VERSION "dbc-export 1 2025.20.8"

NS_ :

BS_:

BU_: APP APS DAS EPAS3S EPASTS ESP GTW IBST IDB PARK RADC RCM RCM3 RCU TPMS USM

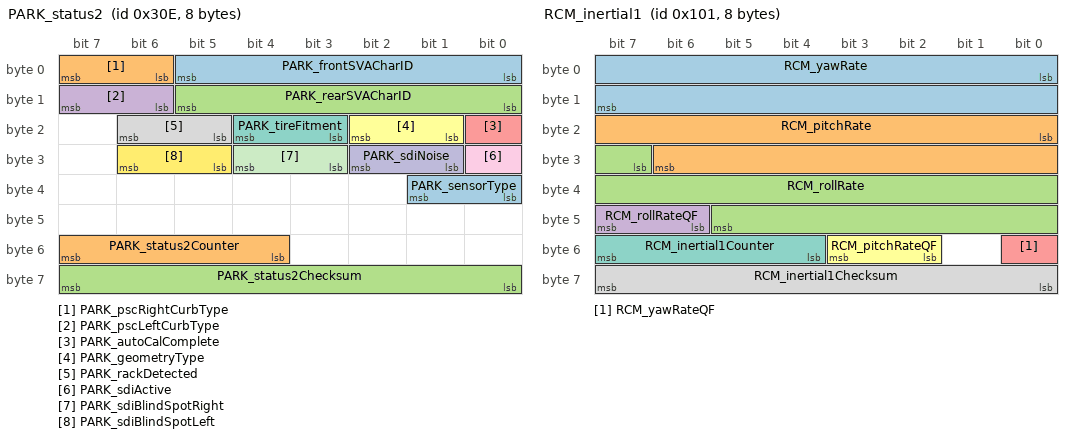
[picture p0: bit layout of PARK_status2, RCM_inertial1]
BO_ 782 PARK_status2: 8 PARK
 SG_ PARK_frontSVACharID : 0|6@1+ (1,0) [0|63] "" Vector__XXX
 SG_ PARK_pscRightCurbType : 6|2@1+ (1,0) [0|3] "" Vector__XXX
 SG_ PARK_rearSVACharID : 8|6@1+ (1,0) [0|63] "" Vector__XXX
 SG_ PARK_pscLeftCurbType : 14|2@1+ (1,0) [0|3] "" Vector__XXX
 SG_ PARK_autoCalComplete : 16|1@1+ (1,0) [0|1] "" Vector__XXX
 SG_ PARK_geometryType : 17|2@1+ (1,0) [0|3] "" Vector__XXX
 SG_ PARK_tireFitment : 19|2@1+ (1,0) [0|2] "" Vector__XXX
 SG_ PARK_rackDetected : 21|2@1+ (1,0) [0|2] "" Vector__XXX
 SG_ PARK_sdiActive : 24|1@1+ (1,0) [0|1] "" Vector__XXX
 SG_ PARK_sdiNoise : 25|2@1+ (1,0) [0|2] "" Vector__XXX
 SG_ PARK_sdiBlindSpotRight : 27|2@1+ (1,0) [0|2] "" Vector__XXX
 SG_ PARK_sdiBlindSpotLeft : 29|2@1+ (1,0) [0|2] "" Vector__XXX
 SG_ PARK_sensorType : 32|2@1+ (1,0) [0|2] "" Vector__XXX
 SG_ PARK_status2Counter : 52|4@1+ (1,0) [0|15] "" Vector__XXX
 SG_ PARK_status2Checksum : 56|8@1+ (1,0) [0|255] "" Vector__XXX

BO_ 894 PARK_warningMatrix: 8 PARK
 SG_ PARK_matrixIndex M : 0|4@1+ (1,0) [0|15] "" Vector__XXX
 SG_ PARK_a001_s1_overTemp m0 : 4|1@1+ (1,0) [0|1] "" Vector__XXX
 SG_ PARK_a002_s1_internalFail m0 : 5|1@1+ (1,0) [0|1] "" Vector__XXX
 SG_ PARK_a003_s1_linCommError m0 : 6|1@1+ (1,0) [0|1] "" Vector__XXX
 SG_ PARK_a004_s1_blocked m0 : 7|1@1+ (1,0) [0|1] "" Vector__XXX
 SG_ PARK_a005_s1_crossTalk m0 : 8|1@1+ (1,0) [0|1] "" Vector__XXX
 SG_ PARK_a006_s2_overTemp m0 : 9|1@1+ (1,0) [0|1] "" Vector__XXX
 SG_ PARK_a007_s2_internalFail m0 : 10|1@1+ (1,0) [0|1] "" Vector__XXX
 SG_ PARK_a008_s2_linCommError m0 : 11|1@1+ (1,0) [0|1] "" Vector__XXX
 SG_ PARK_a009_s2_blocked m0 : 12|1@1+ (1,0) [0|1] "" Vector__XXX
 SG_ PARK_a010_s2_crossTalk m0 : 13|1@1+ (1,0) [0|1] "" Vector__XXX
 SG_ PARK_a011_s3_overTemp m0 : 14|1@1+ (1,0) [0|1] "" Vector__XXX
 SG_ PARK_a012_s3_internalFail m0 : 15|1@1+ (1,0) [0|1] "" Vector__XXX
 SG_ PARK_a013_s3_linCommError m0 : 16|1@1+ (1,0) [0|1] "" Vector__XXX
 SG_ PARK_a014_s3_blocked m0 : 17|1@1+ (1,0) [0|1] "" Vector__XXX
 SG_ PARK_a015_s3_crossTalk m0 : 18|1@1+ (1,0) [0|1] "" Vector__XXX
 SG_ PARK_a016_s4_overTemp m0 : 19|1@1+ (1,0) [0|1] "" Vector__XXX
 SG_ PARK_a017_s4_internalFail m0 : 20|1@1+ (1,0) [0|1] "" Vector__XXX
 SG_ PARK_a018_s4_linCommError m0 : 21|1@1+ (1,0) [0|1] "" Vector__XXX
 SG_ PARK_a019_s4_blocked m0 : 22|1@1+ (1,0) [0|1] "" Vector__XXX
 SG_ PARK_a020_s4_crossTalk m0 : 23|1@1+ (1,0) [0|1] "" Vector__XXX
 SG_ PARK_a021_s5_overTemp m0 : 24|1@1+ (1,0) [0|1] "" Vector__XXX
 SG_ PARK_a022_s5_internalFail m0 : 25|1@1+ (1,0) [0|1] "" Vector__XXX
 SG_ PARK_a023_s5_linCommError m0 : 26|1@1+ (1,0) [0|1] "" Vector__XXX
 SG_ PARK_a024_s5_blocked m0 : 27|1@1+ (1,0) [0|1] "" Vector__XXX
 SG_ PARK_a025_s5_crossTalk m0 : 28|1@1+ (1,0) [0|1] "" Vector__XXX
 SG_ PARK_a026_s6_overTemp m0 : 29|1@1+ (1,0) [0|1] "" Vector__XXX
 SG_ PARK_a027_s6_internalFail m0 : 30|1@1+ (1,0) [0|1] "" Vector__XXX
 SG_ PARK_a028_s6_linCommError m0 : 31|1@1+ (1,0) [0|1] "" Vector__XXX
 SG_ PARK_a029_s6_blocked m0 : 32|1@1+ (1,0) [0|1] "" Vector__XXX
 SG_ PARK_a030_s6_crossTalk m0 : 33|1@1+ (1,0) [0|1] "" Vector__XXX
 SG_ PARK_a031_s7_overTemp m0 : 34|1@1+ (1,0) [0|1] "" Vector__XXX
 SG_ PARK_a032_s7_internalFail m0 : 35|1@1+ (1,0) [0|1] "" Vector__XXX
 SG_ PARK_a033_s7_linCommError m0 : 36|1@1+ (1,0) [0|1] "" Vector__XXX
 SG_ PARK_a034_s7_blocked m0 : 37|1@1+ (1,0) [0|1] "" Vector__XXX
 SG_ PARK_a035_s7_crossTalk m0 : 38|1@1+ (1,0) [0|1] "" Vector__XXX
 SG_ PARK_a036_s8_overTemp m0 : 39|1@1+ (1,0) [0|1] "" Vector__XXX
 SG_ PARK_a037_s8_internalFail m0 : 40|1@1+ (1,0) [0|1] "" Vector__XXX
 SG_ PARK_a038_s8_linCommError m0 : 41|1@1+ (1,0) [0|1] "" Vector__XXX
 SG_ PARK_a039_s8_blocked m0 : 42|1@1+ (1,0) [0|1] "" Vector__XXX
 SG_ PARK_a040_s8_crossTalk m0 : 43|1@1+ (1,0) [0|1] "" Vector__XXX
 SG_ PARK_a041_s9_overTemp m0 : 44|1@1+ (1,0) [0|1] "" Vector__XXX
 SG_ PARK_a042_s9_internalFail m0 : 45|1@1+ (1,0) [0|1] "" Vector__XXX
 SG_ PARK_a043_s9_linCommError m0 : 46|1@1+ (1,0) [0|1] "" Vector__XXX
 SG_ PARK_a044_s9_blocked m0 : 47|1@1+ (1,0) [0|1] "" Vector__XXX
 SG_ PARK_a045_s9_crossTalk m0 : 48|1@1+ (1,0) [0|1] "" Vector__XXX
 SG_ PARK_a046_s10_overTemp m0 : 49|1@1+ (1,0) [0|1] "" Vector__XXX
 SG_ PARK_a047_s10_internalFail m0 : 50|1@1+ (1,0) [0|1] "" Vector__XXX
 SG_ PARK_a048_s10_linCommError m0 : 51|1@1+ (1,0) [0|1] "" Vector__XXX
 SG_ PARK_a049_s10_blocked m0 : 52|1@1+ (1,0) [0|1] "" Vector__XXX
 SG_ PARK_a050_s10_crossTalk m0 : 53|1@1+ (1,0) [0|1] "" Vector__XXX
 SG_ PARK_a051_s11_overTemp m0 : 54|1@1+ (1,0) [0|1] "" Vector__XXX
 SG_ PARK_a052_s11_internalFail m0 : 55|1@1+ (1,0) [0|1] "" Vector__XXX
 SG_ PARK_a053_s11_linCommError m0 : 56|1@1+ (1,0) [0|1] "" Vector__XXX
 SG_ PARK_a054_s11_blocked m0 : 57|1@1+ (1,0) [0|1] "" Vector__XXX
 SG_ PARK_a055_s11_crossTalk m0 : 58|1@1+ (1,0) [0|1] "" Vector__XXX
 SG_ PARK_a056_s12_overTemp m0 : 59|1@1+ (1,0) [0|1] "" Vector__XXX
 SG_ PARK_a057_s12_internalFail m0 : 60|1@1+ (1,0) [0|1] "" Vector__XXX
 SG_ PARK_a058_s12_linCommError m0 : 61|1@1+ (1,0) [0|1] "" Vector__XXX
 SG_ PARK_a059_s12_blocked m0 : 62|1@1+ (1,0) [0|1] "" Vector__XXX
 SG_ PARK_a060_s12_crossTalk m0 : 63|1@1+ (1,0) [0|1] "" Vector__XXX
 SG_ PARK_a061_ecuUnderVoltage m1 : 4|1@1+ (1,0) [0|1] "" Vector__XXX
 SG_ PARK_a062_ecuOverVoltage m1 : 5|1@1+ (1,0) [0|1] "" Vector__XXX
 SG_ PARK_a063_sensorVoltage m1 : 6|1@1+ (1,0) [0|1] "" Vector__XXX
 SG_ PARK_a064_ecuFault m1 : 7|1@1+ (1,0) [0|1] "" Vector__XXX
 SG_ PARK_a065_crcFault m1 : 8|1@1+ (1,0) [0|1] "" Vector__XXX
 SG_ PARK_a066_calibrationMissing m1 : 9|1@1+ (1,0) [0|1] "" Vector__XXX
 SG_ PARK_a067_privateCANBusOff m1 : 10|1@1+ (1,0) [0|1] "" Vector__XXX
 SG_ PARK_a068_hardwareWatchDog m1 : 11|1@1+ (1,0) [0|1] "" Vector__XXX
 SG_ PARK_a069_dasMia m1 : 12|1@1+ (1,0) [0|1] "" Vector__XXX
 SG_ PARK_a070_sccmMia m1 : 13|1@1+ (1,0) [0|1] "" Vector__XXX
 SG_ PARK_a071_diMia m1 : 14|1@1+ (1,0) [0|1] "" Vector__XXX
 SG_ PARK_a072_epasMia m1 : 15|1@1+ (1,0) [0|1] "" Vector__XXX
 SG_ PARK_a073_epbMia m1 : 16|1@1+ (1,0) [0|1] "" Vector__XXX
 SG_ PARK_a074_espMia m1 : 17|1@1+ (1,0) [0|1] "" Vector__XXX
 SG_ PARK_a075_rcmMia m1 : 18|1@1+ (1,0) [0|1] "" Vector__XXX
 SG_ PARK_a076_vcFrontMia m1 : 19|1@1+ (1,0) [0|1] "" Vector__XXX
 SG_ PARK_a077_dasError m1 : 20|1@1+ (1,0) [0|1] "" Vector__XXX
 SG_ PARK_a078_diError m1 : 21|1@1+ (1,0) [0|1] "" Vector__XXX
 SG_ PARK_a079_epasError m1 : 22|1@1+ (1,0) [0|1] "" Vector__XXX
 SG_ PARK_a080_epbError m1 : 23|1@1+ (1,0) [0|1] "" Vector__XXX
 SG_ PARK_a081_espError m1 : 24|1@1+ (1,0) [0|1] "" Vector__XXX
 SG_ PARK_a082_rcmError m1 : 25|1@1+ (1,0) [0|1] "" Vector__XXX
 SG_ PARK_a083_vcFrontError m1 : 26|1@1+ (1,0) [0|1] "" Vector__XXX
 SG_ PARK_a084_sccmError m1 : 27|1@1+ (1,0) [0|1] "" Vector__XXX
 SG_ PARK_a085_watchdogReset m1 : 28|1@1+ (1,0) [0|1] "" Vector__XXX
 SG_ PARK_a086_nvmFault m1 : 29|1@1+ (1,0) [0|1] "" Vector__XXX
 SG_ PARK_a087_sensorMismatchError m1 : 30|1@1+ (1,0) [0|1] "" Vector__XXX

BO_ 1365 RADC_alertLog: 8 RADC
 SG_ RADC_alertID M : 0|6@1+ (1,0) [0|63] "" Vector__XXX
 SG_ RADC_alertState : 15|1@1+ (1,0) [0|1] "" Vector__XXX
 SG_ RADC_a002_ecuAdcErrType m2 : 16|8@1+ (1,0) [0|255] "" Vector__XXX
 SG_ RADC_a008_interLockErrType m8 : 16|8@1+ (1,0) [0|255] "" Vector__XXX
 SG_ RADC_a011_ecuMcemErrType m11 : 16|8@1+ (1,0) [0|255] "" Vector__XXX
 SG_ RADC_a013_ecuWdgErrType m13 : 16|8@1+ (1,0) [0|255] "" Vector__XXX
 SG_ RADC_a016_adcOverVoltType m16 : 16|8@1+ (1,0) [0|255] "" Vector__XXX
 SG_ RADC_a016_adcVoltage m16 : 24|6@1+ (0.1,0) [0|6.3] "v" Vector__XXX
 SG_ RADC_a017_adcUnderVoltType m17 : 16|8@1+ (1,0) [0|255] "" Vector__XXX
 SG_ RADC_a017_adcVoltage m17 : 24|6@1+ (0.1,0) [0|6.3] "v" Vector__XXX
 SG_ RADC_a019_internalSWFaultType m19 : 16|8@1+ (1,0) [0|255] "" Vector__XXX
 SG_ RADC_a019_internalSWFaultCoreID m19 : 24|4@1+ (1,0) [0|15] "" Vector__XXX
 SG_ RADC_a020_ecuTemp m20 : 16|16@1+ (0.1,-44) [-44|6509.5] "deg" Vector__XXX
 SG_ RADC_a023_ecuTemp m23 : 16|16@1+ (0.1,-44) [-44|6509.5] "deg" Vector__XXX
 SG_ RADC_a025_ecuVoltage m25 : 16|8@1+ (0.1,0) [0|25.5] "v" Vector__XXX
 SG_ RADC_a026_ecuVoltage m26 : 16|8@1+ (0.1,0) [0|25.5] "v" Vector__XXX
 SG_ RADC_a027_nvmFailureType m27 : 16|8@1+ (1,0) [0|255] "" Vector__XXX
 SG_ RADC_a028_rfComRegCheckFail m28 : 16|8@1+ (1,0) [0|255] "" Vector__XXX
 SG_ RADC_a029_rhcChirpMonErrType m29 : 16|8@1+ (1,0) [0|255] "" Vector__XXX
 SG_ RADC_a029_rhcRxLongTermErrType m29 : 24|8@1+ (1,0) [0|255] "" Vector__XXX
 SG_ RADC_a029_rhcRxErrType m29 : 32|8@1+ (1,0) [0|255] "" Vector__XXX
 SG_ RADC_a029_rhcVcoPowerErrType m29 : 40|8@1+ (1,0) [0|255] "" Vector__XXX
 SG_ RADC_a029_rhcSp1ErrType m29 : 48|8@1+ (1,0) [0|255] "" Vector__XXX
 SG_ RADC_a029_rhcFdcErrType m29 : 56|8@1+ (1,0) [0|255] "" Vector__XXX
 SG_ RADC_a030_rspErrType m30 : 16|8@1+ (1,0) [0|255] "" Vector__XXX
 SG_ RADC_a031_horizMisalignAngle m31 : 16|8@1+ (0.001953125,-0.25) [-0.25|0.248046875] "rad" Vector__XXX
 SG_ RADC_a031_vertMisalignAngle m31 : 24|12@1+ (0.0001220703125,-0.25) [-0.25|0.249877929688] "rad" Vector__XXX
 SG_ RADC_a032_blockageType m32 : 16|8@1+ (1,0) [0|255] "" Vector__XXX
 SG_ RADC_a032_block_SPMBlockageState m32 : 24|3@1+ (1,0) [0|7] "" Vector__XXX
 SG_ RADC_a032_block_dummy m32 : 27|3@1+ (1,0) [0|7] "" Vector__XXX
 SG_ RADC_a032_block_SPMSelfTestState m32 : 30|2@1+ (1,0) [0|3] "" Vector__XXX
 SG_ RADC_a032_block_ucEstiRange m32 : 32|8@1+ (1,0) [0|255] "m" Vector__XXX
 SG_ RADC_a032_block_ucEstiRangeConf m32 : 40|8@1+ (1,0) [0|255] "" Vector__XXX
 SG_ RADC_a032_block_ucEstiRangeProb m32 : 48|8@1+ (1,0) [0|255] "" Vector__XXX
 SG_ RADC_a032_block_ucTimeoutBlkConf m32 : 56|8@1+ (1,0) [0|255] "" Vector__XXX
 SG_ RADC_a035_msgId m35 : 16|12@1+ (1,0) [0|4095] "" Vector__XXX
 SG_ RADC_a036_msgId m36 : 16|12@1+ (1,0) [0|4095] "" Vector__XXX
 SG_ RADC_a037_msgId m37 : 16|12@1+ (1,0) [0|4095] "" Vector__XXX
 SG_ RADC_a038_msgId m38 : 16|12@1+ (1,0) [0|4095] "" Vector__XXX
 SG_ RADC_a039_msgId m39 : 16|12@1+ (1,0) [0|4095] "" Vector__XXX
 SG_ RADC_a040_msgId m40 : 16|12@1+ (1,0) [0|4095] "" Vector__XXX
 SG_ RADC_a041_vinErrType m41 : 16|4@1+ (1,0) [0|15] "" Vector__XXX
 SG_ RADC_a041_vinErrExp m41 : 20|16@1+ (1,0) [0|65535] "" Vector__XXX
 SG_ RADC_a041_vinErrRx m41 : 36|16@1+ (1,0) [0|65535] "" Vector__XXX
 SG_ RADC_a041_msgId m41 : 52|12@1+ (1,0) [0|4095] "" Vector__XXX
 SG_ RADC_a042_carConfigErrType m42 : 16|4@1+ (1,0) [0|15] "" Vector__XXX
 SG_ RADC_a042_carConfigErrExp m42 : 20|16@1+ (1,0) [0|65535] "" Vector__XXX
 SG_ RADC_a042_carConfigErrRx m42 : 36|16@1+ (1,0) [0|65535] "" Vector__XXX
 SG_ RADC_a042_msgId m42 : 52|12@1+ (1,0) [0|4095] "" Vector__XXX
 SG_ RADC_a043_inertialSignalsErrType m43 : 16|4@1+ (1,0) [0|15] "" Vector__XXX
 SG_ RADC_a043_inertialSignalsErrExp m43 : 20|16@1+ (1,0) [0|65535] "" Vector__XXX
 SG_ RADC_a043_inertialSignalsErrRx m43 : 36|16@1+ (1,0) [0|65535] "" Vector__XXX
 SG_ RADC_a043_msgId m43 : 52|12@1+ (1,0) [0|4095] "" Vector__XXX
 SG_ RADC_a044_stwAngleErrType m44 : 16|4@1+ (1,0) [0|15] "" Vector__XXX
 SG_ RADC_a044_stwAngleErrExp m44 : 20|16@1+ (1,0) [0|65535] "" Vector__XXX
 SG_ RADC_a044_stwAngleErrRx m44 : 36|16@1+ (1,0) [0|65535] "" Vector__XXX
 SG_ RADC_a044_msgId m44 : 52|12@1+ (1,0) [0|4095] "" Vector__XXX
 SG_ RADC_a045_vehicleStateErrType m45 : 16|4@1+ (1,0) [0|15] "" Vector__XXX
 SG_ RADC_a045_vehicleStateErrExp m45 : 20|16@1+ (1,0) [0|65535] "" Vector__XXX
 SG_ RADC_a045_vehicleStateErrRx m45 : 36|16@1+ (1,0) [0|65535] "" Vector__XXX
 SG_ RADC_a045_msgId m45 : 52|12@1+ (1,0) [0|4095] "" Vector__XXX
 SG_ RADC_a046_wheelSpeedsErrType m46 : 16|4@1+ (1,0) [0|15] "" Vector__XXX
 SG_ RADC_a046_wheelSpeedsErrExp m46 : 20|16@1+ (1,0) [0|65535] "" Vector__XXX
 SG_ RADC_a046_wheelSpeedsErrRx m46 : 36|16@1+ (1,0) [0|65535] "" Vector__XXX
 SG_ RADC_a046_msgId m46 : 52|12@1+ (1,0) [0|4095] "" Vector__XXX
 SG_ RADC_a047_chassisTypeExp m47 : 16|8@1+ (1,0) [0|255] "" Vector__XXX
 SG_ RADC_a047_chassisTypeRx m47 : 24|8@1+ (1,0) [0|255] "" Vector__XXX
 SG_ RADC_a048_airSuspensionExp m48 : 16|8@1+ (1,0) [0|255] "" Vector__XXX
 SG_ RADC_a048_airSuspensionRx m48 : 24|8@1+ (1,0) [0|255] "" Vector__XXX
 SG_ RADC_a049_fourWheelDriveExp m49 : 16|8@1+ (1,0) [0|255] "" Vector__XXX
 SG_ RADC_a049_fourWheelDriveRx m49 : 24|8@1+ (1,0) [0|255] "" Vector__XXX
 SG_ RADC_a050_countryExp m50 : 16|16@1+ (1,0) [0|65535] "" Vector__XXX
 SG_ RADC_a050_countryRx m50 : 32|16@1+ (1,0) [0|65535] "" Vector__XXX
 SG_ RADC_a051_epasTypeExp m51 : 16|8@1+ (1,0) [0|255] "" Vector__XXX
 SG_ RADC_a051_epasTypeRx m51 : 24|8@1+ (1,0) [0|255] "" Vector__XXX
 SG_ RADC_a052_radarPositionExp m52 : 16|8@1+ (1,0) [0|255] "" Vector__XXX
 SG_ RADC_a052_radarPositionRx m52 : 24|8@1+ (1,0) [0|255] "" Vector__XXX
 SG_ RADC_a054_block_ucObjLossProb m54 : 16|8@1+ (1,0) [0|255] "" Vector__XXX
 SG_ RADC_a054_block_ucObjLossConf m54 : 24|8@1+ (1,0) [0|255] "" Vector__XXX
 SG_ RADC_a054_block_ucOverallProb m54 : 32|8@1+ (1,0) [0|255] "" Vector__XXX
 SG_ RADC_a054_block_ucOverallConf m54 : 40|8@1+ (1,0) [0|255] "" Vector__XXX
 SG_ RADC_a054_block_RoadbeamTimeCnt m54 : 48|16@1+ (1,0) [0|65535] "s" Vector__XXX
 SG_ RADC_a055_block_usTimeoutWayCnt m55 : 16|16@1+ (1,0) [0|65535] "m" Vector__XXX
 SG_ RADC_a055_block_ucTimeoutTimeCnt m55 : 32|8@1+ (1,0) [0|255] "s" Vector__XXX
 SG_ RADC_a055_bblock_ucTimeoutBlkPro m55 : 40|8@1+ (1,0) [0|255] "" Vector__XXX
 SG_ RADC_a055_block_usFullBlkTimer m55 : 48|16@1+ (1,0) [0|65535] "s" Vector__XXX

BO_ 1282 RADC_alertMatrix0: 8 RADC
 SG_ RADC_a001_can1BusOff : 1|1@1+ (1,0) [0|1] "" Vector__XXX
 SG_ RADC_a002_ecuAdcError : 2|1@1+ (1,0) [0|1] "" Vector__XXX
 SG_ RADC_a003_ecuBistDisabled : 3|1@1+ (1,0) [0|1] "" Vector__XXX
 SG_ RADC_a004_ecuCrcHwError : 4|1@1+ (1,0) [0|1] "" Vector__XXX
 SG_ RADC_a005_ecuEcuMError : 5|1@1+ (1,0) [0|1] "" Vector__XXX
 SG_ RADC_a006_ecuFimError : 6|1@1+ (1,0) [0|1] "" Vector__XXX
 SG_ RADC_a007_ecuGptCheckError : 7|1@1+ (1,0) [0|1] "" Vector__XXX
 SG_ RADC_a008_ecuHwSwInterlock : 8|1@1+ (1,0) [0|1] "" Vector__XXX
 SG_ RADC_a009_plantModeActive : 9|1@1+ (1,0) [0|1] "" Vector__XXX
 SG_ RADC_a010_ecuIoHwAbError : 10|1@1+ (1,0) [0|1] "" Vector__XXX
 SG_ RADC_a011_ecuMcemError : 11|1@1+ (1,0) [0|1] "" Vector__XXX
 SG_ RADC_a012_ecuSpiError : 12|1@1+ (1,0) [0|1] "" Vector__XXX
 SG_ RADC_a013_ecuWdgError : 13|1@1+ (1,0) [0|1] "" Vector__XXX
 SG_ RADC_a014_fctSelfTestNotDone : 14|1@1+ (1,0) [0|1] "" Vector__XXX
 SG_ RADC_a015_fctSenInterference : 15|1@1+ (1,0) [0|1] "" Vector__XXX
 SG_ RADC_a016_adcOverVolt : 16|1@1+ (1,0) [0|1] "" Vector__XXX
 SG_ RADC_a017_adcUnderVolt : 17|1@1+ (1,0) [0|1] "" Vector__XXX
 SG_ RADC_a018_internalHardwareFault : 18|1@1+ (1,0) [0|1] "" Vector__XXX
 SG_ RADC_a019_internalSoftwareFault : 19|1@1+ (1,0) [0|1] "" Vector__XXX
 SG_ RADC_a020_overTemp : 20|1@1+ (1,0) [0|1] "" Vector__XXX
 SG_ RADC_a021_overTempCrit : 21|1@1+ (1,0) [0|1] "" Vector__XXX
 SG_ RADC_a022_tempImplausible : 22|1@1+ (1,0) [0|1] "" Vector__XXX
 SG_ RADC_a023_underTemp : 23|1@1+ (1,0) [0|1] "" Vector__XXX
 SG_ RADC_a024_underTempCrit : 24|1@1+ (1,0) [0|1] "" Vector__XXX
 SG_ RADC_a025_overVoltage : 25|1@1+ (1,0) [0|1] "" Vector__XXX
 SG_ RADC_a026_underVoltage : 26|1@1+ (1,0) [0|1] "" Vector__XXX
 SG_ RADC_a027_nvmFailure : 27|1@1+ (1,0) [0|1] "" Vector__XXX
 SG_ RADC_a028_rfChipError : 28|1@1+ (1,0) [0|1] "" Vector__XXX
 SG_ RADC_a029_rhcError : 29|1@1+ (1,0) [0|1] "" Vector__XXX
 SG_ RADC_a030_rspError : 30|1@1+ (1,0) [0|1] "" Vector__XXX
 SG_ RADC_a031_sensorMisaligned : 31|1@1+ (1,0) [0|1] "" Vector__XXX
 SG_ RADC_a032_sensorBlocked : 32|1@1+ (1,0) [0|1] "" Vector__XXX
 SG_ RADC_a033_sensorNeverAligned : 33|1@1+ (1,0) [0|1] "" Vector__XXX
 SG_ RADC_a034_vehDynamicsError : 34|1@1+ (1,0) [0|1] "" Vector__XXX
 SG_ RADC_a035_vinMIA : 35|1@1+ (1,0) [0|1] "" Vector__XXX
 SG_ RADC_a036_carConfigMIA : 36|1@1+ (1,0) [0|1] "" Vector__XXX
 SG_ RADC_a037_inertialSignalsMIA : 37|1@1+ (1,0) [0|1] "" Vector__XXX
 SG_ RADC_a038_steeringWheelAngleMIA : 38|1@1+ (1,0) [0|1] "" Vector__XXX
 SG_ RADC_a039_vehicleStateMIA : 39|1@1+ (1,0) [0|1] "" Vector__XXX
 SG_ RADC_a040_wheelSpeedsMIA : 40|1@1+ (1,0) [0|1] "" Vector__XXX
 SG_ RADC_a041_vinErr : 41|1@1+ (1,0) [0|1] "" Vector__XXX
 SG_ RADC_a042_carConfigErr : 42|1@1+ (1,0) [0|1] "" Vector__XXX
 SG_ RADC_a043_inertialSignalsErr : 43|1@1+ (1,0) [0|1] "" Vector__XXX
 SG_ RADC_a044_steeringWheelAngleErr : 44|1@1+ (1,0) [0|1] "" Vector__XXX
 SG_ RADC_a045_vehicleStateErr : 45|1@1+ (1,0) [0|1] "" Vector__XXX
 SG_ RADC_a046_wheelSpeedsErr : 46|1@1+ (1,0) [0|1] "" Vector__XXX
 SG_ RADC_a047_mismatchChassisType : 47|1@1+ (1,0) [0|1] "" Vector__XXX
 SG_ RADC_a048_mismatchAirSuspension : 48|1@1+ (1,0) [0|1] "" Vector__XXX
 SG_ RADC_a049_mismatchFourWheelDrive : 49|1@1+ (1,0) [0|1] "" Vector__XXX
 SG_ RADC_a050_mismatchCountry : 50|1@1+ (1,0) [0|1] "" Vector__XXX
 SG_ RADC_a051_mismatchEPASType : 51|1@1+ (1,0) [0|1] "" Vector__XXX
 SG_ RADC_a052_mismatcRadPos : 52|1@1+ (1,0) [0|1] "" Vector__XXX
 SG_ RADC_a053_emError : 53|1@1+ (1,0) [0|1] "" Vector__XXX
 SG_ RADC_a054_blockageInfo_Frame_1 : 54|1@1+ (1,0) [0|1] "" Vector__XXX
 SG_ RADC_a055_blockageInfo_Frame_2 : 55|1@1+ (1,0) [0|1] "" Vector__XXX

BO_ 1329 RADC_info: 8 RADC
 SG_ RADC_infoIndex M : 0|8@1+ (1,0) [0|255] "" Vector__XXX
 SG_ RADC_infoBuildType m10 : 8|8@1+ (1,0) [0|255] "" Vector__XXX
 SG_ RADC_infoBuildConfigID m10 : 16|16@1+ (1,0) [0|65535] "" Vector__XXX
 SG_ RADC_infoHardwareID m10 : 32|16@1+ (1,0) [0|65535] "" Vector__XXX
 SG_ RADC_infoComponentID m10 : 48|16@1+ (1,0) [0|65535] "" Vector__XXX
 SG_ RADC_infoPcbaID m11 : 16|8@1+ (1,0) [0|255] "" Vector__XXX
 SG_ RADC_infoAssemblyID m11 : 24|8@1+ (1,0) [0|255] "" Vector__XXX
 SG_ RADC_infoUsageID m11 : 32|16@1+ (1,0) [0|65535] "" Vector__XXX
 SG_ RADC_infoSubUsageID m11 : 48|16@1+ (1,0) [0|65535] "" Vector__XXX
 SG_ RADC_infoApplicationCRC m13 : 32|32@1+ (1,0) [0|4294967295] "" Vector__XXX
 SG_ RADC_infoPlatformType m19 : 8|8@1+ (1,0) [0|255] "" Vector__XXX
 SG_ RADC_infoMajorVersion m19 : 16|8@1+ (1,0) [0|255] "" Vector__XXX
 SG_ RADC_infoBranchOrigin m19 : 24|8@1+ (1,0) [0|255] "" Vector__XXX
 SG_ RADC_infoMaturity m19 : 32|8@1+ (1,0) [0|255] "" Vector__XXX
 SG_ RADC_infoHardwareRevision m19 : 40|8@1+ (1,0) [0|255] "" Vector__XXX
 SG_ RADC_infoBootUdsProtoVersion m20 : 8|8@1+ (1,0) [0|255] "" Vector__XXX
 SG_ RADC_infoBootloaderCRC m20 : 32|32@1+ (1,0) [0|4294967295] "" Vector__XXX

BO_ 1252 RCM3_alertLog: 8 RCM3
 SG_ RCM3_alertID : 0|1@1+ (1,0) [0|1] "" Vector__XXX
 SG_ RCM3_alertState : 15|1@1+ (1,0) [0|1] "" Vector__XXX

BO_ 1010 RCM3_alertMatrix: 8 RCM3
 SG_ RCM3_matrixIndex M : 0|4@1+ (1,0) [0|15] "" Vector__XXX
 SG_ RCM3_a001_LVPowerLossDetected m0 : 4|1@1+ (1,0) [0|1] "" Vector__XXX

BO_ 257 RCM_inertial1: 8 RCM
 SG_ RCM_yawRate : 0|16@1- (0.0001,0) [-3.2766|3.2766] "rad/s" Vector__XXX
 SG_ RCM_pitchRate : 16|15@1- (0.00025,0) [-4.096|4.09575] "rad/s" Vector__XXX
 SG_ RCM_rollRate : 31|15@1- (0.00025,0) [-4.096|4.09575] "rad/s" Vector__XXX
 SG_ RCM_rollRateQF : 46|2@1+ (1,0) [0|3] "" Vector__XXX
 SG_ RCM_yawRateQF : 48|1@1+ (1,0) [0|1] "" Vector__XXX
 SG_ RCM_pitchRateQF : 50|2@1+ (1,0) [0|3] "" Vector__XXX
 SG_ RCM_inertial1Counter : 52|4@1+ (1,0) [0|15] "" Vector__XXX
 SG_ RCM_inertial1Checksum : 56|8@1+ (1,0) [0|255] "" Vector__XXX

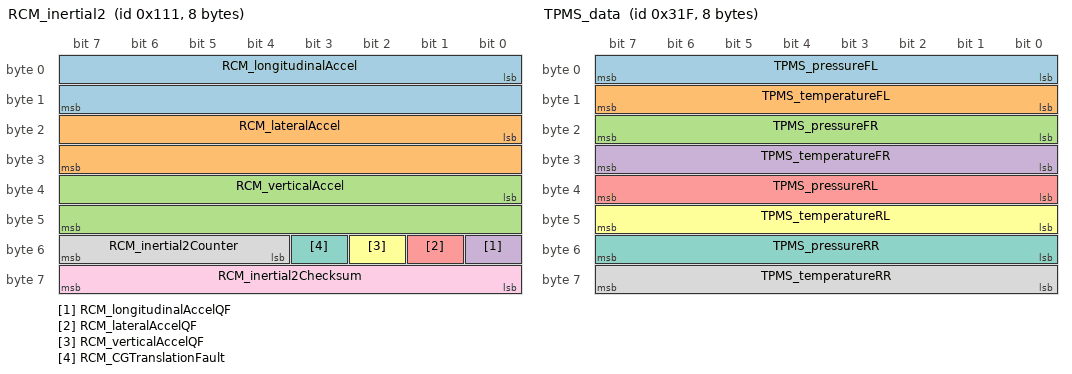
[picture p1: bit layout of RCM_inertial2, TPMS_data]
BO_ 273 RCM_inertial2: 8 RCM
 SG_ RCM_longitudinalAccel : 0|16@1- (0.00125,0) [-40.9575|40.9575] "m/s^2" Vector__XXX
 SG_ RCM_lateralAccel : 16|16@1- (0.00125,0) [-40.9575|40.9575] "m/s^2" Vector__XXX
 SG_ RCM_verticalAccel : 32|16@1- (0.00125,0) [-40.9575|39.2] "m/s^2" Vector__XXX
 SG_ RCM_longitudinalAccelQF : 48|1@1+ (1,0) [0|1] "" Vector__XXX
 SG_ RCM_lateralAccelQF : 49|1@1+ (1,0) [0|1] "" Vector__XXX
 SG_ RCM_verticalAccelQF : 50|1@1+ (1,0) [0|1] "" Vector__XXX
 SG_ RCM_CGTranslationFault : 51|1@1+ (1,0) [0|1] "" Vector__XXX
 SG_ RCM_inertial2Counter : 52|4@1+ (1,0) [0|15] "" Vector__XXX
 SG_ RCM_inertial2Checksum : 56|8@1+ (1,0) [0|255] "" Vector__XXX

BO_ 849 RCM_info: 8 RCM
 SG_ RCM_infoIndex M : 0|8@1+ (1,0) [0|255] "" Vector__XXX
 SG_ RCM_infoBuildType m10 : 8|8@1+ (1,0) [0|255] "" Vector__XXX
 SG_ RCM_infoComponentID m10 : 48|16@1+ (1,0) [0|65535] "" Vector__XXX
 SG_ RCM_infoPcbaID m11 : 16|8@1+ (1,0) [0|255] "" Vector__XXX
 SG_ RCM_infoAssemblyID m11 : 24|8@1+ (1,0) [0|255] "" Vector__XXX
 SG_ RCM_infoUsageID m11 : 32|16@1+ (1,0) [0|65535] "" Vector__XXX
 SG_ RCM_infoApplicationCRC m13 : 32|32@1+ (1,0) [0|4294967295] "" Vector__XXX
 SG_ RCM_infoBootUdsProtoVersion m20 : 8|8@1+ (1,0) [0|255] "" Vector__XXX
 SG_ RCM_infoBootloaderCRC m20 : 32|32@1+ (1,0) [0|4294967295] "" Vector__XXX
 SG_ RCM_infoAlgoCalID m22 : 8|8@1+ (1,0) [0|255] "" Vector__XXX
 SG_ RCM_infoVariantCRC m22 : 32|32@1+ (1,0) [0|4294967295] "" Vector__XXX

BO_ 529 RCM_status: 6 RCM
 SG_ RCM_statusChecksum : 0|8@1+ (1,0) [0|255] "" Vector__XXX
 SG_ RCM_statusCounter : 8|4@1+ (1,0) [0|15] "" Vector__XXX
 SG_ RCM_armStatus : 12|2@1+ (1,0) [0|2] "" Vector__XXX
 SG_ RCM_warningIndicatorState : 14|2@1+ (1,0) [0|2] "" Vector__XXX
 SG_ RCM_passAirbagIndicatorRequest : 16|2@1+ (1,0) [0|2] "" Vector__XXX
 SG_ RCM_airbagCutoffStatus : 18|2@1+ (1,0) [0|2] "" Vector__XXX
 SG_ RCM_alrSwitchStatus : 20|2@1+ (1,0) [0|2] "" Vector__XXX
 SG_ RCM_vinLearnFlag : 22|2@1+ (1,0) [0|2] "" Vector__XXX
 SG_ RCM_seatTrackPositionDrvr : 24|2@1+ (1,0) [0|2] "" Vector__XXX
 SG_ RCM_seatTrackPositionPass : 26|2@1+ (1,0) [0|2] "" Vector__XXX
 SG_ RCM_edr1State : 28|2@1+ (1,0) [0|3] "" Vector__XXX
 SG_ RCM_edr2State : 30|2@1+ (1,0) [0|3] "" Vector__XXX
 SG_ RCM_keepPowerReason : 32|4@1+ (1,0) [0|15] "" Vector__XXX
 SG_ RCM_imuOffsetLearnState : 36|2@1+ (1,0) [0|3] "" Vector__XXX
 SG_ RCM_edr3State : 38|2@1+ (1,0) [0|3] "" Vector__XXX
 SG_ RCM_driverOrientationInitStatus : 40|3@1+ (1,0) [0|6] "" Vector__XXX
 SG_ RCM_occupantClassificationSource : 43|1@1+ (1,0) [0|1] "" Vector__XXX
 SG_ RCM_pedProEDR1State : 44|2@1+ (1,0) [0|3] "" Vector__XXX
 SG_ RCM_pedProEDR2State : 46|2@1+ (1,0) [0|3] "" Vector__XXX

BO_ 831 RCU_info: 8 RCU
 SG_ RCU_infoIndex M : 0|8@1+ (1,0) [0|255] "" Vector__XXX
 SG_ RCU_infoPcbaID m11 : 16|8@1+ (1,0) [0|255] "" Vector__XXX
 SG_ RCU_infoAssemblyID m11 : 24|8@1+ (1,0) [0|255] "" Vector__XXX
 SG_ RCU_infoUsageID m11 : 32|16@1+ (1,0) [0|65535] "" Vector__XXX
 SG_ RCU_infoSubUsageID m11 : 48|16@1+ (1,0) [0|65535] "" Vector__XXX

BO_ 879 TPMS_StatusC: 8 TPMS
 SG_ TPMS_c_globalHardWarning : 0|1@1+ (1,0) [0|1] "" Vector__XXX
 SG_ TPMS_c_globalSoftWarning : 1|1@1+ (1,0) [0|1] "" Vector__XXX
 SG_ TPMS_systemMalfunction : 2|1@1+ (1,0) [0|1] "" Vector__XXX
 SG_ TPMS_WA_version : 3|1@1+ (1,0) [0|1] "" Vector__XXX
 SG_ TPMS_globalDeltaPressure : 4|1@1+ (1,0) [0|1] "" Vector__XXX
 SG_ TPMS_newSensorLearnt : 5|3@1+ (1,0) [0|7] "" Vector__XXX
 SG_ TPMS_softWarningRR : 8|1@1+ (1,0) [0|1] "" Vector__XXX
 SG_ TPMS_hardWarningRR : 9|1@1+ (1,0) [0|1] "" Vector__XXX
 SG_ TPMS_softWarningRL : 10|1@1+ (1,0) [0|1] "" Vector__XXX
 SG_ TPMS_hardWarningRL : 11|1@1+ (1,0) [0|1] "" Vector__XXX
 SG_ TPMS_softWarningFR : 12|1@1+ (1,0) [0|1] "" Vector__XXX
 SG_ TPMS_hardWarningFR : 13|1@1+ (1,0) [0|1] "" Vector__XXX
 SG_ TPMS_softWarningFL : 14|1@1+ (1,0) [0|1] "" Vector__XXX
 SG_ TPMS_hardWarningFL : 15|1@1+ (1,0) [0|1] "" Vector__XXX
 SG_ TPMS_learningStatus : 16|2@1+ (1,0) [0|3] "" Vector__XXX
 SG_ TPMS_localisationStatus : 18|2@1+ (1,0) [0|3] "" Vector__XXX
 SG_ TPMS_deltaPressWarningFL : 20|1@1+ (1,0) [0|1] "" Vector__XXX
 SG_ TPMS_deltaPressWarningFR : 21|1@1+ (1,0) [0|1] "" Vector__XXX
 SG_ TPMS_deltaPressWarningRL : 22|1@1+ (1,0) [0|1] "" Vector__XXX
 SG_ TPMS_deltaPressWarningRR : 23|1@1+ (1,0) [0|1] "" Vector__XXX
 SG_ TPMS_sensorNoResponseFL : 24|1@1+ (1,0) [0|1] "" Vector__XXX
 SG_ TPMS_sensorNoResponseFR : 25|1@1+ (1,0) [0|1] "" Vector__XXX
 SG_ TPMS_sensorNoResponseRL : 26|1@1+ (1,0) [0|1] "" Vector__XXX
 SG_ TPMS_sensorNoResponseRR : 27|1@1+ (1,0) [0|1] "" Vector__XXX
 SG_ TPMS_sensorThermShutdownFL : 28|1@1+ (1,0) [0|1] "" Vector__XXX
 SG_ TPMS_sensorThermShutdownFR : 29|1@1+ (1,0) [0|1] "" Vector__XXX
 SG_ TPMS_sensorThermShutdownRL : 30|1@1+ (1,0) [0|1] "" Vector__XXX
 SG_ TPMS_sensorThermShutdownRR : 31|1@1+ (1,0) [0|1] "" Vector__XXX
 SG_ TPMS_sensorBatteryLowFL : 32|1@1+ (1,0) [0|1] "" Vector__XXX
 SG_ TPMS_sensorBatteryLowFR : 33|1@1+ (1,0) [0|1] "" Vector__XXX
 SG_ TPMS_sensorBatteryLowRL : 34|1@1+ (1,0) [0|1] "" Vector__XXX
 SG_ TPMS_sensorBatteryLowRR : 35|1@1+ (1,0) [0|1] "" Vector__XXX
 SG_ TPMS_sensorDefectiveFL : 36|1@1+ (1,0) [0|1] "" Vector__XXX
 SG_ TPMS_sensorDefectiveFR : 37|1@1+ (1,0) [0|1] "" Vector__XXX
 SG_ TPMS_sensorDefectiveRL : 38|1@1+ (1,0) [0|1] "" Vector__XXX
 SG_ TPMS_sensorDefectiveRR : 39|1@1+ (1,0) [0|1] "" Vector__XXX
 SG_ TPMS_ecuUnderVoltage : 40|1@1+ (1,0) [0|1] "" Vector__XXX
 SG_ TPMS_ecuOverVoltage : 41|1@1+ (1,0) [0|1] "" Vector__XXX
 SG_ TPMS_ecuRamRomNvMFail : 42|1@1+ (1,0) [0|1] "" Vector__XXX
 SG_ TPMS_rfReceiverFail : 43|1@1+ (1,0) [0|1] "" Vector__XXX
 SG_ TPMS_wheelPulseMissing : 44|1@1+ (1,0) [0|1] "" Vector__XXX
 SG_ TPMS_vehicleSpeedFail : 45|1@1+ (1,0) [0|1] "" Vector__XXX
 SG_ TPMS_externalTemperatureFail : 46|1@1+ (1,0) [0|1] "" Vector__XXX
 SG_ TPMS_eolNotCompleted : 47|1@1+ (1,0) [0|1] "" Vector__XXX
 SG_ TPMS_rcpFront : 48|8@1+ (0.025,0) [0|6.375] "bar" Vector__XXX
 SG_ TPMS_rcpRear : 56|8@1+ (0.025,0) [0|6.375] "bar" Vector__XXX

BO_ 799 TPMS_data: 8 TPMS
 SG_ TPMS_pressureFL : 0|8@1+ (0.025,0) [0|6.35] "bar" Vector__XXX
 SG_ TPMS_temperatureFL : 8|8@1+ (1,-40) [-40|214] "degC" Vector__XXX
 SG_ TPMS_pressureFR : 16|8@1+ (0.025,0) [0|6.35] "bar" Vector__XXX
 SG_ TPMS_temperatureFR : 24|8@1+ (1,-40) [-40|214] "degC" Vector__XXX
 SG_ TPMS_pressureRL : 32|8@1+ (0.025,0) [0|6.35] "bar" Vector__XXX
 SG_ TPMS_temperatureRL : 40|8@1+ (1,-40) [-40|214] "degC" Vector__XXX
 SG_ TPMS_pressureRR : 48|8@1+ (0.025,0) [0|6.35] "bar" Vector__XXX
 SG_ TPMS_temperatureRR : 56|8@1+ (1,-40) [-40|214] "degC" Vector__XXX

BO_ 1519 TPMS_info: 8 TPMS
 SG_ TPMS_infoIndex M : 0|8@1+ (1,0) [0|255] "" Vector__XXX
 SG_ TPMS_infoComponentID m10 : 48|16@1+ (1,0) [0|65535] "" Vector__XXX
 SG_ TPMS_infoPcbaID m11 : 16|8@1+ (1,0) [0|255] "" Vector__XXX
 SG_ TPMS_infoAssemblyID m11 : 24|8@1+ (1,0) [0|255] "" Vector__XXX
 SG_ TPMS_infoUsageID m11 : 32|16@1+ (1,0) [0|65535] "" Vector__XXX
 SG_ TPMS_infoApplicationCRC m13 : 32|32@1+ (1,0) [0|4294967295] "" Vector__XXX
 SG_ TPMS_infoBootUdsProtoVersion m20 : 8|8@1+ (1,0) [0|255] "" Vector__XXX
 SG_ TPMS_infoBootloaderCRC m20 : 32|32@1+ (1,0) [0|4294967295] "" Vector__XXX

BO_ 659 UI_chassisControl: 8 GTW
 SG_ UI_steeringTuneRequest : 0|2@1+ (1,0) [0|3] "" Vector__XXX
 SG_ UI_tractionControlMode : 2|3@1+ (1,0) [0|7] "" Vector__XXX
 SG_ UI_parkBrakeRequest : 5|2@1+ (1,0) [0|2] "" Vector__XXX
 SG_ UI_narrowGarages : 7|1@1+ (1,0) [0|1] "" Vector__XXX
 SG_ UI_winchModeRequest : 8|2@1+ (1,0) [0|3] "" Vector__XXX
 SG_ UI_zeroSpeedConfirmed : 10|2@1+ (1,0) [0|2] "" Vector__XXX
 SG_ UI_trailerMode : 12|1@1+ (1,0) [0|1] "" Vector__XXX
 SG_ UI_distanceUnits : 13|1@1+ (1,0) [0|1] "" Vector__XXX
 SG_ UI_dasDebugEnable : 14|1@1+ (1,0) [0|1] "" Vector__XXX
 SG_ UI_accOvertakeEnable : 16|2@1+ (1,0) [0|2] "" Vector__XXX
 SG_ UI_aebEnable : 18|2@1+ (1,0) [0|2] "" Vector__XXX
 SG_ UI_aesEnable : 20|2@1+ (1,0) [0|2] "" Vector__XXX
 SG_ UI_ahlbEnable : 22|2@1+ (1,0) [0|2] "" Vector__XXX
 SG_ UI_autoLaneChangeEnable : 24|2@1+ (1,0) [0|2] "" Vector__XXX
 SG_ UI_winchProxUserOverride : 26|1@1+ (1,0) [0|1] "" Vector__XXX
 SG_ UI_rebootAutopilot : 27|1@1+ (1,0) [0|1] "" Vector__XXX
 SG_ UI_autoParkRequest : 28|4@1+ (1,0) [0|14] "" Vector__XXX
 SG_ UI_bsdEnable : 32|2@1+ (1,0) [0|2] "" Vector__XXX
 SG_ UI_fcwEnable : 34|2@1+ (1,0) [0|2] "" Vector__XXX
 SG_ UI_fcwSensitivity : 36|2@1+ (1,0) [0|2] "" Vector__XXX
 SG_ UI_latControlEnable : 38|2@1+ (1,0) [0|2] "" Vector__XXX
 SG_ UI_ldwEnable : 40|2@1+ (1,0) [0|2] "" Vector__XXX
 SG_ UI_pedalSafetyEnable : 42|2@1+ (1,0) [0|2] "" Vector__XXX
 SG_ UI_pedalMap_epas : 44|2@1+ (1,0) [0|3] "" Vector__XXX
 SG_ UI_redLightStopSignEnable : 46|2@1+ (1,0) [0|2] "" Vector__XXX
 SG_ UI_selfParkTune : 48|4@1+ (1,0) [0|14] "" Vector__XXX
 SG_ UI_chassisControlCounter : 52|4@1+ (1,0) [0|15] "" Vector__XXX
 SG_ UI_chassisControlChecksum : 56|8@1+ (1,0) [0|255] "" Vector__XXX

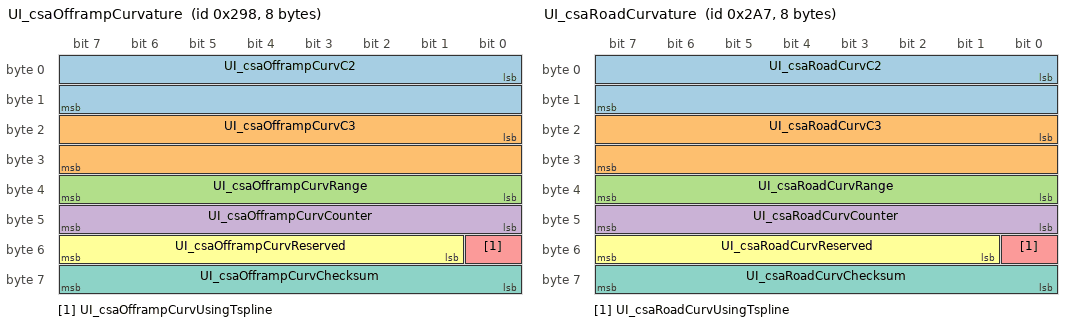
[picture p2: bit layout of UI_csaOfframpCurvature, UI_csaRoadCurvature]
BO_ 664 UI_csaOfframpCurvature: 8 GTW
 SG_ UI_csaOfframpCurvC2 : 0|16@1- (1.0e-06,0) [-0.032768|0.032767] "1/m" Vector__XXX
 SG_ UI_csaOfframpCurvC3 : 16|16@1- (4.0e-09,0) [-0.000131072|0.000131068] "1/m2" Vector__XXX
 SG_ UI_csaOfframpCurvRange : 32|8@1+ (2,0) [0|510] "m" Vector__XXX
 SG_ UI_csaOfframpCurvCounter : 40|8@1+ (1,0) [0|255] "" Vector__XXX
 SG_ UI_csaOfframpCurvUsingTspline : 48|1@1+ (1,0) [0|1] "" Vector__XXX
 SG_ UI_csaOfframpCurvReserved : 49|7@1+ (1,0) [0|127] "" Vector__XXX
 SG_ UI_csaOfframpCurvChecksum : 56|8@1+ (1,0) [0|255] "" Vector__XXX

BO_ 679 UI_csaRoadCurvature: 8 GTW
 SG_ UI_csaRoadCurvC2 : 0|16@1- (1.0e-06,0) [-0.032768|0.032767] "1/m" Vector__XXX
 SG_ UI_csaRoadCurvC3 : 16|16@1- (4.0e-09,0) [-0.000131072|0.000131068] "1/m2" Vector__XXX
 SG_ UI_csaRoadCurvRange : 32|8@1+ (2,0) [0|510] "m" Vector__XXX
 SG_ UI_csaRoadCurvCounter : 40|8@1+ (1,0) [0|255] "" Vector__XXX
 SG_ UI_csaRoadCurvUsingTspline : 48|1@1+ (1,0) [0|1] "" Vector__XXX
 SG_ UI_csaRoadCurvReserved : 49|7@1+ (1,0) [0|127] "" Vector__XXX
 SG_ UI_csaRoadCurvChecksum : 56|8@1+ (1,0) [0|255] "" Vector__XXX

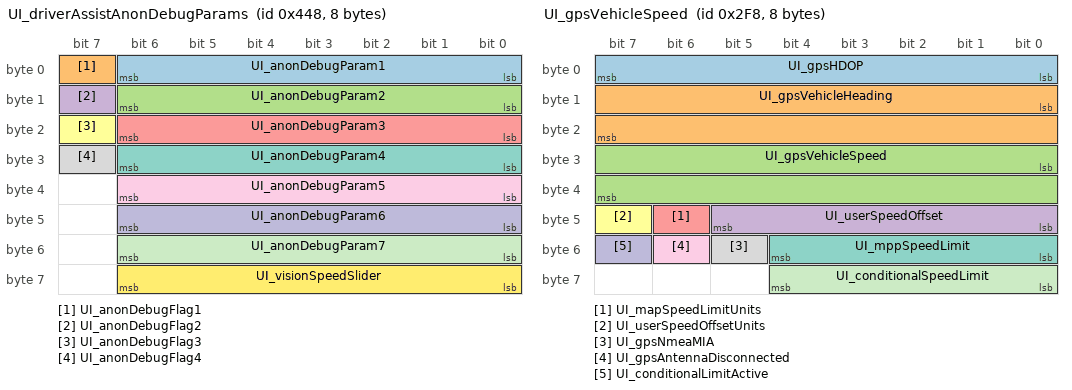
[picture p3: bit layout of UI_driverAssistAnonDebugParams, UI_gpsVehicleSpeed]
BO_ 1096 UI_driverAssistAnonDebugParams: 8 GTW
 SG_ UI_anonDebugParam1 : 0|7@1+ (1,0) [0|127] "" Vector__XXX
 SG_ UI_anonDebugFlag1 : 7|1@1+ (1,0) [0|1] "" Vector__XXX
 SG_ UI_anonDebugParam2 : 8|7@1+ (1,0) [0|127] "" Vector__XXX
 SG_ UI_anonDebugFlag2 : 15|1@1+ (1,0) [0|1] "" Vector__XXX
 SG_ UI_anonDebugParam3 : 16|7@1+ (1,0) [0|127] "" Vector__XXX
 SG_ UI_anonDebugFlag3 : 23|1@1+ (1,0) [0|1] "" Vector__XXX
 SG_ UI_anonDebugParam4 : 24|7@1+ (1,0) [0|127] "" Vector__XXX
 SG_ UI_anonDebugFlag4 : 31|1@1+ (1,0) [0|1] "" Vector__XXX
 SG_ UI_anonDebugParam5 : 32|7@1+ (1,0) [0|127] "" Vector__XXX
 SG_ UI_anonDebugParam6 : 40|7@1+ (1,0) [0|127] "" Vector__XXX
 SG_ UI_anonDebugParam7 : 48|7@1+ (1,0) [0|127] "" Vector__XXX
 SG_ UI_visionSpeedSlider : 56|7@1+ (1,0) [0|127] "" Vector__XXX

BO_ 1016 UI_driverAssistControl: 8 GTW
 SG_ UI_autopilotControlRequest : 0|1@1+ (1,0) [0|1] "" Vector__XXX
 SG_ UI_ulcStalkConfirm : 1|1@1+ (1,0) [0|1] "" Vector__XXX
 SG_ UI_summonHeartbeat : 2|2@1+ (1,0) [0|3] "" Vector__XXX
 SG_ UI_curvSpeedAdaptDisable : 4|1@1+ (1,0) [0|1] "" Vector__XXX
 SG_ UI_dasDeveloper : 5|1@1+ (1,0) [0|1] "" Vector__XXX
 SG_ UI_enableVinAssociation : 6|1@1+ (1,0) [0|1] "" Vector__XXX
 SG_ UI_lssLkaEnabled : 7|1@1+ (1,0) [0|1] "" Vector__XXX
 SG_ UI_lssLdwEnabled : 8|1@1+ (1,0) [0|1] "" Vector__XXX
 SG_ UI_coastToCoast : 9|1@1+ (1,0) [0|1] "" Vector__XXX
 SG_ UI_autoSummonEnable : 10|1@1+ (1,0) [0|1] "" Vector__XXX
 SG_ UI_exceptionListEnable : 11|1@1+ (1,0) [0|1] "" Vector__XXX
 SG_ UI_roadCheckDisable : 12|1@1+ (1,0) [0|1] "" Vector__XXX
 SG_ UI_driveOnMapsEnable : 13|1@1+ (1,0) [0|1] "" Vector__XXX
 SG_ UI_handsOnRequirementDisable : 14|1@1+ (1,0) [0|1] "" Vector__XXX
 SG_ UI_ulcOffHighway : 15|1@1+ (1,0) [0|1] "" Vector__XXX
 SG_ UI_fuseLanesDisable : 16|1@1+ (1,0) [0|1] "" Vector__XXX
 SG_ UI_fuseHPPDisable : 17|1@1+ (1,0) [0|1] "" Vector__XXX
 SG_ UI_fuseVehiclesDisable : 18|1@1+ (1,0) [0|1] "" Vector__XXX
 SG_ UI_enableClipParkedTelemetry : 19|1@1+ (1,0) [0|1] "" Vector__XXX
 SG_ UI_visionSpeedType : 20|2@1+ (1,0) [0|3] "" Vector__XXX
 SG_ UI_curvatureDatabaseOnly : 22|1@1+ (1,0) [0|1] "" Vector__XXX
 SG_ UI_lssElkEnabled : 23|1@1+ (1,0) [0|1] "" Vector__XXX
 SG_ UI_summonExitType : 24|2@1+ (1,0) [0|2] "" Vector__XXX
 SG_ UI_summonEntryType : 26|2@1+ (1,0) [0|2] "" Vector__XXX
 SG_ UI_selfParkRequest : 28|4@1+ (1,0) [0|14] "" Vector__XXX
 SG_ UI_summonReverseDist : 32|6@1+ (1,0) [0|62] "" Vector__XXX
 SG_ UI_undertakeAssistEnable : 38|1@1+ (1,0) [0|1] "" Vector__XXX
 SG_ UI_adaptiveSetSpeedEnable : 39|1@1+ (1,0) [0|1] "" Vector__XXX
 SG_ UI_drivingSide : 40|2@1+ (1,0) [0|3] "" Vector__XXX
 SG_ UI_enableClipTelemetry : 42|1@1+ (1,0) [0|1] "" Vector__XXX
 SG_ UI_enableTripTelemetry : 43|1@1+ (1,0) [0|1] "" Vector__XXX
 SG_ UI_enableRoadSegmentTelemetry : 44|1@1+ (1,0) [0|1] "" Vector__XXX
 SG_ UI_accFollowDistanceSetting : 45|3@1+ (1,0) [0|6] "" Vector__XXX
 SG_ UI_hasDriveOnNav : 48|1@1+ (1,0) [0|1] "" Vector__XXX
 SG_ UI_followNavRouteEnable : 49|1@1+ (1,0) [0|1] "" Vector__XXX
 SG_ UI_ulcSpeedConfig : 50|2@1+ (1,0) [0|3] "" Vector__XXX
 SG_ UI_ulcBlindSpotConfig : 52|2@1+ (1,0) [0|3] "" Vector__XXX
 SG_ UI_suppressExitPassingLane : 54|1@1+ (1,0) [0|1] "" Vector__XXX
 SG_ UI_enableClipStartStopTelemetry : 55|1@1+ (1,0) [0|1] "" Vector__XXX
 SG_ UI_alcOffHighwayEnable : 56|1@1+ (1,0) [0|1] "" Vector__XXX
 SG_ UI_validationLoop : 57|1@1+ (1,0) [0|1] "" Vector__XXX
 SG_ UI_smartSummonType : 58|2@1+ (1,0) [0|3] "" Vector__XXX
 SG_ UI_enableVisionOnlyStops : 60|1@1+ (1,0) [0|1] "" Vector__XXX
 SG_ UI_source3D : 61|2@1+ (1,0) [0|3] "" Vector__XXX
 SG_ UI_isaSpeedingChimeMuted : 63|1@1+ (1,0) [0|1] "" Vector__XXX

BO_ 568 UI_driverAssistMapData: 8 GTW
 SG_ UI_mapSpeedLimitDependency : 0|3@1+ (1,0) [0|6] "" Vector__XXX
 SG_ UI_roadClass : 3|3@1+ (1,0) [1|7] "" Vector__XXX
 SG_ UI_inSuperchargerGeofence : 6|1@1+ (1,0) [0|1] "" Vector__XXX
 SG_ UI_mapSpeedUnits : 7|1@1+ (1,0) [0|1] "" Vector__XXX
 SG_ UI_mapSpeedLimit : 8|5@1+ (1,0) [0|30] "" Vector__XXX
 SG_ UI_mapSpeedLimitType : 13|3@1+ (1,0) [0|6] "" Vector__XXX
 SG_ UI_countryCode : 16|10@1+ (1,0) [0|1022] "" Vector__XXX
 SG_ UI_streetCount : 26|2@1+ (1,0) [0|3] "" Vector__XXX
 SG_ UI_gpsRoadMatch : 28|1@1+ (1,0) [0|1] "" Vector__XXX
 SG_ UI_navRouteActive : 29|1@1+ (1,0) [0|1] "" Vector__XXX
 SG_ UI_parallelAutoparkEnabled : 30|1@1+ (1,0) [0|1] "" Vector__XXX
 SG_ UI_perpendicularAutoparkEnabled : 31|1@1+ (1,0) [0|1] "" Vector__XXX
 SG_ UI_nextBranchDist : 32|5@1+ (10,0) [0|300] "m" Vector__XXX
 SG_ UI_controlledAccess : 37|1@1+ (1,0) [0|1] "" Vector__XXX
 SG_ UI_nextBranchLeftOffRamp : 38|1@1+ (1,0) [0|1] "" Vector__XXX
 SG_ UI_nextBranchRightOffRamp : 39|1@1+ (1,0) [0|1] "" Vector__XXX
 SG_ UI_rejectLeftLane : 40|1@1+ (1,0) [0|1] "" Vector__XXX
 SG_ UI_rejectRightLane : 41|1@1+ (1,0) [0|1] "" Vector__XXX
 SG_ UI_rejectHPP : 42|1@1+ (1,0) [0|1] "" Vector__XXX
 SG_ UI_rejectNav : 43|1@1+ (1,0) [0|1] "" Vector__XXX
 SG_ UI_rejectLeftFreeSpace : 44|1@1+ (1,0) [0|1] "" Vector__XXX
 SG_ UI_rejectRightFreeSpace : 45|1@1+ (1,0) [0|1] "" Vector__XXX
 SG_ UI_rejectAutosteer : 46|1@1+ (1,0) [0|1] "" Vector__XXX
 SG_ UI_rejectHandsOn : 47|1@1+ (1,0) [0|1] "" Vector__XXX
 SG_ UI_acceptBottsDots : 48|1@1+ (1,0) [0|1] "" Vector__XXX
 SG_ UI_autosteerRestricted : 49|1@1+ (1,0) [0|1] "" Vector__XXX
 SG_ UI_pmmEnabled : 50|1@1+ (1,0) [0|1] "" Vector__XXX
 SG_ UI_scaEnabled : 51|1@1+ (1,0) [0|1] "" Vector__XXX
 SG_ UI_mapDataCounter : 52|4@1+ (1,0) [0|15] "" Vector__XXX
 SG_ UI_mapDataChecksum : 56|8@1+ (1,0) [0|255] "" Vector__XXX

BO_ 536 UI_driverAssistRoadSign: 8 GTW
 SG_ UI_roadSign M : 0|8@1+ (1,0) [0|254] "" Vector__XXX
 SG_ UI_splineLocConfidence : 40|7@1+ (1,0) [1|127] "1" Vector__XXX
 SG_ UI_splineID : 48|4@1+ (1,0) [0|15] "" Vector__XXX
 SG_ UI_roadSignCounter : 52|4@1+ (1,0) [0|15] "" Vector__XXX
 SG_ UI_roadSignChecksum : 56|8@1+ (1,0) [0|255] "" Vector__XXX
 SG_ UI_dummyData m0 : 8|1@1+ (1,0) [0|1] "" Vector__XXX
 SG_ UI_stopSignStopLineDist m1 : 8|10@1+ (0.25,-8) [-8|247.5] "m" Vector__XXX
 SG_ UI_stopSignStopLineConf m1 : 18|7@1+ (1,0) [1|127] "1" Vector__XXX
 SG_ UI_trafficLightStopLineDist m2 : 8|10@1+ (0.25,-8) [-8|247.5] "m" Vector__XXX
 SG_ UI_trafficLightStopLineConf m2 : 18|7@1+ (1,0) [1|127] "1" Vector__XXX
 SG_ UI_baseMapSpeedLimitMPS m3 : 8|8@1+ (0.25,0) [0|63.5] "m/s" Vector__XXX
 SG_ UI_bottomQrtlFleetSpeedMPS m3 : 16|8@1+ (0.25,0) [0|63.5] "m/s" Vector__XXX
 SG_ UI_topQrtlFleetSpeedMPS m3 : 24|8@1+ (0.25,0) [0|63.5] "m/s" Vector__XXX
 SG_ UI_meanFleetSplineSpeedMPS m4 : 8|8@1+ (0.25,0) [0|63.5] "m/s" Vector__XXX
 SG_ UI_medianFleetSpeedMPS m4 : 16|8@1+ (0.25,0) [0|63.5] "m/s" Vector__XXX
 SG_ UI_meanFleetSplineAccelMPS2 m4 : 24|8@1+ (0.05,-6.35) [-6.35|6.35] "m/s^2" Vector__XXX
 SG_ UI_rampType m4 : 32|3@1+ (1,0) [1|7] "" Vector__XXX
 SG_ UI_valhallaRamp m4 : 35|2@1+ (1,0) [1|3] "" Vector__XXX
 SG_ UI_overrideACMFleetSpeed m4 : 38|1@1+ (1,0) [0|1] "" Vector__XXX
 SG_ UI_currSplineIdFull m5 : 8|32@1+ (1,0) [1|4294967295] "1" Vector__XXX

BO_ 1971 UI_dynamicTriggersCampaignFired: 8 GTW
 SG_ UI_campaignFired : 0|64@1+ (1,0) [0|1.84467440737e+19] "" Vector__XXX

BO_ 760 UI_gpsVehicleSpeed: 8 GTW
 SG_ UI_gpsHDOP : 0|8@1+ (0.1,0) [0|25.5] "1" Vector__XXX
 SG_ UI_gpsVehicleHeading : 8|16@1+ (0.0078125,0) [0|511.9921875] "deg" Vector__XXX
 SG_ UI_gpsVehicleSpeed : 24|16@1+ (0.00390625,0) [0|255.99609375] "km/hr" Vector__XXX
 SG_ UI_userSpeedOffset : 40|6@1+ (1,-30) [-30|33] "kph/mph" Vector__XXX
 SG_ UI_mapSpeedLimitUnits : 46|1@1+ (1,0) [0|1] "" Vector__XXX
 SG_ UI_userSpeedOffsetUnits : 47|1@1+ (1,0) [0|1] "" Vector__XXX
 SG_ UI_mppSpeedLimit : 48|5@1+ (5,0) [0|155] "kph/mph" Vector__XXX
 SG_ UI_gpsNmeaMIA : 53|1@1+ (1,0) [0|1] "" Vector__XXX
 SG_ UI_gpsAntennaDisconnected : 54|1@1+ (1,0) [0|1] "" Vector__XXX
 SG_ UI_conditionalLimitActive : 55|1@1+ (1,0) [0|1] "" Vector__XXX
 SG_ UI_conditionalSpeedLimit : 56|5@1+ (5,0) [0|150] "kph/mph" Vector__XXX

BO_ 985 UI_locationOffset: 8 GTW
 SG_ UI_latitudeOffset : 0|28@1- (1.0e-06,0) [-134.217728|134.217727] "deg" Vector__XXX
 SG_ UI_longitudeOffset : 28|29@1- (1.0e-06,0) [-268.435456|268.435455] "deg" Vector__XXX

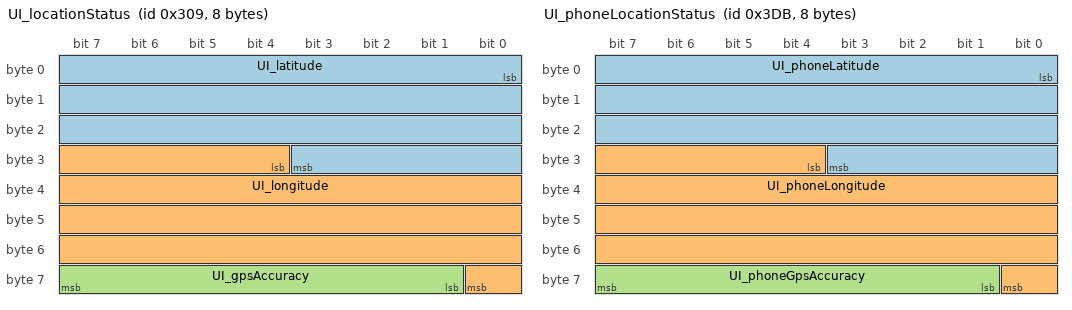
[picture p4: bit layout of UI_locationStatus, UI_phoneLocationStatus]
BO_ 777 UI_locationStatus: 8 GTW
 SG_ UI_latitude : 0|28@1- (1.0e-06,0) [-134.217728|134.217727] "deg" Vector__XXX
 SG_ UI_longitude : 28|29@1- (1.0e-06,0) [-268.435456|268.435455] "deg" Vector__XXX
 SG_ UI_gpsAccuracy : 57|7@1+ (0.2,0) [0|25.2] "m" Vector__XXX

BO_ 1011 UI_odo: 3 GTW
 SG_ UI_odometer : 0|24@1+ (0.1,0) [0|1677721.4] "km" Vector__XXX

BO_ 987 UI_phoneLocationStatus: 8 GTW
 SG_ UI_phoneLatitude : 0|28@1- (1.0e-06,0) [-134.217728|134.217727] "deg" Vector__XXX
 SG_ UI_phoneLongitude : 28|29@1- (1.0e-06,0) [-268.435456|268.435455] "deg" Vector__XXX
 SG_ UI_phoneGpsAccuracy : 57|7@1+ (0.5,0) [0|63] "m" Vector__XXX

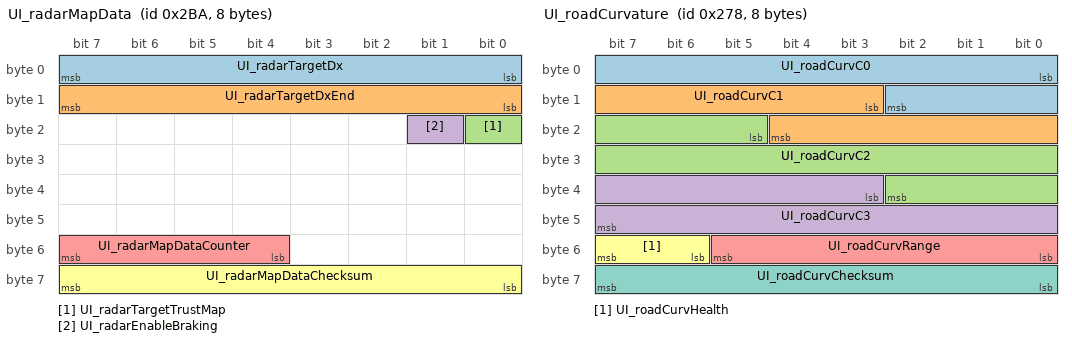
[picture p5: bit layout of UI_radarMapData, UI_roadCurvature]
BO_ 698 UI_radarMapData: 8 GTW
 SG_ UI_radarTargetDx : 0|8@1+ (1,-95) [-95|160] "m" Vector__XXX
 SG_ UI_radarTargetDxEnd : 8|8@1+ (1,0) [0|255] "m" Vector__XXX
 SG_ UI_radarTargetTrustMap : 16|1@1+ (1,0) [0|1] "" Vector__XXX
 SG_ UI_radarEnableBraking : 17|1@1+ (1,0) [0|1] "" Vector__XXX
 SG_ UI_radarMapDataCounter : 52|4@1+ (1,0) [0|15] "" Vector__XXX
 SG_ UI_radarMapDataChecksum : 56|8@1+ (1,0) [0|255] "" Vector__XXX

BO_ 632 UI_roadCurvature: 8 GTW
 SG_ UI_roadCurvC0 : 0|11@1- (0.02,0) [-20.48|20.46] "m" Vector__XXX
 SG_ UI_roadCurvC1 : 11|10@1- (0.00075,0) [-0.384|0.38325] "1" Vector__XXX
 SG_ UI_roadCurvC2 : 21|14@1- (7.5e-06,0) [-0.06144|0.0614325] "1/m" Vector__XXX
 SG_ UI_roadCurvC3 : 35|13@1- (3.0e-08,0) [-0.00012288|0.00012285] "1/m2" Vector__XXX
 SG_ UI_roadCurvRange : 48|6@1+ (4,0) [0|252] "m" Vector__XXX
 SG_ UI_roadCurvHealth : 54|2@1+ (1,0) [0|3] "" Vector__XXX
 SG_ UI_roadCurvChecksum : 56|8@1+ (1,0) [0|255] "" Vector__XXX

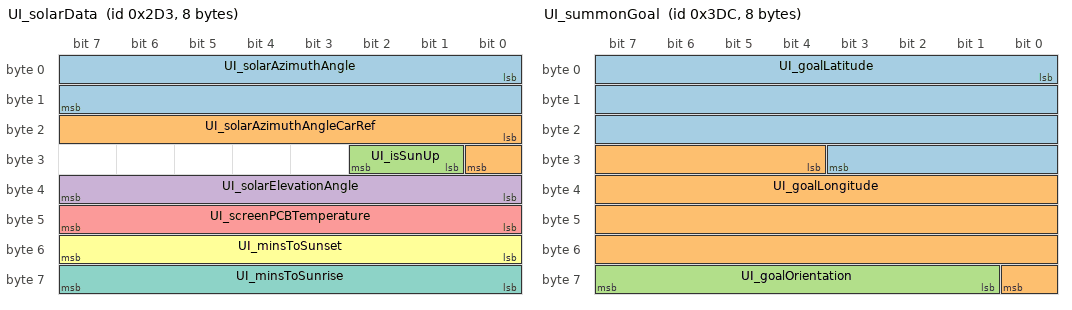
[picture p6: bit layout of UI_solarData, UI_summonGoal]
BO_ 723 UI_solarData: 8 GTW
 SG_ UI_solarAzimuthAngle : 0|16@1- (1,0) [-32768|32767] "degrees" Vector__XXX
 SG_ UI_solarAzimuthAngleCarRef : 16|9@1- (1,0) [-256|254] "degrees" Vector__XXX
 SG_ UI_isSunUp : 25|2@1+ (1,0) [0|2] "" Vector__XXX
 SG_ UI_solarElevationAngle : 32|8@1- (1,0) [-128|126] "degrees" Vector__XXX
 SG_ UI_screenPCBTemperature : 40|8@1- (0.5,40) [-20|100] "degC" Vector__XXX
 SG_ UI_minsToSunset : 48|8@1+ (10,0) [0|2550] "min" Vector__XXX
 SG_ UI_minsToSunrise : 56|8@1+ (10,0) [0|2550] "min" Vector__XXX

BO_ 851 UI_status: 8 GTW
 SG_ UI_touchActive : 0|1@1+ (1,0) [0|1] "" Vector__XXX
 SG_ UI_audioActive : 1|1@1+ (1,0) [0|1] "" Vector__XXX
 SG_ UI_bluetoothActive : 2|1@1+ (1,0) [0|1] "" Vector__XXX
 SG_ UI_cellActive : 3|1@1+ (1,0) [0|1] "" Vector__XXX
 SG_ UI_displayReady : 4|1@1+ (1,0) [0|1] "" Vector__XXX
 SG_ UI_displayOn : 5|1@1+ (1,0) [0|1] "" Vector__XXX
 SG_ UI_wifiActive : 6|1@1+ (1,0) [0|1] "" Vector__XXX
 SG_ UI_wifiConnected : 7|1@1+ (1,0) [0|1] "" Vector__XXX
 SG_ UI_systemActive : 8|1@1+ (1,0) [0|1] "" Vector__XXX
 SG_ UI_readyForDrive : 9|1@1+ (1,0) [0|1] "" Vector__XXX
 SG_ UI_cellConnected : 10|1@1+ (1,0) [0|1] "" Vector__XXX
 SG_ UI_vpnActive : 11|1@1+ (1,0) [0|1] "" Vector__XXX
 SG_ UI_autopilotTrial : 12|2@1+ (1,0) [0|3] "" Vector__XXX
 SG_ UI_factoryReset : 14|2@1+ (1,0) [1|3] "" Vector__XXX
 SG_ UI_gpsActive : 16|1@1+ (1,0) [0|1] "" Vector__XXX
 SG_ UI_screenshotActive : 17|1@1+ (1,0) [0|1] "" Vector__XXX
 SG_ UI_radioActive : 18|1@1+ (1,0) [0|1] "" Vector__XXX
 SG_ UI_cellNetworkTechnology : 19|4@1+ (1,0) [0|14] "" Vector__XXX
 SG_ UI_cellReceiverPower : 24|8@1+ (1,-128) [-128|127] "dB" Vector__XXX
 SG_ UI_falseTouchCounter : 32|8@1+ (1,0) [0|255] "1" Vector__XXX
 SG_ UI_developmentCar : 40|1@1+ (1,0) [0|1] "" Vector__XXX
 SG_ UI_cameraActive : 41|1@1+ (1,0) [0|1] "" Vector__XXX
 SG_ UI_cellSignalBars : 42|3@1+ (1,0) [0|6] "" Vector__XXX
 SG_ UI_trailerModeTelltale : 45|2@1+ (1,0) [0|3] "" Vector__XXX
 SG_ UI_pcbTemperature : 48|8@1- (1,40) [-20|100] "degC" Vector__XXX
 SG_ UI_cpuTemperature : 56|8@1- (1,40) [-20|100] "degC" Vector__XXX

BO_ 988 UI_summonGoal: 8 GTW
 SG_ UI_goalLatitude : 0|28@1- (1.0e-06,0) [-134.217728|134.217727] "deg" Vector__XXX
 SG_ UI_goalLongitude : 28|29@1- (1.0e-06,0) [-268.435456|268.435455] "deg" Vector__XXX
 SG_ UI_goalOrientation : 57|7@1+ (2.8125,0) [0|357.1875] "deg" Vector__XXX

BO_ 1064 UI_telemetryControl: 8 GTW
 SG_ UI_TCR_enable : 0|1@1+ (1,0) [0|1] "" Vector__XXX
 SG_ UI_TCR_moveStateStanding : 1|1@1+ (1,0) [0|1] "" Vector__XXX
 SG_ UI_TCR_moveStateStopped : 2|1@1+ (1,0) [0|1] "" Vector__XXX
 SG_ UI_TCR_moveStateMoving : 3|1@1+ (1,0) [0|1] "" Vector__XXX
 SG_ UI_TCR_moveStateIndeterm : 4|1@1+ (1,0) [0|1] "" Vector__XXX
 SG_ UI_TCR_classConstElem : 5|1@1+ (1,0) [0|1] "" Vector__XXX
 SG_ UI_TCR_classMovingPed : 6|1@1+ (1,0) [0|1] "" Vector__XXX
 SG_ UI_TCR_classMovingTwoWheel : 7|1@1+ (1,0) [0|1] "" Vector__XXX
 SG_ UI_TCR_classMovingFourWheel : 8|1@1+ (1,0) [0|1] "" Vector__XXX
 SG_ UI_TCR_classUnknown : 9|1@1+ (1,0) [0|1] "" Vector__XXX
 SG_ UI_TCR_downSampleFactor : 10|4@1+ (1,0) [0|15] "" Vector__XXX
 SG_ UI_TCR_wExist : 24|5@1+ (1,0) [0|31] "" Vector__XXX
 SG_ UI_TCR_vehSpeed : 32|8@1+ (1,0) [0|255] "" Vector__XXX
 SG_ UI_TCR_minRCS : 40|8@1+ (0.25,-14) [-14|49.75] "dB" Vector__XXX
 SG_ UI_TCR_maxDy : 48|5@1+ (0.5,0) [0|15.5] "m" Vector__XXX
 SG_ UI_TCR_maxObjects : 56|5@1+ (1,0) [0|31] "" Vector__XXX
 SG_ UI_TCR_maxRoadClass : 61|3@1+ (1,0) [0|7] "" Vector__XXX

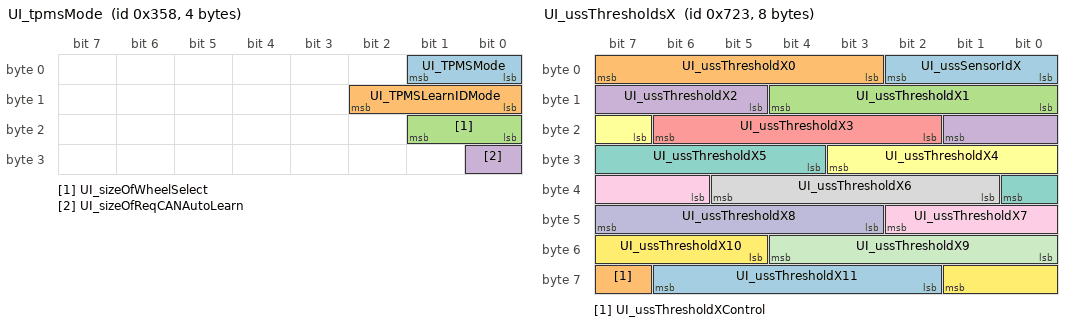
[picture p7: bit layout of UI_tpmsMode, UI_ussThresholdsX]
BO_ 856 UI_tpmsMode: 4 GTW
 SG_ UI_TPMSMode : 0|2@1+ (1,0) [0|3] "" Vector__XXX
 SG_ UI_TPMSLearnIDMode : 8|3@1+ (1,0) [0|7] "" Vector__XXX
 SG_ UI_sizeOfWheelSelect : 16|2@1+ (1,0) [0|3] "" Vector__XXX
 SG_ UI_sizeOfReqCANAutoLearn : 24|1@1+ (1,0) [0|1] "" Vector__XXX

BO_ 1827 UI_ussThresholdsX: 8 GTW
 SG_ UI_ussSensorIdX : 0|3@1+ (1,0) [0|7] "" Vector__XXX
 SG_ UI_ussThresholdX0 : 3|5@1+ (1,0) [0|31] "" Vector__XXX
 SG_ UI_ussThresholdX1 : 8|5@1+ (1,0) [0|31] "" Vector__XXX
 SG_ UI_ussThresholdX2 : 13|5@1+ (1,0) [0|31] "" Vector__XXX
 SG_ UI_ussThresholdX3 : 18|5@1+ (1,0) [0|31] "" Vector__XXX
 SG_ UI_ussThresholdX4 : 23|5@1+ (1,0) [0|31] "" Vector__XXX
 SG_ UI_ussThresholdX5 : 28|5@1+ (1,0) [0|31] "" Vector__XXX
 SG_ UI_ussThresholdX6 : 33|5@1+ (1,0) [0|31] "" Vector__XXX
 SG_ UI_ussThresholdX7 : 38|5@1+ (1,0) [0|31] "" Vector__XXX
 SG_ UI_ussThresholdX8 : 43|5@1+ (1,0) [0|31] "" Vector__XXX
 SG_ UI_ussThresholdX9 : 48|5@1+ (1,0) [0|31] "" Vector__XXX
 SG_ UI_ussThresholdX10 : 53|5@1+ (1,0) [0|31] "" Vector__XXX
 SG_ UI_ussThresholdX11 : 58|5@1+ (1,0) [0|31] "" Vector__XXX
 SG_ UI_ussThresholdXControl : 63|1@1+ (1,0) [0|1] "" Vector__XXX

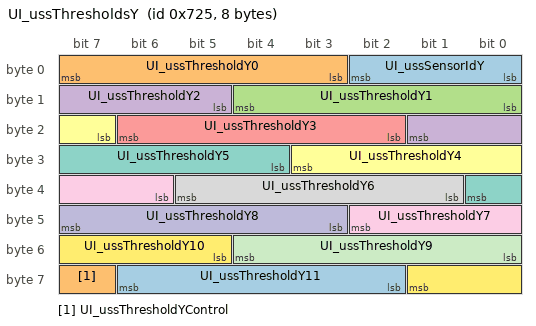
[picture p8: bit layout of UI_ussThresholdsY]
BO_ 1829 UI_ussThresholdsY: 8 GTW
 SG_ UI_ussSensorIdY : 0|3@1+ (1,0) [0|7] "" Vector__XXX
 SG_ UI_ussThresholdY0 : 3|5@1+ (1,0) [0|31] "" Vector__XXX
 SG_ UI_ussThresholdY1 : 8|5@1+ (1,0) [0|31] "" Vector__XXX
 SG_ UI_ussThresholdY2 : 13|5@1+ (1,0) [0|31] "" Vector__XXX
 SG_ UI_ussThresholdY3 : 18|5@1+ (1,0) [0|31] "" Vector__XXX
 SG_ UI_ussThresholdY4 : 23|5@1+ (1,0) [0|31] "" Vector__XXX
 SG_ UI_ussThresholdY5 : 28|5@1+ (1,0) [0|31] "" Vector__XXX
 SG_ UI_ussThresholdY6 : 33|5@1+ (1,0) [0|31] "" Vector__XXX
 SG_ UI_ussThresholdY7 : 38|5@1+ (1,0) [0|31] "" Vector__XXX
 SG_ UI_ussThresholdY8 : 43|5@1+ (1,0) [0|31] "" Vector__XXX
 SG_ UI_ussThresholdY9 : 48|5@1+ (1,0) [0|31] "" Vector__XXX
 SG_ UI_ussThresholdY10 : 53|5@1+ (1,0) [0|31] "" Vector__XXX
 SG_ UI_ussThresholdY11 : 58|5@1+ (1,0) [0|31] "" Vector__XXX
 SG_ UI_ussThresholdYControl : 63|1@1+ (1,0) [0|1] "" Vector__XXX

BO_ 954 USM_alertMatrix: 8 USM
 SG_ USM_matrixIndex M : 0|4@1+ (1,0) [0|15] "" Vector__XXX
 SG_ USM_a001_WatchdogReset m0 : 4|1@1+ (1,0) [0|1] "" Vector__XXX
 SG_ USM_a002_PowerLossReset m0 : 5|1@1+ (1,0) [0|1] "" Vector__XXX
 SG_ USM_a003_SWAssertion m0 : 6|1@1+ (1,0) [0|1] "" Vector__XXX
 SG_ USM_a005_CANTXError m0 : 8|1@1+ (1,0) [0|1] "" Vector__XXX
 SG_ USM_a006_CANTX_cyclicError m0 : 9|1@1+ (1,0) [0|1] "" Vector__XXX
 SG_ USM_a012_CPUReset m0 : 15|1@1+ (1,0) [0|1] "" Vector__XXX
 SG_ USM_a013_AlertManagerFault m0 : 16|1@1+ (1,0) [0|1] "" Vector__XXX
 SG_ USM_a015_NVMMError m0 : 18|1@1+ (1,0) [0|1] "" Vector__XXX
 SG_ USM_a016_NVMMRecordError m0 : 19|1@1+ (1,0) [0|1] "" Vector__XXX
 SG_ USM_a021_TaskSchedulerError m0 : 24|1@1+ (1,0) [0|1] "" Vector__XXX
 SG_ USM_a022_TaskInitError m0 : 25|1@1+ (1,0) [0|1] "" Vector__XXX
 SG_ USM_a029_CoreDump m0 : 32|1@1+ (1,0) [0|1] "" Vector__XXX
 SG_ USM_a030_ECULogUploadRequest m0 : 33|1@1+ (1,0) [0|1] "" Vector__XXX
 SG_ USM_a031_UDSActive m0 : 34|1@1+ (1,0) [0|1] "" Vector__XXX
 SG_ USM_a041_HighCPULoad m0 : 44|1@1+ (1,0) [0|1] "" Vector__XXX
 SG_ USM_a042_HighStackUsage m0 : 45|1@1+ (1,0) [0|1] "" Vector__XXX
 SG_ USM_a043_Task1msError m0 : 46|1@1+ (1,0) [0|1] "" Vector__XXX
 SG_ USM_a044_Task10msError m0 : 47|1@1+ (1,0) [0|1] "" Vector__XXX
 SG_ USM_a045_Task100msError m0 : 48|1@1+ (1,0) [0|1] "" Vector__XXX
 SG_ USM_a046_Task1000msError m0 : 49|1@1+ (1,0) [0|1] "" Vector__XXX
 SG_ USM_a057_HVP_MIA m0 : 60|1@1+ (1,0) [0|1] "" Vector__XXX
 SG_ USM_a058_inputRHighSyncDebug m0 : 61|1@1+ (1,0) [0|1] "" Vector__XXX
 SG_ USM_a059_inputResistanceHigh m0 : 62|1@1+ (1,0) [0|1] "" Vector__XXX
 SG_ USM_a060_engineeringBuild m0 : 63|1@1+ (1,0) [0|1] "" Vector__XXX
 SG_ USM_a061_XCPConnected m1 : 4|1@1+ (1,0) [0|1] "" Vector__XXX
 SG_ USM_a062_XCPWasConnected m1 : 5|1@1+ (1,0) [0|1] "" Vector__XXX
 SG_ USM_a063_SwitchFault m1 : 6|1@1+ (1,0) [0|1] "" Vector__XXX
 SG_ USM_a064_busSleepReqTimeout m1 : 7|1@1+ (1,0) [0|1] "" Vector__XXX
 SG_ USM_a082_VCRIGHT_IPC_MIA m1 : 25|1@1+ (1,0) [0|1] "" Vector__XXX
 SG_ USM_a083_VCLEFT_IPC_MIA m1 : 26|1@1+ (1,0) [0|1] "" Vector__XXX
 SG_ USM_a084_TPMS_MIA m1 : 27|1@1+ (1,0) [0|1] "" Vector__XXX
 SG_ USM_a085_CCCM_MIA m1 : 28|1@1+ (1,0) [0|1] "" Vector__XXX
 SG_ USM_a086_VCBATT_MIA m1 : 29|1@1+ (1,0) [0|1] "" Vector__XXX
 SG_ USM_a087_DIREL_MIA m1 : 30|1@1+ (1,0) [0|1] "" Vector__XXX
 SG_ USM_a088_DIRER_MIA m1 : 31|1@1+ (1,0) [0|1] "" Vector__XXX
 SG_ USM_a089_IBST_MIA m1 : 32|1@1+ (1,0) [0|1] "" Vector__XXX
 SG_ USM_a090_APS_MIA m1 : 33|1@1+ (1,0) [0|1] "" Vector__XXX
 SG_ USM_a091_CMPD_MIA m1 : 34|1@1+ (1,0) [0|1] "" Vector__XXX
 SG_ USM_a092_VCSEATD_MIA m1 : 35|1@1+ (1,0) [0|1] "" Vector__XXX
 SG_ USM_a093_VCSEATP_MIA m1 : 36|1@1+ (1,0) [0|1] "" Vector__XXX
 SG_ USM_a094_EPAS3P_MIA m1 : 37|1@1+ (1,0) [0|1] "" Vector__XXX
 SG_ USM_a095_CHG_MIA m1 : 38|1@1+ (1,0) [0|1] "" Vector__XXX
 SG_ USM_a096_OCS1P_MIA m1 : 39|1@1+ (1,0) [0|1] "" Vector__XXX
 SG_ USM_a097_CMP_MIA m1 : 40|1@1+ (1,0) [0|1] "" Vector__XXX
 SG_ USM_a098_DIR_MIA m1 : 41|1@1+ (1,0) [0|1] "" Vector__XXX
 SG_ USM_a099_PARK_MIA m1 : 42|1@1+ (1,0) [0|1] "" Vector__XXX
 SG_ USM_a100_CANbus_MIA m1 : 43|1@1+ (1,0) [0|1] "" Vector__XXX
 SG_ USM_a101_PM_MIA m1 : 44|1@1+ (1,0) [0|1] "" Vector__XXX
 SG_ USM_a102_PTC_MIA m1 : 45|1@1+ (1,0) [0|1] "" Vector__XXX
 SG_ USM_a103_CP_MIA m1 : 46|1@1+ (1,0) [0|1] "" Vector__XXX
 SG_ USM_a104_DAS_MIA m1 : 47|1@1+ (1,0) [0|1] "" Vector__XXX
 SG_ USM_a105_TAS_MIA m1 : 48|1@1+ (1,0) [0|1] "" Vector__XXX
 SG_ USM_a106_PCS_MIA m1 : 49|1@1+ (1,0) [0|1] "" Vector__XXX
 SG_ USM_a107_BMS_MIA m1 : 50|1@1+ (1,0) [0|1] "" Vector__XXX
 SG_ USM_a108_DIF_MIA m1 : 51|1@1+ (1,0) [0|1] "" Vector__XXX
 SG_ USM_a109_RCM_MIA m1 : 52|1@1+ (1,0) [0|1] "" Vector__XXX
 SG_ USM_a110_GTW_MIA m1 : 53|1@1+ (1,0) [0|1] "" Vector__XXX
 SG_ USM_a111_EPBR_MIA m1 : 54|1@1+ (1,0) [0|1] "" Vector__XXX
 SG_ USM_a112_EPBL_MIA m1 : 55|1@1+ (1,0) [0|1] "" Vector__XXX
 SG_ USM_a113_UI_MIA m1 : 56|1@1+ (1,0) [0|1] "" Vector__XXX
 SG_ USM_a114_ESP_MIA m1 : 57|1@1+ (1,0) [0|1] "" Vector__XXX
 SG_ USM_a115_VCSEC_MIA m1 : 58|1@1+ (1,0) [0|1] "" Vector__XXX
 SG_ USM_a116_VCRIGHT_MIA m1 : 59|1@1+ (1,0) [0|1] "" Vector__XXX
 SG_ USM_a117_VCLEFT_MIA m1 : 60|1@1+ (1,0) [0|1] "" Vector__XXX
 SG_ USM_a118_VCFRONT_MIA m1 : 61|1@1+ (1,0) [0|1] "" Vector__XXX
 SG_ USM_a119_SCCM_MIA m1 : 62|1@1+ (1,0) [0|1] "" Vector__XXX
 SG_ USM_a120_DI_DRIVE_MIA m1 : 63|1@1+ (1,0) [0|1] "" Vector__XXX
 SG_ USM_a131_s1ComError m2 : 14|1@1+ (1,0) [0|1] "" Vector__XXX
 SG_ USM_a132_s2ComError m2 : 15|1@1+ (1,0) [0|1] "" Vector__XXX
 SG_ USM_a133_s3ComError m2 : 16|1@1+ (1,0) [0|1] "" Vector__XXX
 SG_ USM_a134_s4ComError m2 : 17|1@1+ (1,0) [0|1] "" Vector__XXX
 SG_ USM_a135_s5ComError m2 : 18|1@1+ (1,0) [0|1] "" Vector__XXX
 SG_ USM_a136_s6ComError m2 : 19|1@1+ (1,0) [0|1] "" Vector__XXX
 SG_ USM_a137_s7ComError m2 : 20|1@1+ (1,0) [0|1] "" Vector__XXX
 SG_ USM_a138_s8ComError m2 : 21|1@1+ (1,0) [0|1] "" Vector__XXX
 SG_ USM_a139_s9ComError m2 : 22|1@1+ (1,0) [0|1] "" Vector__XXX
 SG_ USM_a140_s10ComError m2 : 23|1@1+ (1,0) [0|1] "" Vector__XXX
 SG_ USM_a141_s11ComError m2 : 24|1@1+ (1,0) [0|1] "" Vector__XXX
 SG_ USM_a142_s12ComError m2 : 25|1@1+ (1,0) [0|1] "" Vector__XXX
 SG_ USM_a143_s1HwError m2 : 26|1@1+ (1,0) [0|1] "" Vector__XXX
 SG_ USM_a144_s2HwError m2 : 27|1@1+ (1,0) [0|1] "" Vector__XXX
 SG_ USM_a145_s3HwError m2 : 28|1@1+ (1,0) [0|1] "" Vector__XXX
 SG_ USM_a146_s4HwError m2 : 29|1@1+ (1,0) [0|1] "" Vector__XXX
 SG_ USM_a147_s5HwError m2 : 30|1@1+ (1,0) [0|1] "" Vector__XXX
 SG_ USM_a148_s6HwError m2 : 31|1@1+ (1,0) [0|1] "" Vector__XXX
 SG_ USM_a149_s7HwError m2 : 32|1@1+ (1,0) [0|1] "" Vector__XXX
 SG_ USM_a150_s8HwError m2 : 33|1@1+ (1,0) [0|1] "" Vector__XXX
 SG_ USM_a151_s9HwError m2 : 34|1@1+ (1,0) [0|1] "" Vector__XXX
 SG_ USM_a152_s10HwError m2 : 35|1@1+ (1,0) [0|1] "" Vector__XXX
 SG_ USM_a153_s11HwError m2 : 36|1@1+ (1,0) [0|1] "" Vector__XXX
 SG_ USM_a154_s12HwError m2 : 37|1@1+ (1,0) [0|1] "" Vector__XXX
 SG_ USM_a155_s1OverTemp m2 : 38|1@1+ (1,0) [0|1] "" Vector__XXX
 SG_ USM_a156_s2OverTemp m2 : 39|1@1+ (1,0) [0|1] "" Vector__XXX
 SG_ USM_a157_s3OverTemp m2 : 40|1@1+ (1,0) [0|1] "" Vector__XXX
 SG_ USM_a158_s4OverTemp m2 : 41|1@1+ (1,0) [0|1] "" Vector__XXX
 SG_ USM_a159_s5OverTemp m2 : 42|1@1+ (1,0) [0|1] "" Vector__XXX
 SG_ USM_a160_s6OverTemp m2 : 43|1@1+ (1,0) [0|1] "" Vector__XXX
 SG_ USM_a161_s7OverTemp m2 : 44|1@1+ (1,0) [0|1] "" Vector__XXX
 SG_ USM_a162_s8OverTemp m2 : 45|1@1+ (1,0) [0|1] "" Vector__XXX
 SG_ USM_a163_s9OverTemp m2 : 46|1@1+ (1,0) [0|1] "" Vector__XXX
 SG_ USM_a164_s10OverTemp m2 : 47|1@1+ (1,0) [0|1] "" Vector__XXX
 SG_ USM_a165_s11OverTemp m2 : 48|1@1+ (1,0) [0|1] "" Vector__XXX
 SG_ USM_a166_s12OverTemp m2 : 49|1@1+ (1,0) [0|1] "" Vector__XXX
 SG_ USM_a177_s1Blocked m2 : 60|1@1+ (1,0) [0|1] "" Vector__XXX
 SG_ USM_a178_s2Blocked m2 : 61|1@1+ (1,0) [0|1] "" Vector__XXX
 SG_ USM_a179_s3Blocked m2 : 62|1@1+ (1,0) [0|1] "" Vector__XXX
 SG_ USM_a180_s4Blocked m2 : 63|1@1+ (1,0) [0|1] "" Vector__XXX
 SG_ USM_a181_s5Blocked m3 : 4|1@1+ (1,0) [0|1] "" Vector__XXX
 SG_ USM_a182_s6Blocked m3 : 5|1@1+ (1,0) [0|1] "" Vector__XXX
 SG_ USM_a183_s7Blocked m3 : 6|1@1+ (1,0) [0|1] "" Vector__XXX
 SG_ USM_a184_s8Blocked m3 : 7|1@1+ (1,0) [0|1] "" Vector__XXX
 SG_ USM_a185_s9Blocked m3 : 8|1@1+ (1,0) [0|1] "" Vector__XXX
 SG_ USM_a186_s10Blocked m3 : 9|1@1+ (1,0) [0|1] "" Vector__XXX
 SG_ USM_a187_s11Blocked m3 : 10|1@1+ (1,0) [0|1] "" Vector__XXX
 SG_ USM_a188_s12Blocked m3 : 11|1@1+ (1,0) [0|1] "" Vector__XXX
 SG_ USM_a189_s1Disconnected m3 : 12|1@1+ (1,0) [0|1] "" Vector__XXX
 SG_ USM_a190_s2Disconnected m3 : 13|1@1+ (1,0) [0|1] "" Vector__XXX
 SG_ USM_a191_s3Disconnected m3 : 14|1@1+ (1,0) [0|1] "" Vector__XXX
 SG_ USM_a192_s4Disconnected m3 : 15|1@1+ (1,0) [0|1] "" Vector__XXX
 SG_ USM_a193_s5Disconnected m3 : 16|1@1+ (1,0) [0|1] "" Vector__XXX
 SG_ USM_a194_s6Disconnected m3 : 17|1@1+ (1,0) [0|1] "" Vector__XXX
 SG_ USM_a195_s7Disconnected m3 : 18|1@1+ (1,0) [0|1] "" Vector__XXX
 SG_ USM_a196_s8Disconnected m3 : 19|1@1+ (1,0) [0|1] "" Vector__XXX
 SG_ USM_a197_s9Disconnected m3 : 20|1@1+ (1,0) [0|1] "" Vector__XXX
 SG_ USM_a198_s10Disconnected m3 : 21|1@1+ (1,0) [0|1] "" Vector__XXX
 SG_ USM_a199_s11Disconnected m3 : 22|1@1+ (1,0) [0|1] "" Vector__XXX
 SG_ USM_a200_s12Disconnected m3 : 23|1@1+ (1,0) [0|1] "" Vector__XXX
 SG_ USM_a201_e52142Fault m3 : 24|1@1+ (1,0) [0|1] "" Vector__XXX
 SG_ USM_a202_e52417Fault m3 : 25|1@1+ (1,0) [0|1] "" Vector__XXX
 SG_ USM_a203_s1NearFieldDetected m3 : 26|1@1+ (1,0) [0|1] "" Vector__XXX
 SG_ USM_a204_s2NearFieldDetected m3 : 27|1@1+ (1,0) [0|1] "" Vector__XXX
 SG_ USM_a205_s3NearFieldDetected m3 : 28|1@1+ (1,0) [0|1] "" Vector__XXX
 SG_ USM_a206_s4NearFieldDetected m3 : 29|1@1+ (1,0) [0|1] "" Vector__XXX
 SG_ USM_a207_s5NearFieldDetected m3 : 30|1@1+ (1,0) [0|1] "" Vector__XXX
 SG_ USM_a208_s6NearFieldDetected m3 : 31|1@1+ (1,0) [0|1] "" Vector__XXX
 SG_ USM_a209_s7NearFieldDetected m3 : 32|1@1+ (1,0) [0|1] "" Vector__XXX
 SG_ USM_a210_s8NearFieldDetected m3 : 33|1@1+ (1,0) [0|1] "" Vector__XXX
 SG_ USM_a211_s9NearFieldDetected m3 : 34|1@1+ (1,0) [0|1] "" Vector__XXX
 SG_ USM_a212_s10NearFieldDetected m3 : 35|1@1+ (1,0) [0|1] "" Vector__XXX
 SG_ USM_a213_s11NearFieldDetected m3 : 36|1@1+ (1,0) [0|1] "" Vector__XXX
 SG_ USM_a214_s12NearFieldDetected m3 : 37|1@1+ (1,0) [0|1] "" Vector__XXX
 SG_ USM_a215_s1DebugEepromInvalid m3 : 38|1@1+ (1,0) [0|1] "" Vector__XXX
 SG_ USM_a216_s2DebugEepromInvalid m3 : 39|1@1+ (1,0) [0|1] "" Vector__XXX
 SG_ USM_a217_s3DebugEepromInvalid m3 : 40|1@1+ (1,0) [0|1] "" Vector__XXX
 SG_ USM_a218_s4DebugEepromInvalid m3 : 41|1@1+ (1,0) [0|1] "" Vector__XXX
 SG_ USM_a219_s5DebugEepromInvalid m3 : 42|1@1+ (1,0) [0|1] "" Vector__XXX
 SG_ USM_a220_s6DebugEepromInvalid m3 : 43|1@1+ (1,0) [0|1] "" Vector__XXX
 SG_ USM_a221_s7DebugEepromInvalid m3 : 44|1@1+ (1,0) [0|1] "" Vector__XXX
 SG_ USM_a222_s8DebugEepromInvalid m3 : 45|1@1+ (1,0) [0|1] "" Vector__XXX
 SG_ USM_a223_s9DebugEepromInvalid m3 : 46|1@1+ (1,0) [0|1] "" Vector__XXX
 SG_ USM_a224_s10DebugEepromInvalid m3 : 47|1@1+ (1,0) [0|1] "" Vector__XXX
 SG_ USM_a225_s11DebugEepromInvalid m3 : 48|1@1+ (1,0) [0|1] "" Vector__XXX
 SG_ USM_a226_s12DebugEepromInvalid m3 : 49|1@1+ (1,0) [0|1] "" Vector__XXX
 SG_ USM_a227_s1InitError m3 : 50|1@1+ (1,0) [0|1] "" Vector__XXX
 SG_ USM_a228_s2InitError m3 : 51|1@1+ (1,0) [0|1] "" Vector__XXX
 SG_ USM_a229_s3InitError m3 : 52|1@1+ (1,0) [0|1] "" Vector__XXX
 SG_ USM_a230_s4InitError m3 : 53|1@1+ (1,0) [0|1] "" Vector__XXX
 SG_ USM_a231_s5InitError m3 : 54|1@1+ (1,0) [0|1] "" Vector__XXX
 SG_ USM_a232_s6InitError m3 : 55|1@1+ (1,0) [0|1] "" Vector__XXX
 SG_ USM_a233_s7InitError m3 : 56|1@1+ (1,0) [0|1] "" Vector__XXX
 SG_ USM_a234_s8InitError m3 : 57|1@1+ (1,0) [0|1] "" Vector__XXX
 SG_ USM_a235_s9InitError m3 : 58|1@1+ (1,0) [0|1] "" Vector__XXX
 SG_ USM_a236_s10InitError m3 : 59|1@1+ (1,0) [0|1] "" Vector__XXX
 SG_ USM_a237_s11InitError m3 : 60|1@1+ (1,0) [0|1] "" Vector__XXX
 SG_ USM_a238_s12InitError m3 : 61|1@1+ (1,0) [0|1] "" Vector__XXX
 SG_ USM_a240_s1HwComErrDiagnostics m3 : 63|1@1+ (1,0) [0|1] "" Vector__XXX
 SG_ USM_a241_s2HwComErrDiagnostics m4 : 4|1@1+ (1,0) [0|1] "" Vector__XXX
 SG_ USM_a242_s3HwComErrDiagnostics m4 : 5|1@1+ (1,0) [0|1] "" Vector__XXX
 SG_ USM_a243_s4HwComErrDiagnostics m4 : 6|1@1+ (1,0) [0|1] "" Vector__XXX
 SG_ USM_a244_s5HwComErrDiagnostics m4 : 7|1@1+ (1,0) [0|1] "" Vector__XXX
 SG_ USM_a245_s6HwComErrDiagnostics m4 : 8|1@1+ (1,0) [0|1] "" Vector__XXX
 SG_ USM_a246_s7HwComErrDiagnostics m4 : 9|1@1+ (1,0) [0|1] "" Vector__XXX
 SG_ USM_a247_s8HwComErrDiagnostics m4 : 10|1@1+ (1,0) [0|1] "" Vector__XXX
 SG_ USM_a248_s9HwComErrDiagnostics m4 : 11|1@1+ (1,0) [0|1] "" Vector__XXX
 SG_ USM_a249_s10HwComErrDiagnostics m4 : 12|1@1+ (1,0) [0|1] "" Vector__XXX
 SG_ USM_a250_s11HwComErrDiagnostics m4 : 13|1@1+ (1,0) [0|1] "" Vector__XXX
 SG_ USM_a251_s12HwComErrDiagnostics m4 : 14|1@1+ (1,0) [0|1] "" Vector__XXX
 SG_ USM_a252_anyComErrorSet m4 : 15|1@1+ (1,0) [0|1] "" Vector__XXX
 SG_ USM_a253_anyHwErrorSet m4 : 16|1@1+ (1,0) [0|1] "" Vector__XXX
 SG_ USM_a254_frontSensorsOvercurrent m4 : 17|1@1+ (1,0) [0|1] "" Vector__XXX
 SG_ USM_a255_rearSensorsOvercurrent m4 : 18|1@1+ (1,0) [0|1] "" Vector__XXX

BO_ 807 USM_info: 8 USM
 SG_ USM_infoIndex M : 0|8@1+ (1,0) [0|255] "" Vector__XXX
 SG_ USM_infoBuildType m10 : 8|3@1+ (1,0) [0|7] "" Vector__XXX
 SG_ USM_infoBuildConfigId m10 : 16|16@1+ (1,0) [0|65535] "" Vector__XXX
 SG_ USM_infoHardwareId m10 : 32|16@1+ (1,0) [0|65535] "" Vector__XXX
 SG_ USM_infoComponentId m10 : 48|16@1+ (1,0) [0|65535] "" Vector__XXX
 SG_ USM_infoPcbaId m11 : 8|8@1+ (1,0) [0|255] "" Vector__XXX
 SG_ USM_infoAssemblyId m11 : 16|8@1+ (1,0) [0|254] "" Vector__XXX
 SG_ USM_infoUsageId m11 : 24|16@1+ (1,0) [0|65535] "" Vector__XXX
 SG_ USM_infoSubUsageId m11 : 40|16@1+ (1,0) [0|65535] "" Vector__XXX
 SG_ USM_infoAppCrc m13 : 8|32@1+ (1,0) [0|4294967295] "" Vector__XXX

BO_TX_BU_ 782 : PARK;
BO_TX_BU_ 894 : PARK;
BO_TX_BU_ 1365 : RADC;
BO_TX_BU_ 1282 : RADC;
BO_TX_BU_ 1329 : RADC;
BO_TX_BU_ 1252 : RCM3;
BO_TX_BU_ 1010 : RCM3;
BO_TX_BU_ 257 : RCM;
BO_TX_BU_ 273 : RCM;
BO_TX_BU_ 849 : RCM;
BO_TX_BU_ 529 : RCM;
BO_TX_BU_ 831 : RCU;
BO_TX_BU_ 879 : TPMS;
BO_TX_BU_ 799 : TPMS;
BO_TX_BU_ 1519 : TPMS;
BO_TX_BU_ 659 : GTW;
BO_TX_BU_ 664 : GTW;
BO_TX_BU_ 679 : GTW;
BO_TX_BU_ 1096 : GTW;
BO_TX_BU_ 1016 : GTW;
BO_TX_BU_ 568 : GTW;
BO_TX_BU_ 536 : GTW;
BO_TX_BU_ 1971 : GTW;
BO_TX_BU_ 760 : GTW;
BO_TX_BU_ 985 : GTW;
BO_TX_BU_ 777 : GTW;
BO_TX_BU_ 1011 : GTW;
BO_TX_BU_ 987 : GTW;
BO_TX_BU_ 698 : GTW;
BO_TX_BU_ 632 : GTW;
BO_TX_BU_ 723 : GTW;
BO_TX_BU_ 851 : GTW;
BO_TX_BU_ 988 : GTW;
BO_TX_BU_ 1064 : GTW;
BO_TX_BU_ 856 : GTW;
BO_TX_BU_ 1827 : GTW;
BO_TX_BU_ 1829 : GTW;
BO_TX_BU_ 954 : USM;
BO_TX_BU_ 807 : USM;
CM_ BO_ 782 "Parking assist sensors message: status2; frame length from the layout, not yet observed on a vehicle bus";
CM_ SG_ 782 PARK_frontSVACharID "Parking assist sensors: front SVA char ID";
CM_ SG_ 782 PARK_pscRightCurbType "The type of curb for the parallel parking slot on the right side.";
CM_ SG_ 782 PARK_rearSVACharID "Parking assist sensors: rear SVA char ID";
CM_ SG_ 782 PARK_pscLeftCurbType "The type of curb identified for a parallel parking space on the left.";
CM_ SG_ 782 PARK_autoCalComplete "Parking assist sensors: auto cal complete";
CM_ SG_ 782 PARK_geometryType "Parking assist sensors: geometry type";
CM_ SG_ 782 PARK_tireFitment "Parking assist sensors: tire fitment; raw 3 = signal not available (SNA)";
CM_ SG_ 782 PARK_rackDetected "Parking assist sensors: rack detected; raw 3 = signal not available (SNA)";
CM_ SG_ 782 PARK_sdiActive "Whether or not the raw sensor measurements from the ultrasonics are present and valid";
CM_ SG_ 782 PARK_sdiNoise "The output of the noise detection algorithm for raw sensor measurements, indicates if the measurements are degraded due to ambient noise; raw 3 = signal not available (SNA)";
CM_ SG_ 782 PARK_sdiBlindSpotRight "The output of the PARK ECU blindspot algorithm on the right side of the car, indicates the presence of a vehicle; raw 3 = signal not available (SNA)";
CM_ SG_ 782 PARK_sdiBlindSpotLeft "The output of the PARK ECU blindspot algorithm on the left side of the car, indicates the presence of a vehicle; raw 3 = signal not available (SNA)";
CM_ SG_ 782 PARK_sensorType "Parking assist sensors: sensor type; raw 3 = signal not available (SNA)";
CM_ SG_ 782 PARK_status2Counter "Parking assist sensors: status2 counter";
CM_ SG_ 782 PARK_status2Checksum "Parking assist sensors: status2 checksum";
CM_ BO_ 894 "Parking assist sensors message: warning matrix; frame length from the layout, not yet observed on a vehicle bus";
CM_ SG_ 894 PARK_matrixIndex "Parking assist sensors: matrix index";
CM_ SG_ 894 PARK_a001_s1_overTemp "Parking assist sensors: a001 s1 over temp";
CM_ SG_ 894 PARK_a002_s1_internalFail "Parking assist sensors: a002 s1 internal fail";
CM_ SG_ 894 PARK_a003_s1_linCommError "Parking assist sensors: a003 s1 lin comm error";
CM_ SG_ 894 PARK_a004_s1_blocked "Parking assist sensors: a004 s1 blocked";
CM_ SG_ 894 PARK_a005_s1_crossTalk "Parking assist sensors: a005 s1 cross talk";
CM_ SG_ 894 PARK_a006_s2_overTemp "Parking assist sensors: a006 s2 over temp";
CM_ SG_ 894 PARK_a007_s2_internalFail "Parking assist sensors: a007 s2 internal fail";
CM_ SG_ 894 PARK_a008_s2_linCommError "Parking assist sensors: a008 s2 lin comm error";
CM_ SG_ 894 PARK_a009_s2_blocked "Parking assist sensors: a009 s2 blocked";
CM_ SG_ 894 PARK_a010_s2_crossTalk "Parking assist sensors: a010 s2 cross talk";
CM_ SG_ 894 PARK_a011_s3_overTemp "Parking assist sensors: a011 s3 over temp";
CM_ SG_ 894 PARK_a012_s3_internalFail "Parking assist sensors: a012 s3 internal fail";
CM_ SG_ 894 PARK_a013_s3_linCommError "Parking assist sensors: a013 s3 lin comm error";
CM_ SG_ 894 PARK_a014_s3_blocked "Parking assist sensors: a014 s3 blocked";
CM_ SG_ 894 PARK_a015_s3_crossTalk "Parking assist sensors: a015 s3 cross talk";
CM_ SG_ 894 PARK_a016_s4_overTemp "Parking assist sensors: a016 s4 over temp";
CM_ SG_ 894 PARK_a017_s4_internalFail "Parking assist sensors: a017 s4 internal fail";
CM_ SG_ 894 PARK_a018_s4_linCommError "Parking assist sensors: a018 s4 lin comm error";
CM_ SG_ 894 PARK_a019_s4_blocked "Parking assist sensors: a019 s4 blocked";
CM_ SG_ 894 PARK_a020_s4_crossTalk "Parking assist sensors: a020 s4 cross talk";
CM_ SG_ 894 PARK_a021_s5_overTemp "Parking assist sensors: a021 s5 over temp";
CM_ SG_ 894 PARK_a022_s5_internalFail "Parking assist sensors: a022 s5 internal fail";
CM_ SG_ 894 PARK_a023_s5_linCommError "Parking assist sensors: a023 s5 lin comm error";
CM_ SG_ 894 PARK_a024_s5_blocked "Parking assist sensors: a024 s5 blocked";
CM_ SG_ 894 PARK_a025_s5_crossTalk "Parking assist sensors: a025 s5 cross talk";
CM_ SG_ 894 PARK_a026_s6_overTemp "Parking assist sensors: a026 s6 over temp";
CM_ SG_ 894 PARK_a027_s6_internalFail "Parking assist sensors: a027 s6 internal fail";
CM_ SG_ 894 PARK_a028_s6_linCommError "Parking assist sensors: a028 s6 lin comm error";
CM_ SG_ 894 PARK_a029_s6_blocked "Parking assist sensors: a029 s6 blocked";
CM_ SG_ 894 PARK_a030_s6_crossTalk "Parking assist sensors: a030 s6 cross talk";
CM_ SG_ 894 PARK_a031_s7_overTemp "Parking assist sensors: a031 s7 over temp";
CM_ SG_ 894 PARK_a032_s7_internalFail "Parking assist sensors: a032 s7 internal fail";
CM_ SG_ 894 PARK_a033_s7_linCommError "Parking assist sensors: a033 s7 lin comm error";
CM_ SG_ 894 PARK_a034_s7_blocked "Parking assist sensors: a034 s7 blocked";
CM_ SG_ 894 PARK_a035_s7_crossTalk "Parking assist sensors: a035 s7 cross talk";
CM_ SG_ 894 PARK_a036_s8_overTemp "Parking assist sensors: a036 s8 over temp";
CM_ SG_ 894 PARK_a037_s8_internalFail "Parking assist sensors: a037 s8 internal fail";
CM_ SG_ 894 PARK_a038_s8_linCommError "Parking assist sensors: a038 s8 lin comm error";
CM_ SG_ 894 PARK_a039_s8_blocked "Parking assist sensors: a039 s8 blocked";
CM_ SG_ 894 PARK_a040_s8_crossTalk "Parking assist sensors: a040 s8 cross talk";
CM_ SG_ 894 PARK_a041_s9_overTemp "Parking assist sensors: a041 s9 over temp";
CM_ SG_ 894 PARK_a042_s9_internalFail "Parking assist sensors: a042 s9 internal fail";
CM_ SG_ 894 PARK_a043_s9_linCommError "Parking assist sensors: a043 s9 lin comm error";
CM_ SG_ 894 PARK_a044_s9_blocked "Parking assist sensors: a044 s9 blocked";
CM_ SG_ 894 PARK_a045_s9_crossTalk "Parking assist sensors: a045 s9 cross talk";
CM_ SG_ 894 PARK_a046_s10_overTemp "Parking assist sensors: a046 s10 over temp";
CM_ SG_ 894 PARK_a047_s10_internalFail "Parking assist sensors: a047 s10 internal fail";
CM_ SG_ 894 PARK_a048_s10_linCommError "Parking assist sensors: a048 s10 lin comm error";
CM_ SG_ 894 PARK_a049_s10_blocked "Parking assist sensors: a049 s10 blocked";
CM_ SG_ 894 PARK_a050_s10_crossTalk "Parking assist sensors: a050 s10 cross talk";
CM_ SG_ 894 PARK_a051_s11_overTemp "Parking assist sensors: a051 s11 over temp";
CM_ SG_ 894 PARK_a052_s11_internalFail "Parking assist sensors: a052 s11 internal fail";
CM_ SG_ 894 PARK_a053_s11_linCommError "Parking assist sensors: a053 s11 lin comm error";
CM_ SG_ 894 PARK_a054_s11_blocked "Parking assist sensors: a054 s11 blocked";
CM_ SG_ 894 PARK_a055_s11_crossTalk "Parking assist sensors: a055 s11 cross talk";
CM_ SG_ 894 PARK_a056_s12_overTemp "Parking assist sensors: a056 s12 over temp";
CM_ SG_ 894 PARK_a057_s12_internalFail "Parking assist sensors: a057 s12 internal fail";
CM_ SG_ 894 PARK_a058_s12_linCommError "Parking assist sensors: a058 s12 lin comm error";
CM_ SG_ 894 PARK_a059_s12_blocked "Parking assist sensors: a059 s12 blocked";
CM_ SG_ 894 PARK_a060_s12_crossTalk "Parking assist sensors: a060 s12 cross talk";
CM_ SG_ 894 PARK_a061_ecuUnderVoltage "Parking assist sensors: a061 ecu under voltage";
CM_ SG_ 894 PARK_a062_ecuOverVoltage "Parking assist sensors: a062 ecu over voltage";
CM_ SG_ 894 PARK_a063_sensorVoltage "Parking assist sensors: a063 sensor voltage";
CM_ SG_ 894 PARK_a064_ecuFault "Parking assist sensors: a064 ecu fault";
CM_ SG_ 894 PARK_a065_crcFault "Parking assist sensors: a065 crc fault";
CM_ SG_ 894 PARK_a066_calibrationMissing "Parking assist sensors: a066 calibration missing";
CM_ SG_ 894 PARK_a067_privateCANBusOff "Parking assist sensors: a067 private CAN bus off";
CM_ SG_ 894 PARK_a068_hardwareWatchDog "Parking assist sensors: a068 hardware watch dog";
CM_ SG_ 894 PARK_a069_dasMia "Parking assist sensors: a069 das mia";
CM_ SG_ 894 PARK_a070_sccmMia "Parking assist sensors: a070 sccm mia";
CM_ SG_ 894 PARK_a071_diMia "Parking assist sensors: a071 di mia";
CM_ SG_ 894 PARK_a072_epasMia "Parking assist sensors: a072 epas mia";
CM_ SG_ 894 PARK_a073_epbMia "Parking assist sensors: a073 epb mia";
CM_ SG_ 894 PARK_a074_espMia "Parking assist sensors: a074 esp mia";
CM_ SG_ 894 PARK_a075_rcmMia "Parking assist sensors: a075 rcm mia";
CM_ SG_ 894 PARK_a076_vcFrontMia "Parking assist sensors: a076 vc front mia";
CM_ SG_ 894 PARK_a077_dasError "Parking assist sensors: a077 das error";
CM_ SG_ 894 PARK_a078_diError "Parking assist sensors: a078 di error";
CM_ SG_ 894 PARK_a079_epasError "Parking assist sensors: a079 epas error";
CM_ SG_ 894 PARK_a080_epbError "Parking assist sensors: a080 epb error";
CM_ SG_ 894 PARK_a081_espError "Parking assist sensors: a081 esp error";
CM_ SG_ 894 PARK_a082_rcmError "Parking assist sensors: a082 rcm error";
CM_ SG_ 894 PARK_a083_vcFrontError "Parking assist sensors: a083 vc front error";
CM_ SG_ 894 PARK_a084_sccmError "Parking assist sensors: a084 sccm error";
CM_ SG_ 894 PARK_a085_watchdogReset "Parking assist sensors: a085 watchdog reset";
CM_ SG_ 894 PARK_a086_nvmFault "Parking assist sensors: a086 nvm fault";
CM_ SG_ 894 PARK_a087_sensorMismatchError "Parking assist sensors: a087 sensor mismatch error";
CM_ BO_ 1365 "Radar message: alert log; frame length from the layout, not yet observed on a vehicle bus";
CM_ SG_ 1365 RADC_alertID "Radar: alert ID";
CM_ SG_ 1365 RADC_alertState "Radar: alert state";
CM_ SG_ 1365 RADC_a002_ecuAdcErrType "Radar: a002 ecu adc err type";
CM_ SG_ 1365 RADC_a008_interLockErrType "Radar: a008 inter lock err type";
CM_ SG_ 1365 RADC_a011_ecuMcemErrType "Radar: a011 ecu mcem err type";
CM_ SG_ 1365 RADC_a013_ecuWdgErrType "Radar: a013 ecu wdg err type";
CM_ SG_ 1365 RADC_a016_adcOverVoltType "Radar: a016 adc over volt type";
CM_ SG_ 1365 RADC_a016_adcVoltage "Radar: a016 adc voltage";
CM_ SG_ 1365 RADC_a017_adcUnderVoltType "Radar: a017 adc under volt type";
CM_ SG_ 1365 RADC_a017_adcVoltage "Radar: a017 adc voltage";
CM_ SG_ 1365 RADC_a019_internalSWFaultType "Radar: a019 internal SW fault type";
CM_ SG_ 1365 RADC_a019_internalSWFaultCoreID "Radar: a019 internal SW fault core ID";
CM_ SG_ 1365 RADC_a020_ecuTemp "Radar: a020 ecu temp";
CM_ SG_ 1365 RADC_a023_ecuTemp "Radar: a023 ecu temp";
CM_ SG_ 1365 RADC_a025_ecuVoltage "Radar: a025 ecu voltage";
CM_ SG_ 1365 RADC_a026_ecuVoltage "Radar: a026 ecu voltage";
CM_ SG_ 1365 RADC_a027_nvmFailureType "Radar: a027 nvm failure type";
CM_ SG_ 1365 RADC_a028_rfComRegCheckFail "Radar: a028 rf com reg check fail";
CM_ SG_ 1365 RADC_a029_rhcChirpMonErrType "Radar: a029 rhc chirp mon err type";
CM_ SG_ 1365 RADC_a029_rhcRxLongTermErrType "Radar: a029 rhc rx long term err type";
CM_ SG_ 1365 RADC_a029_rhcRxErrType "Radar: a029 rhc rx err type";
CM_ SG_ 1365 RADC_a029_rhcVcoPowerErrType "Radar: a029 rhc vco power err type";
CM_ SG_ 1365 RADC_a029_rhcSp1ErrType "Radar: a029 rhc sp1 err type";
CM_ SG_ 1365 RADC_a029_rhcFdcErrType "Radar: a029 rhc fdc err type";
CM_ SG_ 1365 RADC_a030_rspErrType "Radar: a030 rsp err type";
CM_ SG_ 1365 RADC_a031_horizMisalignAngle "Radar: a031 horiz misalign angle";
CM_ SG_ 1365 RADC_a031_vertMisalignAngle "Radar: a031 vert misalign angle";
CM_ SG_ 1365 RADC_a032_blockageType "Radar: a032 blockage type";
CM_ SG_ 1365 RADC_a032_block_SPMBlockageState "Radar: a032 block SPM blockage state";
CM_ SG_ 1365 RADC_a032_block_dummy "Radar: a032 block dummy";
CM_ SG_ 1365 RADC_a032_block_SPMSelfTestState "Radar: a032 block SPM self test state";
CM_ SG_ 1365 RADC_a032_block_ucEstiRange "Radar: a032 block uc esti range";
CM_ SG_ 1365 RADC_a032_block_ucEstiRangeConf "Radar: a032 block uc esti range conf";
CM_ SG_ 1365 RADC_a032_block_ucEstiRangeProb "Radar: a032 block uc esti range prob";
CM_ SG_ 1365 RADC_a032_block_ucTimeoutBlkConf "Radar: a032 block uc timeout blk conf";
CM_ SG_ 1365 RADC_a035_msgId "Radar: a035 msg id";
CM_ SG_ 1365 RADC_a036_msgId "Radar: a036 msg id";
CM_ SG_ 1365 RADC_a037_msgId "Radar: a037 msg id";
CM_ SG_ 1365 RADC_a038_msgId "Radar: a038 msg id";
CM_ SG_ 1365 RADC_a039_msgId "Radar: a039 msg id";
CM_ SG_ 1365 RADC_a040_msgId "Radar: a040 msg id";
CM_ SG_ 1365 RADC_a041_vinErrType "Radar: a041 vin err type";
CM_ SG_ 1365 RADC_a041_vinErrExp "Radar: a041 vin err exp";
CM_ SG_ 1365 RADC_a041_vinErrRx "Radar: a041 vin err rx";
CM_ SG_ 1365 RADC_a041_msgId "Radar: a041 msg id";
CM_ SG_ 1365 RADC_a042_carConfigErrType "Radar: a042 car config err type";
CM_ SG_ 1365 RADC_a042_carConfigErrExp "Radar: a042 car config err exp";
CM_ SG_ 1365 RADC_a042_carConfigErrRx "Radar: a042 car config err rx";
CM_ SG_ 1365 RADC_a042_msgId "Radar: a042 msg id";
CM_ SG_ 1365 RADC_a043_inertialSignalsErrType "Radar: a043 inertial signals err type";
CM_ SG_ 1365 RADC_a043_inertialSignalsErrExp "Radar: a043 inertial signals err exp";
CM_ SG_ 1365 RADC_a043_inertialSignalsErrRx "Radar: a043 inertial signals err rx";
CM_ SG_ 1365 RADC_a043_msgId "Radar: a043 msg id";
CM_ SG_ 1365 RADC_a044_stwAngleErrType "Radar: a044 stw angle err type";
CM_ SG_ 1365 RADC_a044_stwAngleErrExp "Radar: a044 stw angle err exp";
CM_ SG_ 1365 RADC_a044_stwAngleErrRx "Radar: a044 stw angle err rx";
CM_ SG_ 1365 RADC_a044_msgId "Radar: a044 msg id";
CM_ SG_ 1365 RADC_a045_vehicleStateErrType "Radar: a045 vehicle state err type";
CM_ SG_ 1365 RADC_a045_vehicleStateErrExp "Radar: a045 vehicle state err exp";
CM_ SG_ 1365 RADC_a045_vehicleStateErrRx "Radar: a045 vehicle state err rx";
CM_ SG_ 1365 RADC_a045_msgId "Radar: a045 msg id";
CM_ SG_ 1365 RADC_a046_wheelSpeedsErrType "Radar: a046 wheel speeds err type";
CM_ SG_ 1365 RADC_a046_wheelSpeedsErrExp "Radar: a046 wheel speeds err exp";
CM_ SG_ 1365 RADC_a046_wheelSpeedsErrRx "Radar: a046 wheel speeds err rx";
CM_ SG_ 1365 RADC_a046_msgId "Radar: a046 msg id";
CM_ SG_ 1365 RADC_a047_chassisTypeExp "Radar: a047 chassis type exp; raw 7 = signal not available (SNA)";
CM_ SG_ 1365 RADC_a047_chassisTypeRx "Radar: a047 chassis type rx; raw 7 = signal not available (SNA)";
CM_ SG_ 1365 RADC_a048_airSuspensionExp "Radar: a048 air suspension exp; raw 7 = signal not available (SNA)";
CM_ SG_ 1365 RADC_a048_airSuspensionRx "Radar: a048 air suspension rx; raw 7 = signal not available (SNA)";
CM_ SG_ 1365 RADC_a049_fourWheelDriveExp "Radar: a049 four wheel drive exp; raw 3 = signal not available (SNA)";
CM_ SG_ 1365 RADC_a049_fourWheelDriveRx "Radar: a049 four wheel drive rx; raw 3 = signal not available (SNA)";
CM_ SG_ 1365 RADC_a050_countryExp "Radar: a050 country exp";
CM_ SG_ 1365 RADC_a050_countryRx "Radar: a050 country rx";
CM_ SG_ 1365 RADC_a051_epasTypeExp "Radar: a051 epas type exp; raw 7 = signal not available (SNA)";
CM_ SG_ 1365 RADC_a051_epasTypeRx "Radar: a051 epas type rx; raw 7 = signal not available (SNA)";
CM_ SG_ 1365 RADC_a052_radarPositionExp "Radar: a052 radar position exp; raw 7 = signal not available (SNA)";
CM_ SG_ 1365 RADC_a052_radarPositionRx "Radar: a052 radar position rx; raw 7 = signal not available (SNA)";
CM_ SG_ 1365 RADC_a054_block_ucObjLossProb "Radar: a054 block uc obj loss prob";
CM_ SG_ 1365 RADC_a054_block_ucObjLossConf "Radar: a054 block uc obj loss conf";
CM_ SG_ 1365 RADC_a054_block_ucOverallProb "Radar: a054 block uc overall prob";
CM_ SG_ 1365 RADC_a054_block_ucOverallConf "Radar: a054 block uc overall conf";
CM_ SG_ 1365 RADC_a054_block_RoadbeamTimeCnt "Radar: a054 block roadbeam time cnt";
CM_ SG_ 1365 RADC_a055_block_usTimeoutWayCnt "Radar: a055 block us timeout way cnt";
CM_ SG_ 1365 RADC_a055_block_ucTimeoutTimeCnt "Radar: a055 block uc timeout time cnt";
CM_ SG_ 1365 RADC_a055_bblock_ucTimeoutBlkPro "Radar: a055 bblock uc timeout blk prob";
CM_ SG_ 1365 RADC_a055_block_usFullBlkTimer "Radar: a055 block us full blk timer";
CM_ BO_ 1282 "Radar message: alert matrix0; frame length from the layout, not yet observed on a vehicle bus";
CM_ SG_ 1282 RADC_a001_can1BusOff "Radar: a001 can1 bus off";
CM_ SG_ 1282 RADC_a002_ecuAdcError "Radar: a002 ecu adc error";
CM_ SG_ 1282 RADC_a003_ecuBistDisabled "Radar: a003 ecu bist disabled";
CM_ SG_ 1282 RADC_a004_ecuCrcHwError "Radar: a004 ecu crc hw error";
CM_ SG_ 1282 RADC_a005_ecuEcuMError "Radar: a005 ecu ecu m error";
CM_ SG_ 1282 RADC_a006_ecuFimError "Radar: a006 ecu fim error";
CM_ SG_ 1282 RADC_a007_ecuGptCheckError "Radar: a007 ecu gpt check error";
CM_ SG_ 1282 RADC_a008_ecuHwSwInterlock "Radar: a008 ecu hw sw interlock";
CM_ SG_ 1282 RADC_a009_plantModeActive "Radar: a009 plant mode active";
CM_ SG_ 1282 RADC_a010_ecuIoHwAbError "Radar: a010 ecu io hw ab error";
CM_ SG_ 1282 RADC_a011_ecuMcemError "Radar: a011 ecu mcem error";
CM_ SG_ 1282 RADC_a012_ecuSpiError "Radar: a012 ecu spi error";
CM_ SG_ 1282 RADC_a013_ecuWdgError "Radar: a013 ecu wdg error";
CM_ SG_ 1282 RADC_a014_fctSelfTestNotDone "Radar: a014 fct self test not done";
CM_ SG_ 1282 RADC_a015_fctSenInterference "Radar: a015 fct sen interference";
CM_ SG_ 1282 RADC_a016_adcOverVolt "Radar: a016 adc over volt";
CM_ SG_ 1282 RADC_a017_adcUnderVolt "Radar: a017 adc under volt";
CM_ SG_ 1282 RADC_a018_internalHardwareFault "Radar: a018 internal hardware fault";
CM_ SG_ 1282 RADC_a019_internalSoftwareFault "Radar: a019 internal software fault";
CM_ SG_ 1282 RADC_a020_overTemp "Radar: a020 over temp";
CM_ SG_ 1282 RADC_a021_overTempCrit "Radar: a021 over temp crit";
CM_ SG_ 1282 RADC_a022_tempImplausible "Radar: a022 temp implausible";
CM_ SG_ 1282 RADC_a023_underTemp "Radar: a023 under temp";
CM_ SG_ 1282 RADC_a024_underTempCrit "Radar: a024 under temp crit";
CM_ SG_ 1282 RADC_a025_overVoltage "Radar: a025 over voltage";
CM_ SG_ 1282 RADC_a026_underVoltage "Radar: a026 under voltage";
CM_ SG_ 1282 RADC_a027_nvmFailure "Radar: a027 nvm failure";
CM_ SG_ 1282 RADC_a028_rfChipError "Radar: a028 rf chip error";
CM_ SG_ 1282 RADC_a029_rhcError "Radar: a029 rhc error";
CM_ SG_ 1282 RADC_a030_rspError "Radar: a030 rsp error";
CM_ SG_ 1282 RADC_a031_sensorMisaligned "Radar: a031 sensor misaligned";
CM_ SG_ 1282 RADC_a032_sensorBlocked "Radar: a032 sensor blocked";
CM_ SG_ 1282 RADC_a033_sensorNeverAligned "Radar: a033 sensor never aligned";
CM_ SG_ 1282 RADC_a034_vehDynamicsError "Radar: a034 veh dynamics error";
CM_ SG_ 1282 RADC_a035_vinMIA "Radar: a035 vin MIA";
CM_ SG_ 1282 RADC_a036_carConfigMIA "Radar: a036 car config MIA";
CM_ SG_ 1282 RADC_a037_inertialSignalsMIA "Radar: a037 inertial signals MIA";
CM_ SG_ 1282 RADC_a038_steeringWheelAngleMIA "Radar: a038 steering wheel angle MIA";
CM_ SG_ 1282 RADC_a039_vehicleStateMIA "Radar: a039 vehicle state MIA";
CM_ SG_ 1282 RADC_a040_wheelSpeedsMIA "Radar: a040 wheel speeds MIA";
CM_ SG_ 1282 RADC_a041_vinErr "Radar: a041 vin err";
CM_ SG_ 1282 RADC_a042_carConfigErr "Radar: a042 car config err";
CM_ SG_ 1282 RADC_a043_inertialSignalsErr "Radar: a043 inertial signals err";
CM_ SG_ 1282 RADC_a044_steeringWheelAngleErr "Radar: a044 steering wheel angle err";
CM_ SG_ 1282 RADC_a045_vehicleStateErr "Radar: a045 vehicle state err";
CM_ SG_ 1282 RADC_a046_wheelSpeedsErr "Radar: a046 wheel speeds err";
CM_ SG_ 1282 RADC_a047_mismatchChassisType "Radar: a047 mismatch chassis type";
CM_ SG_ 1282 RADC_a048_mismatchAirSuspension "Radar: a048 mismatch air suspension";
CM_ SG_ 1282 RADC_a049_mismatchFourWheelDrive "Radar: a049 mismatch four wheel drive";
CM_ SG_ 1282 RADC_a050_mismatchCountry "Radar: a050 mismatch country";
CM_ SG_ 1282 RADC_a051_mismatchEPASType "Radar: a051 mismatch EPAS type";
CM_ SG_ 1282 RADC_a052_mismatcRadPos "Radar: a052 mismatc rad pos";
CM_ SG_ 1282 RADC_a053_emError "Radar: a053 em error";
CM_ SG_ 1282 RADC_a054_blockageInfo_Frame_1 "Radar: a054 blockage info frame 1";
CM_ SG_ 1282 RADC_a055_blockageInfo_Frame_2 "Radar: a055 blockage info frame 2";
CM_ BO_ 1329 "Radar message: info; frame length from the layout, not yet observed on a vehicle bus";
CM_ SG_ 1329 RADC_infoIndex "Radar: info index";
CM_ SG_ 1329 RADC_infoBuildType "Radar: info build type";
CM_ SG_ 1329 RADC_infoBuildConfigID "Radar: info build config ID";
CM_ SG_ 1329 RADC_infoHardwareID "Radar: info hardware ID";
CM_ SG_ 1329 RADC_infoComponentID "Radar: info component ID";
CM_ SG_ 1329 RADC_infoPcbaID "Radar: info pcba ID";
CM_ SG_ 1329 RADC_infoAssemblyID "Radar: info assembly ID";
CM_ SG_ 1329 RADC_infoUsageID "Radar: info usage ID";
CM_ SG_ 1329 RADC_infoSubUsageID "Radar: info sub usage ID";
CM_ SG_ 1329 RADC_infoApplicationCRC "Radar: info application CRC";
CM_ SG_ 1329 RADC_infoPlatformType "Radar: info platform type";
CM_ SG_ 1329 RADC_infoMajorVersion "Radar: info major version";
CM_ SG_ 1329 RADC_infoBranchOrigin "Radar: info branch origin";
CM_ SG_ 1329 RADC_infoMaturity "Radar: info maturity";
CM_ SG_ 1329 RADC_infoHardwareRevision "Radar: info hardware revision";
CM_ SG_ 1329 RADC_infoBootUdsProtoVersion "Radar: info boot uds proto version";
CM_ SG_ 1329 RADC_infoBootloaderCRC "Radar: info bootloader CRC";
CM_ BO_ 1252 "RCM3 ECU message: alert log; frame length from the layout, not yet observed on a vehicle bus";
CM_ SG_ 1252 RCM3_alertID "RCM3 ECU: alert ID";
CM_ SG_ 1252 RCM3_alertState "RCM3 ECU: alert state";
CM_ BO_ 1010 "RCM3 ECU message: alert matrix; frame length from the layout, not yet observed on a vehicle bus";
CM_ SG_ 1010 RCM3_matrixIndex "RCM3 ECU: matrix index";
CM_ SG_ 1010 RCM3_a001_LVPowerLossDetected "RCM3 ECU: a001 LV power loss detected";
CM_ BO_ 257 "Restraint control module message: inertial1; frame length from the layout, not yet observed on a vehicle bus";
CM_ SG_ 257 RCM_yawRate "Offset compensated yaw rate measured by the airbag ECU. ISO axis convention (Positive during left turn); raw 32768 = signal not available (SNA)";
CM_ SG_ 257 RCM_pitchRate "Offset compensated pitch rate measured by the airbag ECU. ISO axis convention (positive when the nose pitches down); raw 16384 = signal not available (SNA)";
CM_ SG_ 257 RCM_rollRate "Offset compensated roll rate measured by the airbag ECU. ISO axis convention (positive during left turn); raw 16384 = signal not available (SNA)";
CM_ SG_ 257 RCM_rollRateQF "Restraint control module: roll rate QF";
CM_ SG_ 257 RCM_yawRateQF "Restraint control module: yaw rate QF";
CM_ SG_ 257 RCM_pitchRateQF "Restraint control module: pitch rate QF";
CM_ SG_ 257 RCM_inertial1Counter "Restraint control module: inertial1 counter";
CM_ SG_ 257 RCM_inertial1Checksum "Restraint control module: inertial1 checksum";
CM_ BO_ 273 "Restraint control module message: inertial2; frame length from the layout, not yet observed on a vehicle bus";
CM_ SG_ 273 RCM_longitudinalAccel "Offset compensated longitudinal acceleration measured by the airbag ECU. ISO axis convention (positive during forward acceleration); raw 32768 = signal not available (SNA)";
CM_ SG_ 273 RCM_lateralAccel "Reports offset compensated lateral acceleration measured by the airbag ECU. Follows ISO axis convention that measurements are positive during left turns and negative during right turns; raw 32768 = signal not available (SNA)";
CM_ SG_ 273 RCM_verticalAccel "Offset compensated vertical acceleration measured by the airbag ECU. ISO axis convention (positive up); raw 32768 = signal not available (SNA)";
CM_ SG_ 273 RCM_longitudinalAccelQF "Restraint control module: longitudinal accel QF";
CM_ SG_ 273 RCM_lateralAccelQF "Restraint control module: lateral accel QF";
CM_ SG_ 273 RCM_verticalAccelQF "Restraint control module: vertical accel QF";
CM_ SG_ 273 RCM_CGTranslationFault "Restraint control module: CG translation fault";
CM_ SG_ 273 RCM_inertial2Counter "Restraint control module: inertial2 counter";
CM_ SG_ 273 RCM_inertial2Checksum "Restraint control module: inertial2 checksum";
CM_ BO_ 849 "Restraint control module message: info; frame length from the layout, not yet observed on a vehicle bus";
CM_ SG_ 849 RCM_infoIndex "Restraint control module: info index";
CM_ SG_ 849 RCM_infoBuildType "Restraint control module: info build type";
CM_ SG_ 849 RCM_infoComponentID "Restraint control module: info component ID";
CM_ SG_ 849 RCM_infoPcbaID "Reports the Restraint Control Module (RCM) Printed Circuit Board Assembly (PCBA) identifier.";
CM_ SG_ 849 RCM_infoAssemblyID "Restraint control module: info assembly ID";
CM_ SG_ 849 RCM_infoUsageID "Reports the Restraint Control Module (RCM) usage identification.";
CM_ SG_ 849 RCM_infoApplicationCRC "Reports the Restraint Control Module (RCM) application Cyclic Redundancy Check (CRC).";
CM_ SG_ 849 RCM_infoBootUdsProtoVersion "Reports the Restraint Control Module (RCM) boot Unified Diagnostic Services (UDS) protocol version.";
CM_ SG_ 849 RCM_infoBootloaderCRC "Reports the Restraint Control Module (RCM) bootloader Cyclic Redundancy Check (CRC).";
CM_ SG_ 849 RCM_infoAlgoCalID "Reports the Restraint Control Module (RCM) algorithm calibration identification.";
CM_ SG_ 849 RCM_infoVariantCRC "Reports the Restraint Control Module (RCM) variant Cyclic Redundancy Check (CRC).";
CM_ BO_ 529 "Restraint control module message: status; frame length from the layout, not yet observed on a vehicle bus";
CM_ SG_ 529 RCM_statusChecksum "Restraint control module: status checksum";
CM_ SG_ 529 RCM_statusCounter "Restraint control module: status counter";
CM_ SG_ 529 RCM_armStatus "Reports the arm status of the Restraint Control Module (RCM); raw 3 = signal not available (SNA)";
CM_ SG_ 529 RCM_warningIndicatorState "Reports whether the Restraint Control Module (RCM) warning indicator is present on the User Interface (UI); raw 3 = signal not available (SNA)";
CM_ SG_ 529 RCM_passAirbagIndicatorRequest "Reports status of the Front Passenger Airbag Off telltale; raw 3 = signal not available (SNA)";
CM_ SG_ 529 RCM_airbagCutoffStatus "Reports the front passenger airbag enabled or disabled status; raw 3 = signal not available (SNA)";
CM_ SG_ 529 RCM_alrSwitchStatus "Reports status of the front passenger automatic locking seat belt retractor; raw 3 = signal not available (SNA)";
CM_ SG_ 529 RCM_vinLearnFlag "Reports whether the Vehicle Identification Number has been learned; raw 3 = signal not available (SNA)";
CM_ SG_ 529 RCM_seatTrackPositionDrvr "Driver seat track position status; raw 3 = signal not available (SNA)";
CM_ SG_ 529 RCM_seatTrackPositionPass "Passenger seat track position status; raw 3 = signal not available (SNA)";
CM_ SG_ 529 RCM_edr1State "Reports status of Restraint Control Module (RCM) Event Data Recorder (EDR) memory slot 1.";
CM_ SG_ 529 RCM_edr2State "Reports status of Restraint Control Module (RCM) Event Data Recorder (EDR) memory slot 2.";
CM_ SG_ 529 RCM_keepPowerReason "Restraint Control Module request to maintain power; raw 8 = signal not available (SNA)";
CM_ SG_ 529 RCM_imuOffsetLearnState "Restraint control module: imu offset learn state";
CM_ SG_ 529 RCM_edr3State "Reports status of Restraint Control Module (RCM) Event Data Recorder (EDR) memory slot 3.";
CM_ SG_ 529 RCM_driverOrientationInitStatus "Restraint control module: driver orientation init status; raw 7 = signal not available (SNA)";
CM_ SG_ 529 RCM_occupantClassificationSource "Indicates whether the occupant classification source is the Right Vehicle Controller (VCRIGHT) or the Occupancy Classification System - 1st Row Passenger (OCS1P).";
CM_ SG_ 529 RCM_pedProEDR1State "Reports status of the PedPro Event Data Recorder (EDR) memory slot 1.";
CM_ SG_ 529 RCM_pedProEDR2State "Reports status of the PedPro Event Data Recorder (EDR) memory slot 2.";
CM_ BO_ 831 "RCU ECU message: info; frame length from the layout, not yet observed on a vehicle bus";
CM_ SG_ 831 RCU_infoIndex "RCU ECU: info index";
CM_ SG_ 831 RCU_infoPcbaID "RCU ECU: info pcba ID";
CM_ SG_ 831 RCU_infoAssemblyID "RCU ECU: info assembly ID";
CM_ SG_ 831 RCU_infoUsageID "RCU ECU: info usage ID";
CM_ SG_ 831 RCU_infoSubUsageID "RCU ECU: info sub usage ID";
CM_ BO_ 879 "Tire pressure monitoring message: status c; frame length from the layout, not yet observed on a vehicle bus";
CM_ SG_ 879 TPMS_c_globalHardWarning "Tire pressure monitoring: c global hard warning";
CM_ SG_ 879 TPMS_c_globalSoftWarning "Tire pressure monitoring: c global soft warning";
CM_ SG_ 879 TPMS_systemMalfunction "Tire pressure monitoring: system malfunction";
CM_ SG_ 879 TPMS_WA_version "Tire pressure monitoring: WA version";
CM_ SG_ 879 TPMS_globalDeltaPressure "Tire pressure monitoring: global delta pressure";
CM_ SG_ 879 TPMS_newSensorLearnt "Tire pressure monitoring: new sensor learnt";
CM_ SG_ 879 TPMS_softWarningRR "Tire pressure monitoring: soft warning RR";
CM_ SG_ 879 TPMS_hardWarningRR "Tire pressure monitoring: hard warning RR";
CM_ SG_ 879 TPMS_softWarningRL "Tire pressure monitoring: soft warning RL";
CM_ SG_ 879 TPMS_hardWarningRL "Tire pressure monitoring: hard warning RL";
CM_ SG_ 879 TPMS_softWarningFR "Tire pressure monitoring: soft warning FR";
CM_ SG_ 879 TPMS_hardWarningFR "Tire pressure monitoring: hard warning FR";
CM_ SG_ 879 TPMS_softWarningFL "Tire pressure monitoring: soft warning FL";
CM_ SG_ 879 TPMS_hardWarningFL "Tire pressure monitoring: hard warning FL";
CM_ SG_ 879 TPMS_learningStatus "Monitors Tire Pressure Monitoring System (TPMS) Learn Status and evaluates issues.";
CM_ SG_ 879 TPMS_localisationStatus "Monitors Tire Pressure Monitoring System (TPMS) Localization Status and evaluates issues.";
CM_ SG_ 879 TPMS_deltaPressWarningFL "Tire pressure monitoring: delta press warning FL";
CM_ SG_ 879 TPMS_deltaPressWarningFR "Tire pressure monitoring: delta press warning FR";
CM_ SG_ 879 TPMS_deltaPressWarningRL "Tire pressure monitoring: delta press warning RL";
CM_ SG_ 879 TPMS_deltaPressWarningRR "Tire pressure monitoring: delta press warning RR";
CM_ SG_ 879 TPMS_sensorNoResponseFL "Count of times Front Left sensor did not respond to message";
CM_ SG_ 879 TPMS_sensorNoResponseFR "Count of times Front Right sensor did not respond to message";
CM_ SG_ 879 TPMS_sensorNoResponseRL "Count of times Rear Left sensor did not respond to message";
CM_ SG_ 879 TPMS_sensorNoResponseRR "Count of times Rear Right sensor did not respond to message";
CM_ SG_ 879 TPMS_sensorThermShutdownFL "Tire pressure monitoring: sensor therm shutdown FL";
CM_ SG_ 879 TPMS_sensorThermShutdownFR "Tire pressure monitoring: sensor therm shutdown FR";
CM_ SG_ 879 TPMS_sensorThermShutdownRL "Tire pressure monitoring: sensor therm shutdown RL";
CM_ SG_ 879 TPMS_sensorThermShutdownRR "Tire pressure monitoring: sensor therm shutdown RR";
CM_ SG_ 879 TPMS_sensorBatteryLowFL "Tracks near end of life sensor batteries in the fleet.";
CM_ SG_ 879 TPMS_sensorBatteryLowFR "Tracks near end of life sensor batteries in the fleet.";
CM_ SG_ 879 TPMS_sensorBatteryLowRL "Tracks near end of life sensor batteries in the fleet.";
CM_ SG_ 879 TPMS_sensorBatteryLowRR "Tracks near end of life sensor batteries in the fleet.";
CM_ SG_ 879 TPMS_sensorDefectiveFL "Tracks malfunctioning sensors in the fleet.";
CM_ SG_ 879 TPMS_sensorDefectiveFR "Tracks malfunctioning sensors in the fleet.";
CM_ SG_ 879 TPMS_sensorDefectiveRL "Tracks malfunctioning sensors in the fleet.";
CM_ SG_ 879 TPMS_sensorDefectiveRR "Tracks malfunctioning sensors in the fleet.";
CM_ SG_ 879 TPMS_ecuUnderVoltage "Tire pressure monitoring: ecu under voltage";
CM_ SG_ 879 TPMS_ecuOverVoltage "Tire pressure monitoring: ecu over voltage";
CM_ SG_ 879 TPMS_ecuRamRomNvMFail "Tire pressure monitoring: ecu ram rom nv m fail";
CM_ SG_ 879 TPMS_rfReceiverFail "Tire pressure monitoring: rf receiver fail";
CM_ SG_ 879 TPMS_wheelPulseMissing "Tire pressure monitoring: wheel pulse missing";
CM_ SG_ 879 TPMS_vehicleSpeedFail "Tire pressure monitoring: vehicle speed fail";
CM_ SG_ 879 TPMS_externalTemperatureFail "Tire pressure monitoring: external temperature fail";
CM_ SG_ 879 TPMS_eolNotCompleted "Monitors sensor completion of End of Line (EOL) routine.";
CM_ SG_ 879 TPMS_rcpFront "Front tire recommended cold pressure";
CM_ SG_ 879 TPMS_rcpRear "Rear tire recommended cold pressure";
CM_ BO_ 799 "Tire pressure monitoring message: data; frame length from the layout, not yet observed on a vehicle bus";
CM_ SG_ 799 TPMS_pressureFL "front left tire pressure; raw 255 = signal not available (SNA)";
CM_ SG_ 799 TPMS_temperatureFL "front left tire temperature; raw 255 = signal not available (SNA)";
CM_ SG_ 799 TPMS_pressureFR "front right tire pressure; raw 255 = signal not available (SNA)";
CM_ SG_ 799 TPMS_temperatureFR "front right tire temperature; raw 255 = signal not available (SNA)";
CM_ SG_ 799 TPMS_pressureRL "rear left tire pressure; raw 255 = signal not available (SNA)";
CM_ SG_ 799 TPMS_temperatureRL "rear left tire temperature; raw 255 = signal not available (SNA)";
CM_ SG_ 799 TPMS_pressureRR "rear right tire pressure; raw 255 = signal not available (SNA)";
CM_ SG_ 799 TPMS_temperatureRR "rear right tire temperature; raw 255 = signal not available (SNA)";
CM_ BO_ 1519 "Tire pressure monitoring message: info; frame length from the layout, not yet observed on a vehicle bus";
CM_ SG_ 1519 TPMS_infoIndex "Tire pressure monitoring: info index";
CM_ SG_ 1519 TPMS_infoComponentID "Tire pressure monitoring: info component ID";
CM_ SG_ 1519 TPMS_infoPcbaID "Tire pressure monitoring: info pcba ID";
CM_ SG_ 1519 TPMS_infoAssemblyID "Tire pressure monitoring: info assembly ID";
CM_ SG_ 1519 TPMS_infoUsageID "Tire pressure monitoring: info usage ID";
CM_ SG_ 1519 TPMS_infoApplicationCRC "Tire pressure monitoring: info application CRC";
CM_ SG_ 1519 TPMS_infoBootUdsProtoVersion "Tire pressure monitoring: info boot uds proto version";
CM_ SG_ 1519 TPMS_infoBootloaderCRC "Tire pressure monitoring: info bootloader CRC";
CM_ BO_ 659 "Touchscreen user interface computer message: chassis control; forwarded onto this bus by the gateway; frame length from the layout, not yet observed on a vehicle bus";
CM_ SG_ 659 UI_steeringTuneRequest "UI customer level request for steering feel. MS had comfort, normal, sport. M3 intent is Normal, sport see SW-95934";
CM_ SG_ 659 UI_tractionControlMode "Transport user selected traction control modes";
CM_ SG_ 659 UI_parkBrakeRequest "User selection for Park brake; raw 3 = signal not available (SNA)";
CM_ SG_ 659 UI_narrowGarages "Touchscreen user interface computer: narrow garages";
CM_ SG_ 659 UI_winchModeRequest "Winch mode (towing) request";
CM_ SG_ 659 UI_zeroSpeedConfirmed "Touchscreen user interface computer: zero speed confirmed; raw 3 = signal not available (SNA)";
CM_ SG_ 659 UI_trailerMode "Indicates whether trailer mode is selected. To be used when towing a trailer.";
CM_ SG_ 659 UI_distanceUnits "Touchscreen user interface computer: distance units";
CM_ SG_ 659 UI_dasDebugEnable "Touchscreen user interface computer: das debug enable";
CM_ SG_ 659 UI_accOvertakeEnable "Enable ACC Overtake assistance (reduce follow distance when the turn signal is on), UI firmware only sets datavalue to True; raw 3 = signal not available (SNA)";
CM_ SG_ 659 UI_aebEnable "Enable Autonomous Emergency Brakes; raw 3 = signal not available (SNA)";
CM_ SG_ 659 UI_aesEnable "Enable Automatic Emergency Steering (associated datavalue set to true and never changed by UI firmware); raw 3 = signal not available (SNA)";
CM_ SG_ 659 UI_ahlbEnable "Enable Automatic High/Low Beams; raw 3 = signal not available (SNA)";
CM_ SG_ 659 UI_autoLaneChangeEnable "Enable Automatic Lane Change; raw 3 = signal not available (SNA)";
CM_ SG_ 659 UI_winchProxUserOverride "User feedback from tow mode panel confirming that charge cable is disconnected when vehicle is unable to determine cable status";
CM_ SG_ 659 UI_rebootAutopilot "Touchscreen user interface computer: reboot autopilot";
CM_ SG_ 659 UI_autoParkRequest "Request Automatic Parking; raw 15 = signal not available (SNA)";
CM_ SG_ 659 UI_bsdEnable "Enable Blind Spot Detection (datavalue defaults to true and not changed by UI firmware); raw 3 = signal not available (SNA)";
CM_ SG_ 659 UI_fcwEnable "Enable Forward Collision Warning; raw 3 = signal not available (SNA)";
CM_ SG_ 659 UI_fcwSensitivity "Forward Collision Warning Level; raw 3 = signal not available (SNA)";
CM_ SG_ 659 UI_latControlEnable "Enable Lateral Control (lane centering, lane keeping, lane changing); raw 3 = signal not available (SNA)";
CM_ SG_ 659 UI_ldwEnable "Enable Lane Departure Warning; raw 3 = signal not available (SNA)";
CM_ SG_ 659 UI_pedalSafetyEnable "Touchscreen user interface computer: pedal safety enable; raw 3 = signal not available (SNA)";
CM_ SG_ 659 UI_pedalMap_epas "Touchscreen user interface computer: pedal map epas";
CM_ SG_ 659 UI_redLightStopSignEnable "Touchscreen user interface computer: red light stop sign enable; raw 3 = signal not available (SNA)";
CM_ SG_ 659 UI_selfParkTune "Touchscreen user interface computer: self park tune; raw 15 = signal not available (SNA)";
CM_ SG_ 659 UI_chassisControlCounter "Touchscreen user interface computer: chassis control counter";
CM_ SG_ 659 UI_chassisControlChecksum "Touchscreen user interface computer: chassis control checksum";
CM_ BO_ 664 "Touchscreen user interface computer message: csa offramp curvature; forwarded onto this bus by the gateway; frame length from the layout, not yet observed on a vehicle bus";
CM_ SG_ 664 UI_csaOfframpCurvC2 "Touchscreen user interface computer: csa offramp curv C2";
CM_ SG_ 664 UI_csaOfframpCurvC3 "Touchscreen user interface computer: csa offramp curv C3";
CM_ SG_ 664 UI_csaOfframpCurvRange "Touchscreen user interface computer: csa offramp curv range";
CM_ SG_ 664 UI_csaOfframpCurvCounter "Touchscreen user interface computer: csa offramp curv counter";
CM_ SG_ 664 UI_csaOfframpCurvUsingTspline "Touchscreen user interface computer: csa offramp curv using tspline";
CM_ SG_ 664 UI_csaOfframpCurvReserved "Touchscreen user interface computer: csa offramp curv reserved";
CM_ SG_ 664 UI_csaOfframpCurvChecksum "Touchscreen user interface computer: csa offramp curv checksum";
CM_ BO_ 679 "Touchscreen user interface computer message: csa road curvature; forwarded onto this bus by the gateway; frame length from the layout, not yet observed on a vehicle bus";
CM_ SG_ 679 UI_csaRoadCurvC2 "Touchscreen user interface computer: csa road curv C2";
CM_ SG_ 679 UI_csaRoadCurvC3 "Touchscreen user interface computer: csa road curv C3";
CM_ SG_ 679 UI_csaRoadCurvRange "Touchscreen user interface computer: csa road curv range";
CM_ SG_ 679 UI_csaRoadCurvCounter "Touchscreen user interface computer: csa road curv counter";
CM_ SG_ 679 UI_csaRoadCurvUsingTspline "Touchscreen user interface computer: csa road curv using tspline";
CM_ SG_ 679 UI_csaRoadCurvReserved "Touchscreen user interface computer: csa road curv reserved";
CM_ SG_ 679 UI_csaRoadCurvChecksum "Touchscreen user interface computer: csa road curv checksum";
CM_ BO_ 1096 "Touchscreen user interface computer message: driver assist anon debug params; forwarded onto this bus by the gateway; frame length from the layout, not yet observed on a vehicle bus";
CM_ SG_ 1096 UI_anonDebugParam1 "Touchscreen user interface computer: anon debug param1";
CM_ SG_ 1096 UI_anonDebugFlag1 "Touchscreen user interface computer: anon debug flag1";
CM_ SG_ 1096 UI_anonDebugParam2 "Touchscreen user interface computer: anon debug param2";
CM_ SG_ 1096 UI_anonDebugFlag2 "Touchscreen user interface computer: anon debug flag2";
CM_ SG_ 1096 UI_anonDebugParam3 "Touchscreen user interface computer: anon debug param3";
CM_ SG_ 1096 UI_anonDebugFlag3 "Touchscreen user interface computer: anon debug flag3";
CM_ SG_ 1096 UI_anonDebugParam4 "Touchscreen user interface computer: anon debug param4";
CM_ SG_ 1096 UI_anonDebugFlag4 "Touchscreen user interface computer: anon debug flag4";
CM_ SG_ 1096 UI_anonDebugParam5 "Touchscreen user interface computer: anon debug param5";
CM_ SG_ 1096 UI_anonDebugParam6 "Touchscreen user interface computer: anon debug param6";
CM_ SG_ 1096 UI_anonDebugParam7 "Touchscreen user interface computer: anon debug param7";
CM_ SG_ 1096 UI_visionSpeedSlider "Touchscreen user interface computer: vision speed slider";
CM_ BO_ 1016 "Touchscreen user interface computer message: driver assist control; forwarded onto this bus by the gateway; frame length from the layout, not yet observed on a vehicle bus";
CM_ SG_ 1016 UI_autopilotControlRequest "Touchscreen user interface computer: autopilot control request";
CM_ SG_ 1016 UI_ulcStalkConfirm "Drive on autopilot stalk confirmation mode (set by feature config).";
CM_ SG_ 1016 UI_summonHeartbeat "Touchscreen user interface computer: summon heartbeat";
CM_ SG_ 1016 UI_curvSpeedAdaptDisable "Touchscreen user interface computer: curv speed adapt disable";
CM_ SG_ 1016 UI_dasDeveloper "Touchscreen user interface computer: das developer";
CM_ SG_ 1016 UI_enableVinAssociation "Touchscreen user interface computer: enable vin association";
CM_ SG_ 1016 UI_lssLkaEnabled "User setting for lane keep assist";
CM_ SG_ 1016 UI_lssLdwEnabled "User setting for lane departure warning";
CM_ SG_ 1016 UI_coastToCoast "Touchscreen user interface computer: coast to coast";
CM_ SG_ 1016 UI_autoSummonEnable "Touchscreen user interface computer: auto summon enable";
CM_ SG_ 1016 UI_exceptionListEnable "Touchscreen user interface computer: exception list enable";
CM_ SG_ 1016 UI_roadCheckDisable "Touchscreen user interface computer: road check disable";
CM_ SG_ 1016 UI_driveOnMapsEnable "Drive on Autopilot enabled";
CM_ SG_ 1016 UI_handsOnRequirementDisable "Touchscreen user interface computer: hands on requirement disable";
CM_ SG_ 1016 UI_ulcOffHighway "Touchscreen user interface computer: ulc off highway";
CM_ SG_ 1016 UI_fuseLanesDisable "Touchscreen user interface computer: fuse lanes disable";
CM_ SG_ 1016 UI_fuseHPPDisable "Touchscreen user interface computer: fuse HPP disable";
CM_ SG_ 1016 UI_fuseVehiclesDisable "Touchscreen user interface computer: fuse vehicles disable";
CM_ SG_ 1016 UI_enableClipParkedTelemetry "Touchscreen user interface computer: enable clip parked telemetry";
CM_ SG_ 1016 UI_visionSpeedType "Touchscreen user interface computer: vision speed type";
CM_ SG_ 1016 UI_curvatureDatabaseOnly "Touchscreen user interface computer: curvature database only";
CM_ SG_ 1016 UI_lssElkEnabled "User setting for emergency lane keep";
CM_ SG_ 1016 UI_summonExitType "Touchscreen user interface computer: summon exit type; raw 3 = signal not available (SNA)";
CM_ SG_ 1016 UI_summonEntryType "Touchscreen user interface computer: summon entry type; raw 3 = signal not available (SNA)";
CM_ SG_ 1016 UI_selfParkRequest "Self park request; raw 15 = signal not available (SNA)";
CM_ SG_ 1016 UI_summonReverseDist "Touchscreen user interface computer: summon reverse dist; raw 63 = signal not available (SNA)";
CM_ SG_ 1016 UI_undertakeAssistEnable "Touchscreen user interface computer: undertake assist enable";
CM_ SG_ 1016 UI_adaptiveSetSpeedEnable "Touchscreen user interface computer: adaptive set speed enable";
CM_ SG_ 1016 UI_drivingSide "Touchscreen user interface computer: driving side";
CM_ SG_ 1016 UI_enableClipTelemetry "Touchscreen user interface computer: enable clip telemetry";
CM_ SG_ 1016 UI_enableTripTelemetry "Touchscreen user interface computer: enable trip telemetry";
CM_ SG_ 1016 UI_enableRoadSegmentTelemetry "Touchscreen user interface computer: enable road segment telemetry";
CM_ SG_ 1016 UI_accFollowDistanceSetting "Touchscreen user interface computer: acc follow distance setting; raw 7 = signal not available (SNA)";
CM_ SG_ 1016 UI_hasDriveOnNav "Touchscreen user interface computer: has drive on nav";
CM_ SG_ 1016 UI_followNavRouteEnable "Following route with Drive on Autopilot";
CM_ SG_ 1016 UI_ulcSpeedConfig "Drive on autopilot speed base lane changes mode.";
CM_ SG_ 1016 UI_ulcBlindSpotConfig "Touchscreen user interface computer: ulc blind spot config";
CM_ SG_ 1016 UI_suppressExitPassingLane "Navigate on Autopilot will not suggest lane changes out of the passing lane";
CM_ SG_ 1016 UI_enableClipStartStopTelemetry "Touchscreen user interface computer: enable clip start stop telemetry";
CM_ SG_ 1016 UI_alcOffHighwayEnable "Touchscreen user interface computer: alc off highway enable";
CM_ SG_ 1016 UI_validationLoop "Touchscreen user interface computer: validation loop";
CM_ SG_ 1016 UI_smartSummonType "Type of smart summon session (Find Me, Pin Drop, Smart Autopark)";
CM_ SG_ 1016 UI_enableVisionOnlyStops "Touchscreen user interface computer: enable vision only stops";
CM_ SG_ 1016 UI_source3D "Touchscreen user interface computer: source3 d";
CM_ SG_ 1016 UI_isaSpeedingChimeMuted "Reports the user input of Intelligent Speed Assist (ISA) speed chime alert option.";
CM_ BO_ 568 "Touchscreen user interface computer message: driver assist map data; forwarded onto this bus by the gateway; frame length from the layout, not yet observed on a vehicle bus";
CM_ SG_ 568 UI_mapSpeedLimitDependency "Touchscreen user interface computer: map speed limit dependency; raw 7 = signal not available (SNA)";
CM_ SG_ 568 UI_roadClass "Autopilot map road class; raw 0 = signal not available (SNA)";
CM_ SG_ 568 UI_inSuperchargerGeofence "Touchscreen user interface computer: in supercharger geofence";
CM_ SG_ 568 UI_mapSpeedUnits "Touchscreen user interface computer: map speed units";
CM_ SG_ 568 UI_mapSpeedLimit "Touchscreen user interface computer: map speed limit; raw 31 = signal not available (SNA)";
CM_ SG_ 568 UI_mapSpeedLimitType "Touchscreen user interface computer: map speed limit type; raw 7 = signal not available (SNA)";
CM_ SG_ 568 UI_countryCode "Touchscreen user interface computer: country code; raw 1023 = signal not available (SNA)";
CM_ SG_ 568 UI_streetCount "Touchscreen user interface computer: street count";
CM_ SG_ 568 UI_gpsRoadMatch "Touchscreen user interface computer: gps road match";
CM_ SG_ 568 UI_navRouteActive "Navigation route is active";
CM_ SG_ 568 UI_parallelAutoparkEnabled "Autopilot map parallel park enabled.";
CM_ SG_ 568 UI_perpendicularAutoparkEnabled "Autopilot map perpendicular park enabled.";
CM_ SG_ 568 UI_nextBranchDist "Touchscreen user interface computer: next branch dist; raw 31 = signal not available (SNA)";
CM_ SG_ 568 UI_controlledAccess "DAS map controlled access segment.";
CM_ SG_ 568 UI_nextBranchLeftOffRamp "Touchscreen user interface computer: next branch left off ramp";
CM_ SG_ 568 UI_nextBranchRightOffRamp "Touchscreen user interface computer: next branch right off ramp";
CM_ SG_ 568 UI_rejectLeftLane "Touchscreen user interface computer: reject left lane";
CM_ SG_ 568 UI_rejectRightLane "Touchscreen user interface computer: reject right lane";
CM_ SG_ 568 UI_rejectHPP "Touchscreen user interface computer: reject HPP";
CM_ SG_ 568 UI_rejectNav "Touchscreen user interface computer: reject nav";
CM_ SG_ 568 UI_rejectLeftFreeSpace "Touchscreen user interface computer: reject left free space";
CM_ SG_ 568 UI_rejectRightFreeSpace "Touchscreen user interface computer: reject right free space";
CM_ SG_ 568 UI_rejectAutosteer "Touchscreen user interface computer: reject autosteer";
CM_ SG_ 568 UI_rejectHandsOn "Touchscreen user interface computer: reject hands on";
CM_ SG_ 568 UI_acceptBottsDots "Touchscreen user interface computer: accept botts dots";
CM_ SG_ 568 UI_autosteerRestricted "Autopilot map is autostreer restricted.";
CM_ SG_ 568 UI_pmmEnabled "Touchscreen user interface computer: pmm enabled";
CM_ SG_ 568 UI_scaEnabled "Touchscreen user interface computer: sca enabled";
CM_ SG_ 568 UI_mapDataCounter "Touchscreen user interface computer: map data counter";
CM_ SG_ 568 UI_mapDataChecksum "Touchscreen user interface computer: map data checksum";
CM_ BO_ 536 "Touchscreen user interface computer message: driver assist road sign; forwarded onto this bus by the gateway; frame length from the layout, not yet observed on a vehicle bus";
CM_ SG_ 536 UI_roadSign "Touchscreen user interface computer: road sign; raw 255 = signal not available (SNA)";
CM_ SG_ 536 UI_splineLocConfidence "Touchscreen user interface computer: spline loc confidence; raw 0 = signal not available (SNA)";
CM_ SG_ 536 UI_splineID "Touchscreen user interface computer: spline ID";
CM_ SG_ 536 UI_roadSignCounter "Touchscreen user interface computer: road sign counter";
CM_ SG_ 536 UI_roadSignChecksum "Touchscreen user interface computer: road sign checksum";
CM_ SG_ 536 UI_dummyData "Touchscreen user interface computer: dummy data";
CM_ SG_ 536 UI_stopSignStopLineDist "Touchscreen user interface computer: stop sign stop line dist; raw 1023 = signal not available (SNA)";
CM_ SG_ 536 UI_stopSignStopLineConf "Touchscreen user interface computer: stop sign stop line conf; raw 0 = signal not available (SNA)";
CM_ SG_ 536 UI_trafficLightStopLineDist "Touchscreen user interface computer: traffic light stop line dist; raw 1023 = signal not available (SNA)";
CM_ SG_ 536 UI_trafficLightStopLineConf "Touchscreen user interface computer: traffic light stop line conf; raw 0 = signal not available (SNA)";
CM_ SG_ 536 UI_baseMapSpeedLimitMPS "Touchscreen user interface computer: base map speed limit MPS; raw 255 = signal not available (SNA)";
CM_ SG_ 536 UI_bottomQrtlFleetSpeedMPS "Touchscreen user interface computer: bottom qrtl fleet speed MPS; raw 255 = signal not available (SNA)";
CM_ SG_ 536 UI_topQrtlFleetSpeedMPS "Touchscreen user interface computer: top qrtl fleet speed MPS; raw 255 = signal not available (SNA)";
CM_ SG_ 536 UI_meanFleetSplineSpeedMPS "Touchscreen user interface computer: mean fleet spline speed MPS; raw 255 = signal not available (SNA)";
CM_ SG_ 536 UI_medianFleetSpeedMPS "Touchscreen user interface computer: median fleet speed MPS; raw 255 = signal not available (SNA)";
CM_ SG_ 536 UI_meanFleetSplineAccelMPS2 "Touchscreen user interface computer: mean fleet spline accel MPS2; raw 255 = signal not available (SNA)";
CM_ SG_ 536 UI_rampType "Touchscreen user interface computer: ramp type; raw 0 = signal not available (SNA)";
CM_ SG_ 536 UI_valhallaRamp "Touchscreen user interface computer: valhalla ramp; raw 0 = signal not available (SNA)";
CM_ SG_ 536 UI_overrideACMFleetSpeed "Touchscreen user interface computer: override ACM fleet speed";
CM_ SG_ 536 UI_currSplineIdFull "Touchscreen user interface computer: curr spline id full; raw 0 = signal not available (SNA)";
CM_ BO_ 1971 "Touchscreen user interface computer message: dynamic triggers campaign fired; forwarded onto this bus by the gateway; frame length from the layout, not yet observed on a vehicle bus";
CM_ SG_ 1971 UI_campaignFired "Touchscreen user interface computer: campaign fired";
CM_ BO_ 760 "Touchscreen user interface computer message: gps vehicle speed; forwarded onto this bus by the gateway; frame length from the layout, not yet observed on a vehicle bus";
CM_ SG_ 760 UI_gpsHDOP "Touchscreen user interface computer: gps HDOP";
CM_ SG_ 760 UI_gpsVehicleHeading "Touchscreen user interface computer: gps vehicle heading";
CM_ SG_ 760 UI_gpsVehicleSpeed "Touchscreen user interface computer: gps vehicle speed";
CM_ SG_ 760 UI_userSpeedOffset "Touchscreen user interface computer: user speed offset";
CM_ SG_ 760 UI_mapSpeedLimitUnits "Autopilot map speed limit units.";
CM_ SG_ 760 UI_userSpeedOffsetUnits "Touchscreen user interface computer: user speed offset units";
CM_ SG_ 760 UI_mppSpeedLimit "Autopilot map speed limit";
CM_ SG_ 760 UI_gpsNmeaMIA "GPS NMEA data MIA";
CM_ SG_ 760 UI_gpsAntennaDisconnected "GPS antenna state";
CM_ SG_ 760 UI_conditionalLimitActive "Conditional speed limit condition is currently active";
CM_ SG_ 760 UI_conditionalSpeedLimit "Conditional speed limit value; raw 31 = signal not available (SNA)";
CM_ BO_ 985 "Touchscreen user interface computer message: location offset; forwarded onto this bus by the gateway; frame length from the layout, not yet observed on a vehicle bus";
CM_ SG_ 985 UI_latitudeOffset "Touchscreen user interface computer: latitude offset";
CM_ SG_ 985 UI_longitudeOffset "Touchscreen user interface computer: longitude offset";
CM_ BO_ 777 "Touchscreen user interface computer message: location status; forwarded onto this bus by the gateway; frame length from the layout, not yet observed on a vehicle bus";
CM_ SG_ 777 UI_latitude "Touchscreen user interface computer: latitude";
CM_ SG_ 777 UI_longitude "Touchscreen user interface computer: longitude";
CM_ SG_ 777 UI_gpsAccuracy "Touchscreen user interface computer: gps accuracy; raw 127 = signal not available (SNA)";
CM_ BO_ 1011 "Touchscreen user interface computer message: odo; forwarded onto this bus by the gateway; frame length from the layout, not yet observed on a vehicle bus";
CM_ SG_ 1011 UI_odometer "Odometer; raw 16777215 = signal not available (SNA)";
CM_ BO_ 987 "Touchscreen user interface computer message: phone location status; forwarded onto this bus by the gateway; frame length from the layout, not yet observed on a vehicle bus";
CM_ SG_ 987 UI_phoneLatitude "Touchscreen user interface computer: phone latitude";
CM_ SG_ 987 UI_phoneLongitude "Touchscreen user interface computer: phone longitude";
CM_ SG_ 987 UI_phoneGpsAccuracy "Touchscreen user interface computer: phone gps accuracy; raw 127 = signal not available (SNA)";
CM_ BO_ 698 "Touchscreen user interface computer message: radar map data; forwarded onto this bus by the gateway; frame length from the layout, not yet observed on a vehicle bus";
CM_ SG_ 698 UI_radarTargetDx "Touchscreen user interface computer: radar target dx";
CM_ SG_ 698 UI_radarTargetDxEnd "Touchscreen user interface computer: radar target dx end";
CM_ SG_ 698 UI_radarTargetTrustMap "Touchscreen user interface computer: radar target trust map";
CM_ SG_ 698 UI_radarEnableBraking "Touchscreen user interface computer: radar enable braking";
CM_ SG_ 698 UI_radarMapDataCounter "Touchscreen user interface computer: radar map data counter";
CM_ SG_ 698 UI_radarMapDataChecksum "Touchscreen user interface computer: radar map data checksum";
CM_ BO_ 632 "Touchscreen user interface computer message: road curvature; forwarded onto this bus by the gateway; frame length from the layout, not yet observed on a vehicle bus";
CM_ SG_ 632 UI_roadCurvC0 "Touchscreen user interface computer: road curv C0";
CM_ SG_ 632 UI_roadCurvC1 "Touchscreen user interface computer: road curv C1";
CM_ SG_ 632 UI_roadCurvC2 "Touchscreen user interface computer: road curv C2";
CM_ SG_ 632 UI_roadCurvC3 "Touchscreen user interface computer: road curv C3";
CM_ SG_ 632 UI_roadCurvRange "Touchscreen user interface computer: road curv range";
CM_ SG_ 632 UI_roadCurvHealth "Touchscreen user interface computer: road curv health";
CM_ SG_ 632 UI_roadCurvChecksum "Touchscreen user interface computer: road curv checksum";
CM_ BO_ 723 "Touchscreen user interface computer message: solar data; forwarded onto this bus by the gateway; frame length from the layout, not yet observed on a vehicle bus";
CM_ SG_ 723 UI_solarAzimuthAngle "Touchscreen user interface computer: solar azimuth angle; raw 32768 = signal not available (SNA)";
CM_ SG_ 723 UI_solarAzimuthAngleCarRef "Touchscreen user interface computer: solar azimuth angle car ref; raw 255 = signal not available (SNA)";
CM_ SG_ 723 UI_isSunUp "is sun up; raw 3 = signal not available (SNA)";
CM_ SG_ 723 UI_solarElevationAngle "Solar Elevation Angle; raw 127 = signal not available (SNA)";
CM_ SG_ 723 UI_screenPCBTemperature "Temperature of display PCB";
CM_ SG_ 723 UI_minsToSunset "time until to sunset";
CM_ SG_ 723 UI_minsToSunrise "time until to sunrise";
CM_ BO_ 851 "Touchscreen user interface computer message: status; forwarded onto this bus by the gateway; frame length from the layout, not yet observed on a vehicle bus";
CM_ SG_ 851 UI_touchActive "No touchscreen errors";
CM_ SG_ 851 UI_audioActive "Audio system is ready.";
CM_ SG_ 851 UI_bluetoothActive "Touchscreen user interface computer: bluetooth active";
CM_ SG_ 851 UI_cellActive "Cell is powered";
CM_ SG_ 851 UI_displayReady "UI is ready (GUI_allReady) and display is ok (GUI_displayHardwareOK)";
CM_ SG_ 851 UI_displayOn "UI display on/off status";
CM_ SG_ 851 UI_wifiActive "WiFi active.";
CM_ SG_ 851 UI_wifiConnected "WiFi Connected.";
CM_ SG_ 851 UI_systemActive "Touchscreen user interface computer: system active";
CM_ SG_ 851 UI_readyForDrive "Ready for drive (UI ready or self park request)";
CM_ SG_ 851 UI_cellConnected "Detects if the cell is connected to a network.";
CM_ SG_ 851 UI_vpnActive "VPN connected.";
CM_ SG_ 851 UI_autopilotTrial "Touchscreen user interface computer: autopilot trial";
CM_ SG_ 851 UI_factoryReset "UI request for factory reset; raw 0 = signal not available (SNA)";
CM_ SG_ 851 UI_gpsActive "GPS has valid fix";
CM_ SG_ 851 UI_screenshotActive "Touchscreen user interface computer: screenshot active";
CM_ SG_ 851 UI_radioActive "Touchscreen user interface computer: radio active";
CM_ SG_ 851 UI_cellNetworkTechnology "Describes the type of cellular network to which the car computer is connected: GPRS_2G(114Kbps) < EGDE_2G(368Kbps) < 3G(3Mbps) < HSDPA_3G(14Mbps) < HSPAplus_4Gg(168Mbps) < 4G_LTE(299Mbps); raw 15 = signal not available (SNA)";
CM_ SG_ 851 UI_cellReceiverPower "Touchscreen user interface computer: cell receiver power";
CM_ SG_ 851 UI_falseTouchCounter "Count false touches after display is off.";
CM_ SG_ 851 UI_developmentCar "Touchscreen user interface computer: development car";
CM_ SG_ 851 UI_cameraActive "Touchscreen user interface computer: camera active";
CM_ SG_ 851 UI_cellSignalBars "Number of cellular signal bars displayed on the UI, derived from cellSignalStrength; raw 7 = signal not available (SNA)";
CM_ SG_ 851 UI_trailerModeTelltale "Color of the trailer mode telltale";
CM_ SG_ 851 UI_pcbTemperature "PCB digital temp sensor reading in DegC";
CM_ SG_ 851 UI_cpuTemperature "Apollo Lake SOC temperature in DegC";
CM_ BO_ 988 "Touchscreen user interface computer message: summon goal; forwarded onto this bus by the gateway; frame length from the layout, not yet observed on a vehicle bus";
CM_ SG_ 988 UI_goalLatitude "Touchscreen user interface computer: goal latitude";
CM_ SG_ 988 UI_goalLongitude "Touchscreen user interface computer: goal longitude";
CM_ SG_ 988 UI_goalOrientation "Touchscreen user interface computer: goal orientation";
CM_ BO_ 1064 "Touchscreen user interface computer message: telemetry control; forwarded onto this bus by the gateway; frame length from the layout, not yet observed on a vehicle bus";
CM_ SG_ 1064 UI_TCR_enable "Touchscreen user interface computer: TCR enable";
CM_ SG_ 1064 UI_TCR_moveStateStanding "Touchscreen user interface computer: TCR move state standing";
CM_ SG_ 1064 UI_TCR_moveStateStopped "Touchscreen user interface computer: TCR move state stopped";
CM_ SG_ 1064 UI_TCR_moveStateMoving "Touchscreen user interface computer: TCR move state moving";
CM_ SG_ 1064 UI_TCR_moveStateIndeterm "Touchscreen user interface computer: TCR move state indeterm";
CM_ SG_ 1064 UI_TCR_classConstElem "Touchscreen user interface computer: TCR class const elem";
CM_ SG_ 1064 UI_TCR_classMovingPed "Touchscreen user interface computer: TCR class moving ped";
CM_ SG_ 1064 UI_TCR_classMovingTwoWheel "Touchscreen user interface computer: TCR class moving two wheel";
CM_ SG_ 1064 UI_TCR_classMovingFourWheel "Touchscreen user interface computer: TCR class moving four wheel";
CM_ SG_ 1064 UI_TCR_classUnknown "Touchscreen user interface computer: TCR class unknown";
CM_ SG_ 1064 UI_TCR_downSampleFactor "Touchscreen user interface computer: TCR down sample factor";
CM_ SG_ 1064 UI_TCR_wExist "Touchscreen user interface computer: TCR w exist";
CM_ SG_ 1064 UI_TCR_vehSpeed "Touchscreen user interface computer: TCR veh speed";
CM_ SG_ 1064 UI_TCR_minRCS "Touchscreen user interface computer: TCR min RCS";
CM_ SG_ 1064 UI_TCR_maxDy "Touchscreen user interface computer: TCR max dy";
CM_ SG_ 1064 UI_TCR_maxObjects "Touchscreen user interface computer: TCR max objects";
CM_ SG_ 1064 UI_TCR_maxRoadClass "Touchscreen user interface computer: TCR max road class";
CM_ BO_ 856 "Touchscreen user interface computer message: tpms mode; forwarded onto this bus by the gateway; frame length from the layout, not yet observed on a vehicle bus";
CM_ SG_ 856 UI_TPMSMode "Touchscreen user interface computer: TPMS mode";
CM_ SG_ 856 UI_TPMSLearnIDMode "Touchscreen user interface computer: TPMS learn ID mode";
CM_ SG_ 856 UI_sizeOfWheelSelect "Touchscreen user interface computer: size of wheel select";
CM_ SG_ 856 UI_sizeOfReqCANAutoLearn "Touchscreen user interface computer: size of req CAN auto learn";
CM_ BO_ 1827 "Touchscreen user interface computer message: uss thresholds x; forwarded onto this bus by the gateway; frame length from the layout, not yet observed on a vehicle bus";
CM_ SG_ 1827 UI_ussSensorIdX "Touchscreen user interface computer: uss sensor id x";
CM_ SG_ 1827 UI_ussThresholdX0 "Touchscreen user interface computer: uss threshold X0";
CM_ SG_ 1827 UI_ussThresholdX1 "Touchscreen user interface computer: uss threshold X1";
CM_ SG_ 1827 UI_ussThresholdX2 "Touchscreen user interface computer: uss threshold X2";
CM_ SG_ 1827 UI_ussThresholdX3 "Touchscreen user interface computer: uss threshold X3";
CM_ SG_ 1827 UI_ussThresholdX4 "Touchscreen user interface computer: uss threshold X4";
CM_ SG_ 1827 UI_ussThresholdX5 "Touchscreen user interface computer: uss threshold X5";
CM_ SG_ 1827 UI_ussThresholdX6 "Touchscreen user interface computer: uss threshold X6";
CM_ SG_ 1827 UI_ussThresholdX7 "Touchscreen user interface computer: uss threshold X7";
CM_ SG_ 1827 UI_ussThresholdX8 "Touchscreen user interface computer: uss threshold X8";
CM_ SG_ 1827 UI_ussThresholdX9 "Touchscreen user interface computer: uss threshold X9";
CM_ SG_ 1827 UI_ussThresholdX10 "Touchscreen user interface computer: uss threshold X10";
CM_ SG_ 1827 UI_ussThresholdX11 "Touchscreen user interface computer: uss threshold X11";
CM_ SG_ 1827 UI_ussThresholdXControl "Touchscreen user interface computer: uss threshold x control";
CM_ BO_ 1829 "Touchscreen user interface computer message: uss thresholds y; forwarded onto this bus by the gateway; frame length from the layout, not yet observed on a vehicle bus";
CM_ SG_ 1829 UI_ussSensorIdY "Touchscreen user interface computer: uss sensor id y";
CM_ SG_ 1829 UI_ussThresholdY0 "Touchscreen user interface computer: uss threshold Y0";
CM_ SG_ 1829 UI_ussThresholdY1 "Touchscreen user interface computer: uss threshold Y1";
CM_ SG_ 1829 UI_ussThresholdY2 "Touchscreen user interface computer: uss threshold Y2";
CM_ SG_ 1829 UI_ussThresholdY3 "Touchscreen user interface computer: uss threshold Y3";
CM_ SG_ 1829 UI_ussThresholdY4 "Touchscreen user interface computer: uss threshold Y4";
CM_ SG_ 1829 UI_ussThresholdY5 "Touchscreen user interface computer: uss threshold Y5";
CM_ SG_ 1829 UI_ussThresholdY6 "Touchscreen user interface computer: uss threshold Y6";
CM_ SG_ 1829 UI_ussThresholdY7 "Touchscreen user interface computer: uss threshold Y7";
CM_ SG_ 1829 UI_ussThresholdY8 "Touchscreen user interface computer: uss threshold Y8";
CM_ SG_ 1829 UI_ussThresholdY9 "Touchscreen user interface computer: uss threshold Y9";
CM_ SG_ 1829 UI_ussThresholdY10 "Touchscreen user interface computer: uss threshold Y10";
CM_ SG_ 1829 UI_ussThresholdY11 "Touchscreen user interface computer: uss threshold Y11";
CM_ SG_ 1829 UI_ussThresholdYControl "Touchscreen user interface computer: uss threshold y control";
CM_ BO_ 954 "USM ECU message: alert matrix; frame length from the layout, not yet observed on a vehicle bus";
CM_ SG_ 954 USM_matrixIndex "USM ECU: matrix index";
CM_ SG_ 954 USM_a001_WatchdogReset "USM ECU: a001 watchdog reset";
CM_ SG_ 954 USM_a002_PowerLossReset "USM ECU: a002 power loss reset";
CM_ SG_ 954 USM_a003_SWAssertion "USM ECU: a003 SW assertion";
CM_ SG_ 954 USM_a005_CANTXError "USM ECU: a005 CANTX error";
CM_ SG_ 954 USM_a006_CANTX_cyclicError "USM ECU: a006 CANTX cyclic error";
CM_ SG_ 954 USM_a012_CPUReset "USM ECU: a012 CPU reset";
CM_ SG_ 954 USM_a013_AlertManagerFault "USM ECU: a013 alert manager fault";
CM_ SG_ 954 USM_a015_NVMMError "USM ECU: a015 NVMM error";
CM_ SG_ 954 USM_a016_NVMMRecordError "USM ECU: a016 NVMM record error";
CM_ SG_ 954 USM_a021_TaskSchedulerError "USM ECU: a021 task scheduler error";
CM_ SG_ 954 USM_a022_TaskInitError "USM ECU: a022 task init error";
CM_ SG_ 954 USM_a029_CoreDump "USM ECU: a029 core dump";
CM_ SG_ 954 USM_a030_ECULogUploadRequest "USM ECU: a030 ECU log upload request";
CM_ SG_ 954 USM_a031_UDSActive "USM ECU: a031 UDS active";
CM_ SG_ 954 USM_a041_HighCPULoad "USM ECU: a041 high CPU load";
CM_ SG_ 954 USM_a042_HighStackUsage "USM ECU: a042 high stack usage";
CM_ SG_ 954 USM_a043_Task1msError "USM ECU: a043 task1ms error";
CM_ SG_ 954 USM_a044_Task10msError "USM ECU: a044 task10ms error";
CM_ SG_ 954 USM_a045_Task100msError "USM ECU: a045 task100ms error";
CM_ SG_ 954 USM_a046_Task1000msError "USM ECU: a046 task1000ms error";
CM_ SG_ 954 USM_a057_HVP_MIA "USM ECU: a057 HVP MIA";
CM_ SG_ 954 USM_a058_inputRHighSyncDebug "USM ECU: a058 input r high sync debug";
CM_ SG_ 954 USM_a059_inputResistanceHigh "USM ECU: a059 input resistance high";
CM_ SG_ 954 USM_a060_engineeringBuild "USM ECU: a060 engineering build";
CM_ SG_ 954 USM_a061_XCPConnected "USM ECU: a061 XCP connected";
CM_ SG_ 954 USM_a062_XCPWasConnected "USM ECU: a062 XCP was connected";
CM_ SG_ 954 USM_a063_SwitchFault "USM ECU: a063 switch fault";
CM_ SG_ 954 USM_a064_busSleepReqTimeout "USM ECU: a064 bus sleep req timeout";
CM_ SG_ 954 USM_a082_VCRIGHT_IPC_MIA "USM ECU: a082 VCRIGHT IPC MIA";
CM_ SG_ 954 USM_a083_VCLEFT_IPC_MIA "USM ECU: a083 VCLEFT IPC MIA";
CM_ SG_ 954 USM_a084_TPMS_MIA "USM ECU: a084 TPMS MIA";
CM_ SG_ 954 USM_a085_CCCM_MIA "USM ECU: a085 CCCM MIA";
CM_ SG_ 954 USM_a086_VCBATT_MIA "USM ECU: a086 VCBATT MIA";
CM_ SG_ 954 USM_a087_DIREL_MIA "USM ECU: a087 DIREL MIA";
CM_ SG_ 954 USM_a088_DIRER_MIA "USM ECU: a088 DIRER MIA";
CM_ SG_ 954 USM_a089_IBST_MIA "USM ECU: a089 IBST MIA";
CM_ SG_ 954 USM_a090_APS_MIA "USM ECU: a090 APS MIA";
CM_ SG_ 954 USM_a091_CMPD_MIA "USM ECU: a091 CMPD MIA";
CM_ SG_ 954 USM_a092_VCSEATD_MIA "USM ECU: a092 VCSEATD MIA";
CM_ SG_ 954 USM_a093_VCSEATP_MIA "USM ECU: a093 VCSEATP MIA";
CM_ SG_ 954 USM_a094_EPAS3P_MIA "USM ECU: a094 EPAS3 p MIA";
CM_ SG_ 954 USM_a095_CHG_MIA "USM ECU: a095 CHG MIA";
CM_ SG_ 954 USM_a096_OCS1P_MIA "USM ECU: a096 OCS1 p MIA";
CM_ SG_ 954 USM_a097_CMP_MIA "USM ECU: a097 CMP MIA";
CM_ SG_ 954 USM_a098_DIR_MIA "USM ECU: a098 DIR MIA";
CM_ SG_ 954 USM_a099_PARK_MIA "USM ECU: a099 PARK MIA";
CM_ SG_ 954 USM_a100_CANbus_MIA "USM ECU: a100 CA nbus MIA";
CM_ SG_ 954 USM_a101_PM_MIA "USM ECU: a101 PM MIA";
CM_ SG_ 954 USM_a102_PTC_MIA "USM ECU: a102 PTC MIA";
CM_ SG_ 954 USM_a103_CP_MIA "USM ECU: a103 CP MIA";
CM_ SG_ 954 USM_a104_DAS_MIA "USM ECU: a104 DAS MIA";
CM_ SG_ 954 USM_a105_TAS_MIA "USM ECU: a105 TAS MIA";
CM_ SG_ 954 USM_a106_PCS_MIA "USM ECU: a106 PCS MIA";
CM_ SG_ 954 USM_a107_BMS_MIA "USM ECU: a107 BMS MIA";
CM_ SG_ 954 USM_a108_DIF_MIA "USM ECU: a108 DIF MIA";
CM_ SG_ 954 USM_a109_RCM_MIA "USM ECU: a109 RCM MIA";
CM_ SG_ 954 USM_a110_GTW_MIA "USM ECU: a110 GTW MIA";
CM_ SG_ 954 USM_a111_EPBR_MIA "USM ECU: a111 EPBR MIA";
CM_ SG_ 954 USM_a112_EPBL_MIA "USM ECU: a112 EPBL MIA";
CM_ SG_ 954 USM_a113_UI_MIA "USM ECU: a113 UI MIA";
CM_ SG_ 954 USM_a114_ESP_MIA "USM ECU: a114 ESP MIA";
CM_ SG_ 954 USM_a115_VCSEC_MIA "USM ECU: a115 VCSEC MIA";
CM_ SG_ 954 USM_a116_VCRIGHT_MIA "USM ECU: a116 VCRIGHT MIA";
CM_ SG_ 954 USM_a117_VCLEFT_MIA "USM ECU: a117 VCLEFT MIA";
CM_ SG_ 954 USM_a118_VCFRONT_MIA "USM ECU: a118 VCFRONT MIA";
CM_ SG_ 954 USM_a119_SCCM_MIA "USM ECU: a119 SCCM MIA";
CM_ SG_ 954 USM_a120_DI_DRIVE_MIA "USM ECU: a120 DI DRIVE MIA";
CM_ SG_ 954 USM_a131_s1ComError "USM ECU: a131 s1 com error";
CM_ SG_ 954 USM_a132_s2ComError "USM ECU: a132 s2 com error";
CM_ SG_ 954 USM_a133_s3ComError "USM ECU: a133 s3 com error";
CM_ SG_ 954 USM_a134_s4ComError "USM ECU: a134 s4 com error";
CM_ SG_ 954 USM_a135_s5ComError "USM ECU: a135 s5 com error";
CM_ SG_ 954 USM_a136_s6ComError "USM ECU: a136 s6 com error";
CM_ SG_ 954 USM_a137_s7ComError "USM ECU: a137 s7 com error";
CM_ SG_ 954 USM_a138_s8ComError "USM ECU: a138 s8 com error";
CM_ SG_ 954 USM_a139_s9ComError "USM ECU: a139 s9 com error";
CM_ SG_ 954 USM_a140_s10ComError "USM ECU: a140 s10 com error";
CM_ SG_ 954 USM_a141_s11ComError "USM ECU: a141 s11 com error";
CM_ SG_ 954 USM_a142_s12ComError "USM ECU: a142 s12 com error";
CM_ SG_ 954 USM_a143_s1HwError "USM ECU: a143 s1 hw error";
CM_ SG_ 954 USM_a144_s2HwError "USM ECU: a144 s2 hw error";
CM_ SG_ 954 USM_a145_s3HwError "USM ECU: a145 s3 hw error";
CM_ SG_ 954 USM_a146_s4HwError "USM ECU: a146 s4 hw error";
CM_ SG_ 954 USM_a147_s5HwError "USM ECU: a147 s5 hw error";
CM_ SG_ 954 USM_a148_s6HwError "USM ECU: a148 s6 hw error";
CM_ SG_ 954 USM_a149_s7HwError "USM ECU: a149 s7 hw error";
CM_ SG_ 954 USM_a150_s8HwError "USM ECU: a150 s8 hw error";
CM_ SG_ 954 USM_a151_s9HwError "USM ECU: a151 s9 hw error";
CM_ SG_ 954 USM_a152_s10HwError "USM ECU: a152 s10 hw error";
CM_ SG_ 954 USM_a153_s11HwError "USM ECU: a153 s11 hw error";
CM_ SG_ 954 USM_a154_s12HwError "USM ECU: a154 s12 hw error";
CM_ SG_ 954 USM_a155_s1OverTemp "USM ECU: a155 s1 over temp";
CM_ SG_ 954 USM_a156_s2OverTemp "USM ECU: a156 s2 over temp";
CM_ SG_ 954 USM_a157_s3OverTemp "USM ECU: a157 s3 over temp";
CM_ SG_ 954 USM_a158_s4OverTemp "USM ECU: a158 s4 over temp";
CM_ SG_ 954 USM_a159_s5OverTemp "USM ECU: a159 s5 over temp";
CM_ SG_ 954 USM_a160_s6OverTemp "USM ECU: a160 s6 over temp";
CM_ SG_ 954 USM_a161_s7OverTemp "USM ECU: a161 s7 over temp";
CM_ SG_ 954 USM_a162_s8OverTemp "USM ECU: a162 s8 over temp";
CM_ SG_ 954 USM_a163_s9OverTemp "USM ECU: a163 s9 over temp";
CM_ SG_ 954 USM_a164_s10OverTemp "USM ECU: a164 s10 over temp";
CM_ SG_ 954 USM_a165_s11OverTemp "USM ECU: a165 s11 over temp";
CM_ SG_ 954 USM_a166_s12OverTemp "USM ECU: a166 s12 over temp";
CM_ SG_ 954 USM_a177_s1Blocked "USM ECU: a177 s1 blocked";
CM_ SG_ 954 USM_a178_s2Blocked "USM ECU: a178 s2 blocked";
CM_ SG_ 954 USM_a179_s3Blocked "USM ECU: a179 s3 blocked";
CM_ SG_ 954 USM_a180_s4Blocked "USM ECU: a180 s4 blocked";
CM_ SG_ 954 USM_a181_s5Blocked "USM ECU: a181 s5 blocked";
CM_ SG_ 954 USM_a182_s6Blocked "USM ECU: a182 s6 blocked";
CM_ SG_ 954 USM_a183_s7Blocked "USM ECU: a183 s7 blocked";
CM_ SG_ 954 USM_a184_s8Blocked "USM ECU: a184 s8 blocked";
CM_ SG_ 954 USM_a185_s9Blocked "USM ECU: a185 s9 blocked";
CM_ SG_ 954 USM_a186_s10Blocked "USM ECU: a186 s10 blocked";
CM_ SG_ 954 USM_a187_s11Blocked "USM ECU: a187 s11 blocked";
CM_ SG_ 954 USM_a188_s12Blocked "USM ECU: a188 s12 blocked";
CM_ SG_ 954 USM_a189_s1Disconnected "USM ECU: a189 s1 disconnected";
CM_ SG_ 954 USM_a190_s2Disconnected "USM ECU: a190 s2 disconnected";
CM_ SG_ 954 USM_a191_s3Disconnected "USM ECU: a191 s3 disconnected";
CM_ SG_ 954 USM_a192_s4Disconnected "USM ECU: a192 s4 disconnected";
CM_ SG_ 954 USM_a193_s5Disconnected "USM ECU: a193 s5 disconnected";
CM_ SG_ 954 USM_a194_s6Disconnected "USM ECU: a194 s6 disconnected";
CM_ SG_ 954 USM_a195_s7Disconnected "USM ECU: a195 s7 disconnected";
CM_ SG_ 954 USM_a196_s8Disconnected "USM ECU: a196 s8 disconnected";
CM_ SG_ 954 USM_a197_s9Disconnected "USM ECU: a197 s9 disconnected";
CM_ SG_ 954 USM_a198_s10Disconnected "USM ECU: a198 s10 disconnected";
CM_ SG_ 954 USM_a199_s11Disconnected "USM ECU: a199 s11 disconnected";
CM_ SG_ 954 USM_a200_s12Disconnected "USM ECU: a200 s12 disconnected";
CM_ SG_ 954 USM_a201_e52142Fault "USM ECU: a201 e52142 fault";
CM_ SG_ 954 USM_a202_e52417Fault "USM ECU: a202 e52417 fault";
CM_ SG_ 954 USM_a203_s1NearFieldDetected "USM ECU: a203 s1 near field detected";
CM_ SG_ 954 USM_a204_s2NearFieldDetected "USM ECU: a204 s2 near field detected";
CM_ SG_ 954 USM_a205_s3NearFieldDetected "USM ECU: a205 s3 near field detected";
CM_ SG_ 954 USM_a206_s4NearFieldDetected "USM ECU: a206 s4 near field detected";
CM_ SG_ 954 USM_a207_s5NearFieldDetected "USM ECU: a207 s5 near field detected";
CM_ SG_ 954 USM_a208_s6NearFieldDetected "USM ECU: a208 s6 near field detected";
CM_ SG_ 954 USM_a209_s7NearFieldDetected "USM ECU: a209 s7 near field detected";
CM_ SG_ 954 USM_a210_s8NearFieldDetected "USM ECU: a210 s8 near field detected";
CM_ SG_ 954 USM_a211_s9NearFieldDetected "USM ECU: a211 s9 near field detected";
CM_ SG_ 954 USM_a212_s10NearFieldDetected "USM ECU: a212 s10 near field detected";
CM_ SG_ 954 USM_a213_s11NearFieldDetected "USM ECU: a213 s11 near field detected";
CM_ SG_ 954 USM_a214_s12NearFieldDetected "USM ECU: a214 s12 near field detected";
CM_ SG_ 954 USM_a215_s1DebugEepromInvalid "USM ECU: a215 s1 debug eeprom invalid";
CM_ SG_ 954 USM_a216_s2DebugEepromInvalid "USM ECU: a216 s2 debug eeprom invalid";
CM_ SG_ 954 USM_a217_s3DebugEepromInvalid "USM ECU: a217 s3 debug eeprom invalid";
CM_ SG_ 954 USM_a218_s4DebugEepromInvalid "USM ECU: a218 s4 debug eeprom invalid";
CM_ SG_ 954 USM_a219_s5DebugEepromInvalid "USM ECU: a219 s5 debug eeprom invalid";
CM_ SG_ 954 USM_a220_s6DebugEepromInvalid "USM ECU: a220 s6 debug eeprom invalid";
CM_ SG_ 954 USM_a221_s7DebugEepromInvalid "USM ECU: a221 s7 debug eeprom invalid";
CM_ SG_ 954 USM_a222_s8DebugEepromInvalid "USM ECU: a222 s8 debug eeprom invalid";
CM_ SG_ 954 USM_a223_s9DebugEepromInvalid "USM ECU: a223 s9 debug eeprom invalid";
CM_ SG_ 954 USM_a224_s10DebugEepromInvalid "USM ECU: a224 s10 debug eeprom invalid";
CM_ SG_ 954 USM_a225_s11DebugEepromInvalid "USM ECU: a225 s11 debug eeprom invalid";
CM_ SG_ 954 USM_a226_s12DebugEepromInvalid "USM ECU: a226 s12 debug eeprom invalid";
CM_ SG_ 954 USM_a227_s1InitError "USM ECU: a227 s1 init error";
CM_ SG_ 954 USM_a228_s2InitError "USM ECU: a228 s2 init error";
CM_ SG_ 954 USM_a229_s3InitError "USM ECU: a229 s3 init error";
CM_ SG_ 954 USM_a230_s4InitError "USM ECU: a230 s4 init error";
CM_ SG_ 954 USM_a231_s5InitError "USM ECU: a231 s5 init error";
CM_ SG_ 954 USM_a232_s6InitError "USM ECU: a232 s6 init error";
CM_ SG_ 954 USM_a233_s7InitError "USM ECU: a233 s7 init error";
CM_ SG_ 954 USM_a234_s8InitError "USM ECU: a234 s8 init error";
CM_ SG_ 954 USM_a235_s9InitError "USM ECU: a235 s9 init error";
CM_ SG_ 954 USM_a236_s10InitError "USM ECU: a236 s10 init error";
CM_ SG_ 954 USM_a237_s11InitError "USM ECU: a237 s11 init error";
CM_ SG_ 954 USM_a238_s12InitError "USM ECU: a238 s12 init error";
CM_ SG_ 954 USM_a240_s1HwComErrDiagnostics "USM ECU: a240 s1 hw com err diagnostics";
CM_ SG_ 954 USM_a241_s2HwComErrDiagnostics "USM ECU: a241 s2 hw com err diagnostics";
CM_ SG_ 954 USM_a242_s3HwComErrDiagnostics "USM ECU: a242 s3 hw com err diagnostics";
CM_ SG_ 954 USM_a243_s4HwComErrDiagnostics "USM ECU: a243 s4 hw com err diagnostics";
CM_ SG_ 954 USM_a244_s5HwComErrDiagnostics "USM ECU: a244 s5 hw com err diagnostics";
CM_ SG_ 954 USM_a245_s6HwComErrDiagnostics "USM ECU: a245 s6 hw com err diagnostics";
CM_ SG_ 954 USM_a246_s7HwComErrDiagnostics "USM ECU: a246 s7 hw com err diagnostics";
CM_ SG_ 954 USM_a247_s8HwComErrDiagnostics "USM ECU: a247 s8 hw com err diagnostics";
CM_ SG_ 954 USM_a248_s9HwComErrDiagnostics "USM ECU: a248 s9 hw com err diagnostics";
CM_ SG_ 954 USM_a249_s10HwComErrDiagnostics "USM ECU: a249 s10 hw com err diagnostics";
CM_ SG_ 954 USM_a250_s11HwComErrDiagnostics "USM ECU: a250 s11 hw com err diagnostics";
CM_ SG_ 954 USM_a251_s12HwComErrDiagnostics "USM ECU: a251 s12 hw com err diagnostics";
CM_ SG_ 954 USM_a252_anyComErrorSet "USM ECU: a252 any com error set";
CM_ SG_ 954 USM_a253_anyHwErrorSet "USM ECU: a253 any hw error set";
CM_ SG_ 954 USM_a254_frontSensorsOvercurrent "USM ECU: a254 front sensors overcurrent";
CM_ SG_ 954 USM_a255_rearSensorsOvercurrent "USM ECU: a255 rear sensors overcurrent";
CM_ BO_ 807 "USM ECU message: info; frame length from the layout, not yet observed on a vehicle bus";
CM_ SG_ 807 USM_infoIndex "USM ECU: info index";
CM_ SG_ 807 USM_infoBuildType "USM ECU: info build type";
CM_ SG_ 807 USM_infoBuildConfigId "USM ECU: info build config id";
CM_ SG_ 807 USM_infoHardwareId "USM ECU: info hardware id";
CM_ SG_ 807 USM_infoComponentId "USM ECU: info component id";
CM_ SG_ 807 USM_infoPcbaId "USM ECU: info pcba id";
CM_ SG_ 807 USM_infoAssemblyId "USM ECU: info assembly id; raw 255 = signal not available (SNA)";
CM_ SG_ 807 USM_infoUsageId "USM ECU: info usage id";
CM_ SG_ 807 USM_infoSubUsageId "USM ECU: info sub usage id";
CM_ SG_ 807 USM_infoAppCrc "USM ECU: info app crc";
BA_DEF_ BO_ "GenMsgCycleTime" INT 0 3600000;
BA_DEF_ BO_ "GenMsgSendType" ENUM "Cyclic","NotUsed","NotUsed","NotUsed","NotUsed","NotUsed","NotUsed","IfActive","NoMsgSendType","NotUsed";
BA_DEF_ BO_ "VFrameFormat" ENUM "StandardCAN","ExtendedCAN","reserved","J1939PG","reserved","reserved","reserved","reserved","reserved","reserved","reserved","reserved","reserved","reserved","StandardCAN_FD","ExtendedCAN_FD";
BA_DEF_ BO_ "CANFD_BRS" ENUM "0","1";
BA_DEF_ SG_ "GenSigSNA" STRING;
BA_DEF_ SG_ "SystemSignalLongSymbol" STRING;
BA_DEF_ SG_ "Confidence" ENUM "validated","plausible","layout-only","contradicted";
BA_DEF_DEF_ "GenMsgCycleTime" 0;
BA_DEF_DEF_ "GenMsgSendType" "NoMsgSendType";
BA_DEF_DEF_ "VFrameFormat" "StandardCAN";
BA_DEF_DEF_ "CANFD_BRS" "1";
BA_DEF_DEF_ "GenSigSNA" "";
BA_DEF_DEF_ "SystemSignalLongSymbol" "";
BA_DEF_DEF_ "Confidence" "layout-only";
BA_ "GenMsgCycleTime" BO_ 782 250;
BA_ "GenMsgSendType" BO_ 782 0;
BA_ "GenMsgCycleTime" BO_ 894 1000;
BA_ "GenMsgSendType" BO_ 894 0;
BA_ "GenMsgCycleTime" BO_ 1282 1000;
BA_ "GenMsgSendType" BO_ 1282 0;
BA_ "GenMsgCycleTime" BO_ 1329 1000;
BA_ "GenMsgSendType" BO_ 1329 0;
BA_ "GenMsgCycleTime" BO_ 1010 1000;
BA_ "GenMsgSendType" BO_ 1010 0;
BA_ "GenMsgCycleTime" BO_ 257 20;
BA_ "GenMsgSendType" BO_ 257 0;
BA_ "GenMsgCycleTime" BO_ 273 20;
BA_ "GenMsgSendType" BO_ 273 0;
BA_ "GenMsgCycleTime" BO_ 849 2000;
BA_ "GenMsgSendType" BO_ 849 0;
BA_ "GenMsgCycleTime" BO_ 529 100;
BA_ "GenMsgSendType" BO_ 529 0;
BA_ "GenMsgCycleTime" BO_ 831 10000;
BA_ "GenMsgSendType" BO_ 831 0;
BA_ "GenMsgCycleTime" BO_ 879 1000;
BA_ "GenMsgSendType" BO_ 879 0;
BA_ "GenMsgCycleTime" BO_ 799 1000;
BA_ "GenMsgSendType" BO_ 799 0;
BA_ "GenMsgCycleTime" BO_ 1519 1000;
BA_ "GenMsgSendType" BO_ 1519 0;
BA_ "GenMsgCycleTime" BO_ 659 500;
BA_ "GenMsgSendType" BO_ 659 0;
BA_ "GenMsgCycleTime" BO_ 664 500;
BA_ "GenMsgSendType" BO_ 664 0;
BA_ "GenMsgCycleTime" BO_ 679 500;
BA_ "GenMsgSendType" BO_ 679 0;
BA_ "GenMsgCycleTime" BO_ 1096 1000;
BA_ "GenMsgSendType" BO_ 1096 0;
BA_ "GenMsgCycleTime" BO_ 1016 1000;
BA_ "GenMsgSendType" BO_ 1016 0;
BA_ "GenMsgCycleTime" BO_ 568 500;
BA_ "GenMsgSendType" BO_ 568 0;
BA_ "GenMsgCycleTime" BO_ 536 500;
BA_ "GenMsgSendType" BO_ 536 0;
BA_ "GenMsgCycleTime" BO_ 1971 500;
BA_ "GenMsgSendType" BO_ 1971 0;
BA_ "GenMsgCycleTime" BO_ 760 1000;
BA_ "GenMsgSendType" BO_ 760 0;
BA_ "GenMsgCycleTime" BO_ 985 1000;
BA_ "GenMsgSendType" BO_ 985 0;
BA_ "GenMsgCycleTime" BO_ 777 1000;
BA_ "GenMsgSendType" BO_ 777 0;
BA_ "GenMsgCycleTime" BO_ 1011 1000;
BA_ "GenMsgSendType" BO_ 1011 0;
BA_ "GenMsgCycleTime" BO_ 987 1000;
BA_ "GenMsgSendType" BO_ 987 0;
BA_ "GenMsgCycleTime" BO_ 698 500;
BA_ "GenMsgSendType" BO_ 698 0;
BA_ "GenMsgCycleTime" BO_ 632 500;
BA_ "GenMsgSendType" BO_ 632 0;
BA_ "GenMsgCycleTime" BO_ 723 1000;
BA_ "GenMsgSendType" BO_ 723 0;
BA_ "GenMsgCycleTime" BO_ 851 1000;
BA_ "GenMsgSendType" BO_ 851 0;
BA_ "GenMsgCycleTime" BO_ 988 1000;
BA_ "GenMsgSendType" BO_ 988 0;
BA_ "GenMsgCycleTime" BO_ 1064 1000;
BA_ "GenMsgSendType" BO_ 1064 0;
BA_ "GenMsgCycleTime" BO_ 954 100;
BA_ "GenMsgSendType" BO_ 954 0;
BA_ "GenMsgCycleTime" BO_ 807 1000;
BA_ "GenMsgSendType" BO_ 807 0;
BA_ "Confidence" SG_ 782 PARK_frontSVACharID 0;
BA_ "Confidence" SG_ 782 PARK_pscRightCurbType 0;
BA_ "Confidence" SG_ 782 PARK_rearSVACharID 0;
BA_ "Confidence" SG_ 782 PARK_pscLeftCurbType 0;
BA_ "Confidence" SG_ 782 PARK_autoCalComplete 0;
BA_ "Confidence" SG_ 782 PARK_geometryType 0;
BA_ "Confidence" SG_ 782 PARK_tireFitment 0;
BA_ "GenSigSNA" SG_ 782 PARK_tireFitment "3";
BA_ "Confidence" SG_ 782 PARK_rackDetected 0;
BA_ "GenSigSNA" SG_ 782 PARK_rackDetected "3";
BA_ "Confidence" SG_ 782 PARK_sdiActive 0;
BA_ "Confidence" SG_ 782 PARK_sdiNoise 0;
BA_ "GenSigSNA" SG_ 782 PARK_sdiNoise "3";
BA_ "Confidence" SG_ 782 PARK_sdiBlindSpotRight 0;
BA_ "GenSigSNA" SG_ 782 PARK_sdiBlindSpotRight "3";
BA_ "Confidence" SG_ 782 PARK_sdiBlindSpotLeft 0;
BA_ "GenSigSNA" SG_ 782 PARK_sdiBlindSpotLeft "3";
BA_ "Confidence" SG_ 782 PARK_sensorType 0;
BA_ "GenSigSNA" SG_ 782 PARK_sensorType "3";
BA_ "Confidence" SG_ 782 PARK_status2Counter 0;
BA_ "Confidence" SG_ 782 PARK_status2Checksum 0;
BA_ "Confidence" SG_ 894 PARK_matrixIndex 1;
BA_ "Confidence" SG_ 1365 RADC_alertID 1;
BA_ "Confidence" SG_ 1365 RADC_alertState 1;
BA_ "Confidence" SG_ 1365 RADC_a002_ecuAdcErrType 1;
BA_ "Confidence" SG_ 1365 RADC_a008_interLockErrType 1;
BA_ "Confidence" SG_ 1365 RADC_a011_ecuMcemErrType 1;
BA_ "Confidence" SG_ 1365 RADC_a013_ecuWdgErrType 1;
BA_ "Confidence" SG_ 1365 RADC_a016_adcOverVoltType 1;
BA_ "Confidence" SG_ 1365 RADC_a016_adcVoltage 1;
BA_ "Confidence" SG_ 1365 RADC_a017_adcUnderVoltType 1;
BA_ "Confidence" SG_ 1365 RADC_a017_adcVoltage 1;
BA_ "Confidence" SG_ 1365 RADC_a019_internalSWFaultType 1;
BA_ "Confidence" SG_ 1365 RADC_a019_internalSWFaultCoreID 1;
BA_ "Confidence" SG_ 1365 RADC_a020_ecuTemp 1;
BA_ "Confidence" SG_ 1365 RADC_a023_ecuTemp 1;
BA_ "Confidence" SG_ 1365 RADC_a025_ecuVoltage 1;
BA_ "Confidence" SG_ 1365 RADC_a026_ecuVoltage 1;
BA_ "Confidence" SG_ 1365 RADC_a027_nvmFailureType 1;
BA_ "Confidence" SG_ 1365 RADC_a028_rfComRegCheckFail 1;
BA_ "Confidence" SG_ 1365 RADC_a029_rhcChirpMonErrType 1;
BA_ "Confidence" SG_ 1365 RADC_a029_rhcRxLongTermErrType 1;
BA_ "Confidence" SG_ 1365 RADC_a029_rhcRxErrType 1;
BA_ "Confidence" SG_ 1365 RADC_a029_rhcVcoPowerErrType 1;
BA_ "Confidence" SG_ 1365 RADC_a029_rhcSp1ErrType 1;
BA_ "Confidence" SG_ 1365 RADC_a029_rhcFdcErrType 1;
BA_ "Confidence" SG_ 1365 RADC_a030_rspErrType 1;
BA_ "Confidence" SG_ 1365 RADC_a031_horizMisalignAngle 1;
BA_ "Confidence" SG_ 1365 RADC_a031_vertMisalignAngle 1;
BA_ "Confidence" SG_ 1365 RADC_a032_blockageType 1;
BA_ "Confidence" SG_ 1365 RADC_a032_block_SPMBlockageState 1;
BA_ "Confidence" SG_ 1365 RADC_a032_block_SPMSelfTestState 1;
BA_ "Confidence" SG_ 1365 RADC_a032_block_ucEstiRange 1;
BA_ "Confidence" SG_ 1365 RADC_a041_vinErrType 1;
BA_ "Confidence" SG_ 1365 RADC_a042_carConfigErrType 1;
BA_ "Confidence" SG_ 1365 RADC_a043_inertialSignalsErrType 1;
BA_ "Confidence" SG_ 1365 RADC_a044_stwAngleErrType 1;
BA_ "Confidence" SG_ 1365 RADC_a045_vehicleStateErrType 1;
BA_ "Confidence" SG_ 1365 RADC_a046_wheelSpeedsErrType 1;
BA_ "Confidence" SG_ 1365 RADC_a047_chassisTypeExp 1;
BA_ "GenSigSNA" SG_ 1365 RADC_a047_chassisTypeExp "7";
BA_ "Confidence" SG_ 1365 RADC_a047_chassisTypeRx 1;
BA_ "GenSigSNA" SG_ 1365 RADC_a047_chassisTypeRx "7";
BA_ "Confidence" SG_ 1365 RADC_a048_airSuspensionExp 1;
BA_ "GenSigSNA" SG_ 1365 RADC_a048_airSuspensionExp "7";
BA_ "Confidence" SG_ 1365 RADC_a048_airSuspensionRx 1;
BA_ "GenSigSNA" SG_ 1365 RADC_a048_airSuspensionRx "7";
BA_ "Confidence" SG_ 1365 RADC_a049_fourWheelDriveExp 1;
BA_ "GenSigSNA" SG_ 1365 RADC_a049_fourWheelDriveExp "3";
BA_ "Confidence" SG_ 1365 RADC_a049_fourWheelDriveRx 1;
BA_ "GenSigSNA" SG_ 1365 RADC_a049_fourWheelDriveRx "3";
BA_ "Confidence" SG_ 1365 RADC_a051_epasTypeExp 1;
BA_ "GenSigSNA" SG_ 1365 RADC_a051_epasTypeExp "7";
BA_ "Confidence" SG_ 1365 RADC_a051_epasTypeRx 1;
BA_ "GenSigSNA" SG_ 1365 RADC_a051_epasTypeRx "7";
BA_ "Confidence" SG_ 1365 RADC_a052_radarPositionExp 1;
BA_ "GenSigSNA" SG_ 1365 RADC_a052_radarPositionExp "7";
BA_ "Confidence" SG_ 1365 RADC_a052_radarPositionRx 1;
BA_ "GenSigSNA" SG_ 1365 RADC_a052_radarPositionRx "7";
BA_ "Confidence" SG_ 1365 RADC_a054_block_RoadbeamTimeCnt 1;
BA_ "Confidence" SG_ 1365 RADC_a055_block_usTimeoutWayCnt 1;
BA_ "Confidence" SG_ 1365 RADC_a055_block_ucTimeoutTimeCnt 1;
BA_ "SystemSignalLongSymbol" SG_ 1365 RADC_a055_bblock_ucTimeoutBlkPro "RADC_a055_bblock_ucTimeoutBlkProb";
BA_ "Confidence" SG_ 1365 RADC_a055_block_usFullBlkTimer 1;
BA_ "Confidence" SG_ 1329 RADC_infoIndex 1;
BA_ "Confidence" SG_ 1329 RADC_infoBuildType 0;
BA_ "Confidence" SG_ 1329 RADC_infoBuildConfigID 0;
BA_ "Confidence" SG_ 1329 RADC_infoHardwareID 0;
BA_ "Confidence" SG_ 1329 RADC_infoComponentID 0;
BA_ "Confidence" SG_ 1329 RADC_infoPcbaID 0;
BA_ "Confidence" SG_ 1329 RADC_infoAssemblyID 0;
BA_ "Confidence" SG_ 1329 RADC_infoUsageID 0;
BA_ "Confidence" SG_ 1329 RADC_infoSubUsageID 0;
BA_ "Confidence" SG_ 1329 RADC_infoApplicationCRC 0;
BA_ "Confidence" SG_ 1329 RADC_infoPlatformType 0;
BA_ "Confidence" SG_ 1329 RADC_infoMajorVersion 0;
BA_ "Confidence" SG_ 1329 RADC_infoBranchOrigin 0;
BA_ "Confidence" SG_ 1329 RADC_infoMaturity 0;
BA_ "Confidence" SG_ 1329 RADC_infoHardwareRevision 0;
BA_ "Confidence" SG_ 1329 RADC_infoBootUdsProtoVersion 0;
BA_ "Confidence" SG_ 1329 RADC_infoBootloaderCRC 0;
BA_ "Confidence" SG_ 1252 RCM3_alertID 1;
BA_ "Confidence" SG_ 1252 RCM3_alertState 1;
BA_ "Confidence" SG_ 1010 RCM3_matrixIndex 1;
BA_ "Confidence" SG_ 257 RCM_yawRate 0;
BA_ "GenSigSNA" SG_ 257 RCM_yawRate "32768";
BA_ "Confidence" SG_ 257 RCM_pitchRate 0;
BA_ "GenSigSNA" SG_ 257 RCM_pitchRate "16384";
BA_ "Confidence" SG_ 257 RCM_rollRate 0;
BA_ "GenSigSNA" SG_ 257 RCM_rollRate "16384";
BA_ "Confidence" SG_ 257 RCM_rollRateQF 0;
BA_ "Confidence" SG_ 257 RCM_yawRateQF 0;
BA_ "Confidence" SG_ 257 RCM_pitchRateQF 0;
BA_ "Confidence" SG_ 257 RCM_inertial1Counter 0;
BA_ "Confidence" SG_ 257 RCM_inertial1Checksum 0;
BA_ "Confidence" SG_ 273 RCM_longitudinalAccel 0;
BA_ "GenSigSNA" SG_ 273 RCM_longitudinalAccel "32768";
BA_ "Confidence" SG_ 273 RCM_lateralAccel 0;
BA_ "GenSigSNA" SG_ 273 RCM_lateralAccel "32768";
BA_ "Confidence" SG_ 273 RCM_verticalAccel 0;
BA_ "GenSigSNA" SG_ 273 RCM_verticalAccel "32768";
BA_ "Confidence" SG_ 273 RCM_longitudinalAccelQF 0;
BA_ "Confidence" SG_ 273 RCM_lateralAccelQF 0;
BA_ "Confidence" SG_ 273 RCM_verticalAccelQF 0;
BA_ "Confidence" SG_ 273 RCM_CGTranslationFault 0;
BA_ "Confidence" SG_ 273 RCM_inertial2Counter 0;
BA_ "Confidence" SG_ 273 RCM_inertial2Checksum 0;
BA_ "Confidence" SG_ 849 RCM_infoIndex 1;
BA_ "Confidence" SG_ 849 RCM_infoBuildType 0;
BA_ "Confidence" SG_ 849 RCM_infoComponentID 0;
BA_ "Confidence" SG_ 849 RCM_infoPcbaID 0;
BA_ "Confidence" SG_ 849 RCM_infoAssemblyID 0;
BA_ "Confidence" SG_ 849 RCM_infoUsageID 0;
BA_ "Confidence" SG_ 849 RCM_infoApplicationCRC 0;
BA_ "Confidence" SG_ 849 RCM_infoBootUdsProtoVersion 0;
BA_ "Confidence" SG_ 849 RCM_infoBootloaderCRC 0;
BA_ "Confidence" SG_ 849 RCM_infoAlgoCalID 0;
BA_ "Confidence" SG_ 849 RCM_infoVariantCRC 0;
BA_ "Confidence" SG_ 529 RCM_statusChecksum 0;
BA_ "Confidence" SG_ 529 RCM_statusCounter 0;
BA_ "Confidence" SG_ 529 RCM_armStatus 0;
BA_ "GenSigSNA" SG_ 529 RCM_armStatus "3";
BA_ "Confidence" SG_ 529 RCM_warningIndicatorState 0;
BA_ "GenSigSNA" SG_ 529 RCM_warningIndicatorState "3";
BA_ "Confidence" SG_ 529 RCM_passAirbagIndicatorRequest 0;
BA_ "GenSigSNA" SG_ 529 RCM_passAirbagIndicatorRequest "3";
BA_ "Confidence" SG_ 529 RCM_airbagCutoffStatus 0;
BA_ "GenSigSNA" SG_ 529 RCM_airbagCutoffStatus "3";
BA_ "Confidence" SG_ 529 RCM_alrSwitchStatus 0;
BA_ "GenSigSNA" SG_ 529 RCM_alrSwitchStatus "3";
BA_ "Confidence" SG_ 529 RCM_vinLearnFlag 0;
BA_ "GenSigSNA" SG_ 529 RCM_vinLearnFlag "3";
BA_ "Confidence" SG_ 529 RCM_seatTrackPositionDrvr 0;
BA_ "GenSigSNA" SG_ 529 RCM_seatTrackPositionDrvr "3";
BA_ "Confidence" SG_ 529 RCM_seatTrackPositionPass 0;
BA_ "GenSigSNA" SG_ 529 RCM_seatTrackPositionPass "3";
BA_ "Confidence" SG_ 529 RCM_edr1State 0;
BA_ "Confidence" SG_ 529 RCM_edr2State 0;
BA_ "Confidence" SG_ 529 RCM_keepPowerReason 0;
BA_ "GenSigSNA" SG_ 529 RCM_keepPowerReason "8";
BA_ "Confidence" SG_ 529 RCM_imuOffsetLearnState 0;
BA_ "Confidence" SG_ 529 RCM_edr3State 0;
BA_ "Confidence" SG_ 529 RCM_driverOrientationInitStatus 0;
BA_ "GenSigSNA" SG_ 529 RCM_driverOrientationInitStatus "7";
BA_ "Confidence" SG_ 529 RCM_occupantClassificationSource 0;
BA_ "Confidence" SG_ 529 RCM_pedProEDR1State 0;
BA_ "Confidence" SG_ 529 RCM_pedProEDR2State 0;
BA_ "Confidence" SG_ 831 RCU_infoIndex 1;
BA_ "Confidence" SG_ 831 RCU_infoPcbaID 0;
BA_ "Confidence" SG_ 831 RCU_infoAssemblyID 0;
BA_ "Confidence" SG_ 831 RCU_infoUsageID 0;
BA_ "Confidence" SG_ 831 RCU_infoSubUsageID 0;
BA_ "Confidence" SG_ 879 TPMS_c_globalHardWarning 0;
BA_ "Confidence" SG_ 879 TPMS_c_globalSoftWarning 0;
BA_ "Confidence" SG_ 879 TPMS_systemMalfunction 0;
BA_ "Confidence" SG_ 879 TPMS_WA_version 0;
BA_ "Confidence" SG_ 879 TPMS_globalDeltaPressure 0;
BA_ "Confidence" SG_ 879 TPMS_newSensorLearnt 0;
BA_ "Confidence" SG_ 879 TPMS_softWarningRR 0;
BA_ "Confidence" SG_ 879 TPMS_hardWarningRR 0;
BA_ "Confidence" SG_ 879 TPMS_softWarningRL 0;
BA_ "Confidence" SG_ 879 TPMS_hardWarningRL 0;
BA_ "Confidence" SG_ 879 TPMS_softWarningFR 0;
BA_ "Confidence" SG_ 879 TPMS_hardWarningFR 0;
BA_ "Confidence" SG_ 879 TPMS_softWarningFL 0;
BA_ "Confidence" SG_ 879 TPMS_hardWarningFL 0;
BA_ "Confidence" SG_ 879 TPMS_learningStatus 0;
BA_ "Confidence" SG_ 879 TPMS_localisationStatus 0;
BA_ "Confidence" SG_ 879 TPMS_deltaPressWarningFL 0;
BA_ "Confidence" SG_ 879 TPMS_deltaPressWarningFR 0;
BA_ "Confidence" SG_ 879 TPMS_deltaPressWarningRL 0;
BA_ "Confidence" SG_ 879 TPMS_deltaPressWarningRR 0;
BA_ "Confidence" SG_ 879 TPMS_sensorNoResponseFL 0;
BA_ "Confidence" SG_ 879 TPMS_sensorNoResponseFR 0;
BA_ "Confidence" SG_ 879 TPMS_sensorNoResponseRL 0;
BA_ "Confidence" SG_ 879 TPMS_sensorNoResponseRR 0;
BA_ "Confidence" SG_ 879 TPMS_sensorThermShutdownFL 0;
BA_ "Confidence" SG_ 879 TPMS_sensorThermShutdownFR 0;
BA_ "Confidence" SG_ 879 TPMS_sensorThermShutdownRL 0;
BA_ "Confidence" SG_ 879 TPMS_sensorThermShutdownRR 0;
BA_ "Confidence" SG_ 879 TPMS_sensorBatteryLowFL 0;
BA_ "Confidence" SG_ 879 TPMS_sensorBatteryLowFR 0;
BA_ "Confidence" SG_ 879 TPMS_sensorBatteryLowRL 0;
BA_ "Confidence" SG_ 879 TPMS_sensorBatteryLowRR 0;
BA_ "Confidence" SG_ 879 TPMS_sensorDefectiveFL 0;
BA_ "Confidence" SG_ 879 TPMS_sensorDefectiveFR 0;
BA_ "Confidence" SG_ 879 TPMS_sensorDefectiveRL 0;
BA_ "Confidence" SG_ 879 TPMS_sensorDefectiveRR 0;
BA_ "Confidence" SG_ 879 TPMS_ecuUnderVoltage 0;
BA_ "Confidence" SG_ 879 TPMS_ecuOverVoltage 0;
BA_ "Confidence" SG_ 879 TPMS_ecuRamRomNvMFail 0;
BA_ "Confidence" SG_ 879 TPMS_rfReceiverFail 0;
BA_ "Confidence" SG_ 879 TPMS_wheelPulseMissing 0;
BA_ "Confidence" SG_ 879 TPMS_vehicleSpeedFail 0;
BA_ "Confidence" SG_ 879 TPMS_externalTemperatureFail 0;
BA_ "Confidence" SG_ 879 TPMS_eolNotCompleted 0;
BA_ "Confidence" SG_ 879 TPMS_rcpFront 0;
BA_ "Confidence" SG_ 879 TPMS_rcpRear 0;
BA_ "Confidence" SG_ 799 TPMS_pressureFL 0;
BA_ "GenSigSNA" SG_ 799 TPMS_pressureFL "255";
BA_ "Confidence" SG_ 799 TPMS_temperatureFL 0;
BA_ "GenSigSNA" SG_ 799 TPMS_temperatureFL "255";
BA_ "Confidence" SG_ 799 TPMS_pressureFR 0;
BA_ "GenSigSNA" SG_ 799 TPMS_pressureFR "255";
BA_ "Confidence" SG_ 799 TPMS_temperatureFR 0;
BA_ "GenSigSNA" SG_ 799 TPMS_temperatureFR "255";
BA_ "Confidence" SG_ 799 TPMS_pressureRL 0;
BA_ "GenSigSNA" SG_ 799 TPMS_pressureRL "255";
BA_ "Confidence" SG_ 799 TPMS_temperatureRL 0;
BA_ "GenSigSNA" SG_ 799 TPMS_temperatureRL "255";
BA_ "Confidence" SG_ 799 TPMS_pressureRR 0;
BA_ "GenSigSNA" SG_ 799 TPMS_pressureRR "255";
BA_ "Confidence" SG_ 799 TPMS_temperatureRR 0;
BA_ "GenSigSNA" SG_ 799 TPMS_temperatureRR "255";
BA_ "Confidence" SG_ 1519 TPMS_infoIndex 1;
BA_ "Confidence" SG_ 1519 TPMS_infoComponentID 0;
BA_ "Confidence" SG_ 1519 TPMS_infoPcbaID 0;
BA_ "Confidence" SG_ 1519 TPMS_infoAssemblyID 0;
BA_ "Confidence" SG_ 1519 TPMS_infoUsageID 0;
BA_ "Confidence" SG_ 1519 TPMS_infoApplicationCRC 0;
BA_ "Confidence" SG_ 1519 TPMS_infoBootUdsProtoVersion 0;
BA_ "Confidence" SG_ 1519 TPMS_infoBootloaderCRC 0;
BA_ "Confidence" SG_ 659 UI_steeringTuneRequest 0;
BA_ "Confidence" SG_ 659 UI_tractionControlMode 0;
BA_ "Confidence" SG_ 659 UI_parkBrakeRequest 0;
BA_ "GenSigSNA" SG_ 659 UI_parkBrakeRequest "3";
BA_ "Confidence" SG_ 659 UI_narrowGarages 1;
BA_ "Confidence" SG_ 659 UI_winchModeRequest 0;
BA_ "Confidence" SG_ 659 UI_zeroSpeedConfirmed 1;
BA_ "GenSigSNA" SG_ 659 UI_zeroSpeedConfirmed "3";
BA_ "Confidence" SG_ 659 UI_trailerMode 0;
BA_ "Confidence" SG_ 659 UI_distanceUnits 1;
BA_ "Confidence" SG_ 659 UI_dasDebugEnable 1;
BA_ "Confidence" SG_ 659 UI_accOvertakeEnable 0;
BA_ "GenSigSNA" SG_ 659 UI_accOvertakeEnable "3";
BA_ "Confidence" SG_ 659 UI_aebEnable 0;
BA_ "GenSigSNA" SG_ 659 UI_aebEnable "3";
BA_ "Confidence" SG_ 659 UI_aesEnable 0;
BA_ "GenSigSNA" SG_ 659 UI_aesEnable "3";
BA_ "Confidence" SG_ 659 UI_ahlbEnable 0;
BA_ "GenSigSNA" SG_ 659 UI_ahlbEnable "3";
BA_ "Confidence" SG_ 659 UI_autoLaneChangeEnable 0;
BA_ "GenSigSNA" SG_ 659 UI_autoLaneChangeEnable "3";
BA_ "Confidence" SG_ 659 UI_winchProxUserOverride 0;
BA_ "Confidence" SG_ 659 UI_rebootAutopilot 1;
BA_ "Confidence" SG_ 659 UI_autoParkRequest 0;
BA_ "GenSigSNA" SG_ 659 UI_autoParkRequest "15";
BA_ "Confidence" SG_ 659 UI_bsdEnable 0;
BA_ "GenSigSNA" SG_ 659 UI_bsdEnable "3";
BA_ "Confidence" SG_ 659 UI_fcwEnable 0;
BA_ "GenSigSNA" SG_ 659 UI_fcwEnable "3";
BA_ "Confidence" SG_ 659 UI_fcwSensitivity 0;
BA_ "GenSigSNA" SG_ 659 UI_fcwSensitivity "3";
BA_ "Confidence" SG_ 659 UI_latControlEnable 0;
BA_ "GenSigSNA" SG_ 659 UI_latControlEnable "3";
BA_ "Confidence" SG_ 659 UI_ldwEnable 0;
BA_ "GenSigSNA" SG_ 659 UI_ldwEnable "3";
BA_ "Confidence" SG_ 659 UI_pedalSafetyEnable 1;
BA_ "GenSigSNA" SG_ 659 UI_pedalSafetyEnable "3";
BA_ "Confidence" SG_ 659 UI_pedalMap_epas 1;
BA_ "Confidence" SG_ 659 UI_redLightStopSignEnable 1;
BA_ "GenSigSNA" SG_ 659 UI_redLightStopSignEnable "3";
BA_ "Confidence" SG_ 659 UI_selfParkTune 1;
BA_ "GenSigSNA" SG_ 659 UI_selfParkTune "15";
BA_ "Confidence" SG_ 659 UI_chassisControlCounter 1;
BA_ "Confidence" SG_ 659 UI_chassisControlChecksum 0;
BA_ "Confidence" SG_ 664 UI_csaOfframpCurvC2 1;
BA_ "Confidence" SG_ 664 UI_csaOfframpCurvC3 1;
BA_ "Confidence" SG_ 664 UI_csaOfframpCurvRange 1;
BA_ "Confidence" SG_ 679 UI_csaRoadCurvC2 1;
BA_ "Confidence" SG_ 679 UI_csaRoadCurvC3 1;
BA_ "Confidence" SG_ 679 UI_csaRoadCurvRange 1;
BA_ "Confidence" SG_ 1096 UI_anonDebugFlag1 1;
BA_ "Confidence" SG_ 1096 UI_anonDebugFlag2 1;
BA_ "Confidence" SG_ 1096 UI_anonDebugFlag3 1;
BA_ "Confidence" SG_ 1096 UI_anonDebugFlag4 1;
BA_ "Confidence" SG_ 1016 UI_autopilotControlRequest 1;
BA_ "Confidence" SG_ 1016 UI_ulcStalkConfirm 0;
BA_ "Confidence" SG_ 1016 UI_curvSpeedAdaptDisable 1;
BA_ "Confidence" SG_ 1016 UI_lssLkaEnabled 0;
BA_ "Confidence" SG_ 1016 UI_lssLdwEnabled 0;
BA_ "Confidence" SG_ 1016 UI_exceptionListEnable 1;
BA_ "Confidence" SG_ 1016 UI_roadCheckDisable 1;
BA_ "Confidence" SG_ 1016 UI_driveOnMapsEnable 0;
BA_ "Confidence" SG_ 1016 UI_handsOnRequirementDisable 1;
BA_ "Confidence" SG_ 1016 UI_fuseLanesDisable 1;
BA_ "Confidence" SG_ 1016 UI_fuseHPPDisable 1;
BA_ "Confidence" SG_ 1016 UI_fuseVehiclesDisable 1;
BA_ "Confidence" SG_ 1016 UI_visionSpeedType 1;
BA_ "Confidence" SG_ 1016 UI_curvatureDatabaseOnly 1;
BA_ "Confidence" SG_ 1016 UI_lssElkEnabled 0;
BA_ "Confidence" SG_ 1016 UI_summonExitType 1;
BA_ "GenSigSNA" SG_ 1016 UI_summonExitType "3";
BA_ "Confidence" SG_ 1016 UI_summonEntryType 1;
BA_ "GenSigSNA" SG_ 1016 UI_summonEntryType "3";
BA_ "Confidence" SG_ 1016 UI_selfParkRequest 0;
BA_ "GenSigSNA" SG_ 1016 UI_selfParkRequest "15";
BA_ "Confidence" SG_ 1016 UI_summonReverseDist 1;
BA_ "GenSigSNA" SG_ 1016 UI_summonReverseDist "63";
BA_ "Confidence" SG_ 1016 UI_drivingSide 1;
BA_ "Confidence" SG_ 1016 UI_accFollowDistanceSetting 1;
BA_ "GenSigSNA" SG_ 1016 UI_accFollowDistanceSetting "7";
BA_ "Confidence" SG_ 1016 UI_followNavRouteEnable 0;
BA_ "Confidence" SG_ 1016 UI_ulcSpeedConfig 0;
BA_ "Confidence" SG_ 1016 UI_ulcBlindSpotConfig 1;
BA_ "Confidence" SG_ 1016 UI_suppressExitPassingLane 0;
BA_ "Confidence" SG_ 1016 UI_smartSummonType 0;
BA_ "Confidence" SG_ 1016 UI_source3D 1;
BA_ "Confidence" SG_ 1016 UI_isaSpeedingChimeMuted 0;
BA_ "Confidence" SG_ 568 UI_mapSpeedLimitDependency 1;
BA_ "GenSigSNA" SG_ 568 UI_mapSpeedLimitDependency "7";
BA_ "Confidence" SG_ 568 UI_roadClass 0;
BA_ "GenSigSNA" SG_ 568 UI_roadClass "0";
BA_ "Confidence" SG_ 568 UI_inSuperchargerGeofence 1;
BA_ "Confidence" SG_ 568 UI_mapSpeedUnits 1;
BA_ "Confidence" SG_ 568 UI_mapSpeedLimit 1;
BA_ "GenSigSNA" SG_ 568 UI_mapSpeedLimit "31";
BA_ "Confidence" SG_ 568 UI_mapSpeedLimitType 1;
BA_ "GenSigSNA" SG_ 568 UI_mapSpeedLimitType "7";
BA_ "Confidence" SG_ 568 UI_countryCode 1;
BA_ "GenSigSNA" SG_ 568 UI_countryCode "1023";
BA_ "Confidence" SG_ 568 UI_streetCount 1;
BA_ "Confidence" SG_ 568 UI_gpsRoadMatch 1;
BA_ "Confidence" SG_ 568 UI_navRouteActive 0;
BA_ "Confidence" SG_ 568 UI_parallelAutoparkEnabled 0;
BA_ "Confidence" SG_ 568 UI_perpendicularAutoparkEnabled 0;
BA_ "Confidence" SG_ 568 UI_nextBranchDist 1;
BA_ "GenSigSNA" SG_ 568 UI_nextBranchDist "31";
BA_ "Confidence" SG_ 568 UI_controlledAccess 0;
BA_ "Confidence" SG_ 568 UI_nextBranchLeftOffRamp 1;
BA_ "Confidence" SG_ 568 UI_nextBranchRightOffRamp 1;
BA_ "Confidence" SG_ 568 UI_rejectLeftLane 1;
BA_ "Confidence" SG_ 568 UI_rejectRightLane 1;
BA_ "Confidence" SG_ 568 UI_rejectHPP 1;
BA_ "Confidence" SG_ 568 UI_rejectNav 1;
BA_ "Confidence" SG_ 568 UI_rejectLeftFreeSpace 1;
BA_ "Confidence" SG_ 568 UI_rejectRightFreeSpace 1;
BA_ "Confidence" SG_ 568 UI_rejectAutosteer 1;
BA_ "Confidence" SG_ 568 UI_rejectHandsOn 1;
BA_ "Confidence" SG_ 568 UI_acceptBottsDots 1;
BA_ "Confidence" SG_ 568 UI_autosteerRestricted 0;
BA_ "Confidence" SG_ 568 UI_pmmEnabled 1;
BA_ "Confidence" SG_ 568 UI_scaEnabled 1;
BA_ "Confidence" SG_ 568 UI_mapDataCounter 1;
BA_ "Confidence" SG_ 568 UI_mapDataChecksum 0;
BA_ "Confidence" SG_ 536 UI_roadSign 1;
BA_ "GenSigSNA" SG_ 536 UI_roadSign "255";
BA_ "Confidence" SG_ 536 UI_splineLocConfidence 1;
BA_ "GenSigSNA" SG_ 536 UI_splineLocConfidence "0";
BA_ "Confidence" SG_ 536 UI_stopSignStopLineDist 1;
BA_ "GenSigSNA" SG_ 536 UI_stopSignStopLineDist "1023";
BA_ "Confidence" SG_ 536 UI_stopSignStopLineConf 1;
BA_ "GenSigSNA" SG_ 536 UI_stopSignStopLineConf "0";
BA_ "Confidence" SG_ 536 UI_trafficLightStopLineDist 1;
BA_ "GenSigSNA" SG_ 536 UI_trafficLightStopLineDist "1023";
BA_ "Confidence" SG_ 536 UI_trafficLightStopLineConf 1;
BA_ "GenSigSNA" SG_ 536 UI_trafficLightStopLineConf "0";
BA_ "Confidence" SG_ 536 UI_baseMapSpeedLimitMPS 1;
BA_ "GenSigSNA" SG_ 536 UI_baseMapSpeedLimitMPS "255";
BA_ "Confidence" SG_ 536 UI_bottomQrtlFleetSpeedMPS 1;
BA_ "GenSigSNA" SG_ 536 UI_bottomQrtlFleetSpeedMPS "255";
BA_ "Confidence" SG_ 536 UI_topQrtlFleetSpeedMPS 1;
BA_ "GenSigSNA" SG_ 536 UI_topQrtlFleetSpeedMPS "255";
BA_ "Confidence" SG_ 536 UI_meanFleetSplineSpeedMPS 1;
BA_ "GenSigSNA" SG_ 536 UI_meanFleetSplineSpeedMPS "255";
BA_ "Confidence" SG_ 536 UI_medianFleetSpeedMPS 1;
BA_ "GenSigSNA" SG_ 536 UI_medianFleetSpeedMPS "255";
BA_ "Confidence" SG_ 536 UI_meanFleetSplineAccelMPS2 1;
BA_ "GenSigSNA" SG_ 536 UI_meanFleetSplineAccelMPS2 "255";
BA_ "Confidence" SG_ 536 UI_rampType 1;
BA_ "GenSigSNA" SG_ 536 UI_rampType "0";
BA_ "Confidence" SG_ 536 UI_valhallaRamp 1;
BA_ "GenSigSNA" SG_ 536 UI_valhallaRamp "0";
BA_ "Confidence" SG_ 536 UI_currSplineIdFull 1;
BA_ "GenSigSNA" SG_ 536 UI_currSplineIdFull "0";
BA_ "Confidence" SG_ 760 UI_gpsHDOP 1;
BA_ "Confidence" SG_ 760 UI_gpsVehicleHeading 1;
BA_ "Confidence" SG_ 760 UI_gpsVehicleSpeed 1;
BA_ "Confidence" SG_ 760 UI_userSpeedOffset 1;
BA_ "Confidence" SG_ 760 UI_mapSpeedLimitUnits 0;
BA_ "Confidence" SG_ 760 UI_userSpeedOffsetUnits 1;
BA_ "Confidence" SG_ 760 UI_mppSpeedLimit 0;
BA_ "Confidence" SG_ 760 UI_gpsNmeaMIA 0;
BA_ "Confidence" SG_ 760 UI_gpsAntennaDisconnected 0;
BA_ "Confidence" SG_ 760 UI_conditionalLimitActive 0;
BA_ "Confidence" SG_ 760 UI_conditionalSpeedLimit 0;
BA_ "GenSigSNA" SG_ 760 UI_conditionalSpeedLimit "31";
BA_ "Confidence" SG_ 985 UI_latitudeOffset 1;
BA_ "Confidence" SG_ 985 UI_longitudeOffset 1;
BA_ "Confidence" SG_ 777 UI_latitude 1;
BA_ "Confidence" SG_ 777 UI_longitude 1;
BA_ "Confidence" SG_ 777 UI_gpsAccuracy 1;
BA_ "GenSigSNA" SG_ 777 UI_gpsAccuracy "127";
BA_ "Confidence" SG_ 1011 UI_odometer 0;
BA_ "GenSigSNA" SG_ 1011 UI_odometer "16777215";
BA_ "Confidence" SG_ 987 UI_phoneLatitude 1;
BA_ "Confidence" SG_ 987 UI_phoneLongitude 1;
BA_ "Confidence" SG_ 987 UI_phoneGpsAccuracy 1;
BA_ "GenSigSNA" SG_ 987 UI_phoneGpsAccuracy "127";
BA_ "Confidence" SG_ 698 UI_radarTargetDx 1;
BA_ "Confidence" SG_ 698 UI_radarTargetDxEnd 1;
BA_ "Confidence" SG_ 632 UI_roadCurvC0 1;
BA_ "Confidence" SG_ 632 UI_roadCurvC1 1;
BA_ "Confidence" SG_ 632 UI_roadCurvC2 1;
BA_ "Confidence" SG_ 632 UI_roadCurvC3 1;
BA_ "Confidence" SG_ 632 UI_roadCurvRange 1;
BA_ "Confidence" SG_ 632 UI_roadCurvHealth 1;
BA_ "Confidence" SG_ 723 UI_solarAzimuthAngle 1;
BA_ "GenSigSNA" SG_ 723 UI_solarAzimuthAngle "32768";
BA_ "Confidence" SG_ 723 UI_solarAzimuthAngleCarRef 1;
BA_ "GenSigSNA" SG_ 723 UI_solarAzimuthAngleCarRef "255";
BA_ "Confidence" SG_ 723 UI_isSunUp 0;
BA_ "GenSigSNA" SG_ 723 UI_isSunUp "3";
BA_ "Confidence" SG_ 723 UI_solarElevationAngle 0;
BA_ "GenSigSNA" SG_ 723 UI_solarElevationAngle "127";
BA_ "Confidence" SG_ 723 UI_screenPCBTemperature 0;
BA_ "Confidence" SG_ 723 UI_minsToSunset 0;
BA_ "Confidence" SG_ 723 UI_minsToSunrise 0;
BA_ "Confidence" SG_ 851 UI_touchActive 0;
BA_ "Confidence" SG_ 851 UI_audioActive 0;
BA_ "Confidence" SG_ 851 UI_bluetoothActive 1;
BA_ "Confidence" SG_ 851 UI_cellActive 0;
BA_ "Confidence" SG_ 851 UI_displayReady 0;
BA_ "Confidence" SG_ 851 UI_displayOn 0;
BA_ "Confidence" SG_ 851 UI_wifiActive 0;
BA_ "Confidence" SG_ 851 UI_wifiConnected 0;
BA_ "Confidence" SG_ 851 UI_systemActive 1;
BA_ "Confidence" SG_ 851 UI_readyForDrive 0;
BA_ "Confidence" SG_ 851 UI_cellConnected 0;
BA_ "Confidence" SG_ 851 UI_vpnActive 0;
BA_ "Confidence" SG_ 851 UI_autopilotTrial 1;
BA_ "Confidence" SG_ 851 UI_factoryReset 0;
BA_ "GenSigSNA" SG_ 851 UI_factoryReset "0";
BA_ "Confidence" SG_ 851 UI_gpsActive 0;
BA_ "Confidence" SG_ 851 UI_screenshotActive 1;
BA_ "Confidence" SG_ 851 UI_radioActive 1;
BA_ "Confidence" SG_ 851 UI_cellNetworkTechnology 0;
BA_ "GenSigSNA" SG_ 851 UI_cellNetworkTechnology "15";
BA_ "Confidence" SG_ 851 UI_cellReceiverPower 1;
BA_ "Confidence" SG_ 851 UI_falseTouchCounter 0;
BA_ "Confidence" SG_ 851 UI_developmentCar 1;
BA_ "Confidence" SG_ 851 UI_cameraActive 1;
BA_ "Confidence" SG_ 851 UI_cellSignalBars 0;
BA_ "GenSigSNA" SG_ 851 UI_cellSignalBars "7";
BA_ "Confidence" SG_ 851 UI_trailerModeTelltale 0;
BA_ "Confidence" SG_ 851 UI_pcbTemperature 0;
BA_ "Confidence" SG_ 851 UI_cpuTemperature 0;
BA_ "Confidence" SG_ 988 UI_goalLatitude 1;
BA_ "Confidence" SG_ 988 UI_goalLongitude 1;
BA_ "Confidence" SG_ 988 UI_goalOrientation 1;
BA_ "Confidence" SG_ 1064 UI_TCR_minRCS 1;
BA_ "Confidence" SG_ 1064 UI_TCR_maxDy 1;
BA_ "Confidence" SG_ 856 UI_TPMSMode 1;
BA_ "Confidence" SG_ 856 UI_TPMSLearnIDMode 1;
BA_ "Confidence" SG_ 856 UI_sizeOfWheelSelect 1;
BA_ "Confidence" SG_ 1827 UI_ussSensorIdX 1;
BA_ "Confidence" SG_ 1829 UI_ussSensorIdY 1;
BA_ "Confidence" SG_ 954 USM_matrixIndex 1;
BA_ "Confidence" SG_ 807 USM_infoIndex 1;
BA_ "Confidence" SG_ 807 USM_infoBuildType 0;
BA_ "Confidence" SG_ 807 USM_infoBuildConfigId 0;
BA_ "Confidence" SG_ 807 USM_infoHardwareId 0;
BA_ "Confidence" SG_ 807 USM_infoComponentId 0;
BA_ "Confidence" SG_ 807 USM_infoPcbaId 0;
BA_ "Confidence" SG_ 807 USM_infoAssemblyId 0;
BA_ "GenSigSNA" SG_ 807 USM_infoAssemblyId "255";
BA_ "Confidence" SG_ 807 USM_infoUsageId 0;
BA_ "Confidence" SG_ 807 USM_infoSubUsageId 0;
BA_ "Confidence" SG_ 807 USM_infoAppCrc 0;
VAL_ 782 PARK_pscRightCurbType 2 "HIGH_CURB" 1 "LOW_CURB" 0 "VIRTUAL_CURB" ;
VAL_ 782 PARK_pscLeftCurbType 2 "HIGH_CURB" 1 "LOW_CURB" 0 "VIRTUAL_CURB" ;
VAL_ 782 PARK_autoCalComplete 1 "COMPLETE" 0 "INCOMPLETE" ;
VAL_ 782 PARK_geometryType 3 "MODELY" 2 "MODEL3" 1 "MODELX" 0 "MODELS" ;
VAL_ 782 PARK_tireFitment 3 "SNA" 2 "NOT_USED" 1 "STAGGERED" 0 "SQUARE" ;
VAL_ 782 PARK_rackDetected 3 "SNA" 2 "RACK_DETECTED" 1 "NO_RACK" 0 "UNKNOWN" ;
VAL_ 782 PARK_sdiActive 1 "SDI_ENABLED" 0 "SDI_DISABLED" ;
VAL_ 782 PARK_sdiNoise 3 "SDI_NOISE_SNA" 2 "SDI_NOISE_RAIN" 1 "SDI_NOISE_HIGH" 0 "SDI_NOISE_NOMINAL" ;
VAL_ 782 PARK_sdiBlindSpotRight 3 "SNA" 2 "UNUSED" 1 "WARNING" 0 "NO_WARNING" ;
VAL_ 782 PARK_sdiBlindSpotLeft 3 "SNA" 2 "UNUSED" 1 "WARNING" 0 "NO_WARNING" ;
VAL_ 782 PARK_sensorType 3 "SNA" 2 "VALEO_HP" 1 "VALEO_HPFL" 0 "NONE" ;
VAL_ 894 PARK_matrixIndex 1 "AlertMatrix1" 0 "AlertMatrix0" ;
VAL_ 1365 RADC_alertID 55 "a055_blockageInfo_Frame_2" 54 "a054_blockageInfo_Frame_1" 53 "a053_emError" 52 "a052_mismatcRadPos" 51 "a051_mismatchEPASType" 50 "a050_mismatchCountry" 49 "a049_mismatchFourWheelDrive" 48 "a048_mismatchAirSuspension" 47 "a047_mismatchChassisType" 46 "a046_wheelSpeedsErr" 45 "a045_vehicleStateErr" 44 "a044_steeringWheelAngleErr" 43 "a043_inertialSignalsErr" 42 "a042_carConfigErr" 41 "a041_vinErr" 40 "a040_wheelSpeedsMIA" 39 "a039_vehicleStateMIA" 38 "a038_steeringWheelAngleMIA" 37 "a037_inertialSignalsMIA" 36 "a036_carConfigMIA" 35 "a035_vinMIA" 34 "a034_vehDynamicsError" 33 "a033_sensorNeverAligned" 32 "a032_sensorBlocked" 31 "a031_sensorMisaligned" 30 "a030_rspError" 29 "a029_rhcError" 28 "a028_rfChipError" 27 "a027_nvmFailure" 26 "a026_underVoltage" 25 "a025_overVoltage" 24 "a024_underTempCrit" 23 "a023_underTemp" 22 "a022_tempImplausible" 21 "a021_overTempCrit" 20 "a020_overTemp" 19 "a019_internalSoftwareFault" 18 "a018_internalHardwareFault" 17 "a017_adcUnderVolt" 16 "a016_adcOverVolt" 15 "a015_fctSenInterference" 14 "a014_fctSelfTestNotDone" 13 "a013_ecuWdgError" 12 "a012_ecuSpiError" 11 "a011_ecuMcemError" 10 "a010_ecuIoHwAbError" 9 "a009_plantModeActive" 8 "a008_ecuHwSwInterlock" 7 "a007_ecuGptCheckError" 6 "a006_ecuFimError" 5 "a005_ecuEcuMError" 4 "a004_ecuCrcHwError" 3 "a003_ecuBistDisabled" 2 "a002_ecuAdcError" 1 "a001_can1BusOff" 0 "ALERT_DO_NOT_USE_ZERO" ;
VAL_ 1365 RADC_alertState 1 "SET" 0 "CLEARED" ;
VAL_ 1365 RADC_a002_ecuAdcErrType 1 "INVALID_CONV_MODE" 0 "LIMIT_RANGE" ;
VAL_ 1365 RADC_a008_interLockErrType 1 "SW_VERSION_MISMATCH" 0 "HW_SW_PROJECT_ID_INCOMPATIBLE" ;
VAL_ 1365 RADC_a011_ecuMcemErrType 10 "MCEM__ALARM_ISR" 9 "MCEM_E_CORRUPTED_HW_CONFIG" 8 "MCEM_E_FAULT" 7 "MCEM_E_FORBIDDEN_INVOCATION" 6 "MCEM_E_INIT_FAILED" 5 "MCEM_E_OPERATION_FAILED" 4 "MCU_E_CLOCK_FAILURE" 3 "MCU_E_MCME_PERIODIC_CHECK" 2 "MCU_E_MCPCU_PERIODIC_CHECK" 1 "MCU_E_MCRGM_PERIODIC_CHECK" 0 "MCU_E_QUARTZ_FAILURE" ;
VAL_ 1365 RADC_a013_ecuWdgErrType 3 "CORRUPT_CONFIG" 2 "DISABLE_REJECTED" 1 "INVALID_CALL" 0 "UNLOCKED" ;
VAL_ 1365 RADC_a016_adcOverVoltType 7 "5V_SMPS_OVER_VOLTAGE" 6 "4V5_LIN_VOLTAGECO_OVER_VOLTAGE" 5 "3V8_SMPS_OVER_VOLTAGE" 4 "3V3_LIN_ANALOG_OVER_VOLTAGE" 3 "3V3_LIN_DIGITAL_OVER_VOLTAGE" 2 "3V3_LIN_PA_OVER_VOLTAGE" 1 "3V3_LIN_VOLTAGECO_OVER_VOLTAGE" 0 "1V25_SMPS_OVER_VOLTAGE" ;
VAL_ 1365 RADC_a017_adcUnderVoltType 7 "5V_SMPS_UNDER_VOLTAGE" 6 "4V5_LIN_VOLTAGECO_UNDER_VOLTAGE" 5 "3V8_SMPS_UNDER_VOLTAGE" 4 "3V3_LIN_ANALOG_UNDER_VOLTAGE" 3 "3V3_LIN_DIGITAL_UNDER_VOLTAGE" 2 "3V3_LIN_PA_UNDER_VOLTAGE" 1 "3V3_LIN_VOLTAGECO_UNDER_VOLTAGE" 0 "1V25_SMPS_UNDER_VOLTAGE" ;
VAL_ 1365 RADC_a019_internalSWFaultType 110 "ADC_CALIBRATION" 109 "PROCESSOR_VERSION" 108 "FLASH_CYCLIC_CHECK" 107 "INTERNAL_VOLTAGE_FAILED" 106 "ATIC_RESET" 105 "LBIST_FAILED" 104 "MBIST_FAILED" 103 "STARTUP_ERROR" 102 "TEMP_CROSS_CHECK" 101 "ECC_INIT_FAILED" 100 "RADAR_CYCLE_VIOLATION" 99 "FLSP_INIT_FAILED" 98 "POWERUP_SEQ_TIMEOUT" 97 "IOHWAB_TIMEOUT" 96 "UBATT_OUT_OF_RANGE" 95 "EXCEPT_RESERVED_15" 94 "EXCEPT_RESERVED_14" 93 "EXCEPT_RESERVED_13" 92 "EXCEPT_TRAP" 91 "EXCEPT_CENTRAL" 90 "FCCU_HEALED_FAULT" 89 "FCCU_CHECKER_MISMATCH" 88 "PLL_STUCK" 87 "ECUM_REQUEST" 86 "SPI_ATIC_FAULT" 85 "SPI_MMIC_MISMATCH" 84 "SPI_MMIC_FAULT" 83 "ECC_OTHER_2BIT" 82 "ECC_CORE_ICACHE_2BIT" 81 "ECC_CORE_DCACHE_2BIT" 80 "ECC_CORE_IMEM_2BIT" 79 "ECC_CORE_DMEM_2BIT" 78 "ECC_EEPROM_2BIT" 77 "ECC_FLASH_2BIT" 76 "ECC_SRAM_2BIT" 75 "SMPU" 74 "IOHWAB" 73 "ECC_PATTERN_MISSING" 72 "WATCHDOG" 71 "WATCHDOG_INITIALIZATION" 70 "CLKMON_CALIBRATION" 69 "CLKMON_CONFIG_CHECK" 68 "CLKMON_INITIALIZATION" 67 "FCCU_FAULT_SIGNALED" 66 "FCCU_CORRUPTED_CONFIG" 65 "HW_SW_INCOMPATIBLE" 64 "SPE_CHECK" 63 "FPU_CHECK" 62 "ECC_SPT_2BIT" 61 "ECC_DMA_2BIT" 60 "ECC_HARDWARE_FAILURE" 59 "DRIVERINIT_FAILED" 58 "CORE2_STACK_OVERFLOW" 57 "CORE1_STACK_OVERFLOW" 56 "NVM_TIMEOUT" 55 "EXCEPT_ECC2BITERROR" 54 "EXCEPT_ECC1BITERROR" 53 "EXCEPT_DECREMENTER" 52 "EXCEPT_AP_UNAVAILABLE" 51 "EXCEPT_SYSTEM_CALL" 50 "E_FLOATINGPOINT_UNAVAIL" 49 "FCCU" 48 "INTENTIONAL_RESET" 47 "CYCLE_MON" 46 "TESTCASE_CONFIG" 45 "TESTCASE_ABORT" 44 "EXCEPT_CORE_FREEZE" 43 "INVALID_SAFESECTION" 42 "BUS_TEST" 41 "UNEXPECTED_RESET" 40 "ALU_CHECK" 39 "MISC_CHECK" 38 "APPL_CRC_CHECK" 37 "CONFIG_REGISTER_CHECK" 36 "CPU_REGISTER_CHECK" 35 "TPU_RAM_ADDRESS_BUS1" 34 "TPU_RAM_ADDRESS_BUS0" 33 "SRAM_ADDRESS_BUS1" 32 "SRAM_ADDRESS_BUS0" 31 "ECC_TIMEOUT" 30 "DCACHE_MARCHC" 29 "AD_CONVERTER" 28 "TASK_STACK" 27 "TASK_MON_LOGIC" 26 "SYSTEM_CYCLE_MON" 25 "EXCEPT_UNDEFINED" 24 "EXCEPT_ERROR_TPU_RAM" 23 "EXCEPT_ERROR_SRAM" 22 "EXCEPT_SHUTDOWN_OS" 21 "EXCEPT_EFP_ROUND" 20 "EXCEPT_EFP_DATA" 19 "EXCEPT_SPE_UNAVAIL" 18 "EXCEPT_INSTR_TLB_ERROR" 17 "EXCEPT_DATA_TLB_ERROR" 16 "EXCEPT_WATCHDOG_TIMER" 15 "EXCEPT_FIXED_INTER" 14 "EXCEPT_DEBUG" 13 "EXCEPT_PERFORMANCEMON" 12 "EXCEPT_PROGRAM" 11 "EXCEPT_ALIGN" 10 "EXCEPT_INSTRUCT_STORE" 9 "EXCEPT_DATA_STORE" 8 "EXCEPT_MACH_CHECK" 7 "EXCEPT_CRIT_INPUT" 6 "ROM_ECC_2BIT" 5 "RAM_ECC_2BIT" 4 "ROM_ECC_1BIT" 3 "RAM_ECC_1BIT" 2 "MCU_SUPPLY" 1 "TEMP_MON" 0 "NONE" ;
VAL_ 1365 RADC_a019_internalSWFaultCoreID 2 "2" 1 "1" 0 "0" ;
VAL_ 1365 RADC_a027_nvmFailureType 2 "INTEGRITY_FAILED" 1 "REQ_FAILED" 0 "RECORD_SIZE_MISSMATCH" ;
VAL_ 1365 RADC_a028_rfComRegCheckFail 4 "MON_RF_OVERTEMP" 3 "MON_RF_CHIP_TEMP_IMPLAUSIBLE" 2 "REG_CHECK_FAILED_LT" 1 "REG_CHECK_FAILED" 0 "REG_CHECK_CYCLE_FAILED" ;
VAL_ 1365 RADC_a029_rhcChirpMonErrType 2 "RG_LENGTH_ERROR_NS" 1 "RMSE_TOO_LARGE_NS" 0 "FREQ_ERROR_SPEC_TOO_LARGE_NS" ;
VAL_ 1365 RADC_a029_rhcRxLongTermErrType 6 "NOISE_POWER_TOO_HIGH_LT" 5 "SPURIOUS_PEAKS_TOO_HIGH_LT" 4 "SIGNAL_POWER_TOO_LOW_LT" 3 "TRANSFER_FUNCTION_ERR_LT" 2 "CHANNEL_VARIATION_ERR_LT" 1 "STC_FILTER_ERR_LT" 0 "NONLINEAR_ERR_LT" ;
VAL_ 1365 RADC_a029_rhcRxErrType 7 "RX_SPURIOUS_PEAKS_TOO_HIGH" 6 "LOAD_PULLING_TOO_HIGH_NS" 5 "RX_NOISE_POWER_TOO_HIGH" 4 "RX_SIGNAL_POWER_TOO_LOW" 3 "RX_TRANSFER_FUNCTION_ERR" 2 "RX_CHANNEL_VARIATION_ERR" 1 "RX_STC_FILTER_ERR" 0 "RX_NONLINEAR_ERR" ;
VAL_ 1365 RADC_a029_rhcVcoPowerErrType 1 "LOW" 0 "HIGH" ;
VAL_ 1365 RADC_a029_rhcSp1ErrType 0 "RHC_CTE_LUT_DUR_STUCK_ERR" ;
VAL_ 1365 RADC_a029_rhcFdcErrType 2 "LONG_TERM_ERROR_NS" 1 "RMSE_TOO_LARGE_NS" 0 "DRIFT_FREQ_TOO_LARGE_NS" ;
VAL_ 1365 RADC_a030_rspErrType 1 "LONG_TERM_ERROR" 0 "SHORT_TERM_ERROR" ;
VAL_ 1365 RADC_a032_blockageType 4 "FCTSEN_OBJ_NOT_MEASURED" 3 "FCTSEN_BLOCKAGE" 2 "FCTSEN_DEC_BLOCKAGE" 1 "FCTSEN_INC_BLOCKAGE" 0 "ALN_PATH_COMP_HIGH_NEAR" ;
VAL_ 1365 RADC_a032_block_SPMBlockageState 4 "GDB_UNKNOWN_DAMP" 3 "GDB_RDC_DAMP" 2 "GDB_FULL_DAMP" 1 "GDB_INC_DAMP" 0 "DB_NO_DAMP" ;
VAL_ 1365 RADC_a032_block_SPMSelfTestState 3 "ROADBEAM_TEST" 2 "STARTUP" 1 "ON" 0 "OFF" ;
VAL_ 1365 RADC_a041_vinErrType 5 "OVERRUN" 4 "INVALID_DATA" 3 "SEQUENCE" 2 "CHECKSUM" 1 "LENGTH" 0 "NONE" ;
VAL_ 1365 RADC_a042_carConfigErrType 5 "OVERRUN" 4 "INVALID_DATA" 3 "SEQUENCE" 2 "CHECKSUM" 1 "LENGTH" 0 "NONE" ;
VAL_ 1365 RADC_a043_inertialSignalsErrType 5 "OVERRUN" 4 "INVALID_DATA" 3 "SEQUENCE" 2 "CHECKSUM" 1 "LENGTH" 0 "NONE" ;
VAL_ 1365 RADC_a044_stwAngleErrType 5 "OVERRUN" 4 "INVALID_DATA" 3 "SEQUENCE" 2 "CHECKSUM" 1 "LENGTH" 0 "NONE" ;
VAL_ 1365 RADC_a045_vehicleStateErrType 5 "OVERRUN" 4 "INVALID_DATA" 3 "SEQUENCE" 2 "CHECKSUM" 1 "LENGTH" 0 "NONE" ;
VAL_ 1365 RADC_a046_wheelSpeedsErrType 5 "OVERRUN" 4 "INVALID_DATA" 3 "SEQUENCE" 2 "CHECKSUM" 1 "LENGTH" 0 "NONE" ;
VAL_ 1365 RADC_a047_chassisTypeExp 7 "SNA" 2 "MODEL_3_CHASSIS" 1 "MODEL_X_CHASSIS" 0 "MODEL_S_CHASSIS" ;
VAL_ 1365 RADC_a047_chassisTypeRx 7 "SNA" 2 "MODEL_3_CHASSIS" 1 "MODEL_X_CHASSIS" 0 "MODEL_S_CHASSIS" ;
VAL_ 1365 RADC_a048_airSuspensionExp 7 "SNA" 5 "TESLA_ADAPTIVE" 4 "TESLA_PLUS" 3 "TESLA_STANDARD" 2 "PLUS" 1 "STANDARD" 0 "NONE" ;
VAL_ 1365 RADC_a048_airSuspensionRx 7 "SNA" 5 "TESLA_ADAPTIVE" 4 "TESLA_PLUS" 3 "TESLA_STANDARD" 2 "PLUS" 1 "STANDARD" 0 "NONE" ;
VAL_ 1365 RADC_a049_fourWheelDriveExp 3 "SNA" 2 "UNUSED" 1 "4WD" 0 "2WD" ;
VAL_ 1365 RADC_a049_fourWheelDriveRx 3 "SNA" 2 "UNUSED" 1 "4WD" 0 "2WD" ;
VAL_ 1365 RADC_a051_epasTypeExp 7 "SNA" 4 "MANDO_VGR63_GEN3" 3 "MANDO_VGR66" 2 "MANDO_FGR64" 1 "BOSCH_L405" 0 "BOSCH_L538" ;
VAL_ 1365 RADC_a051_epasTypeRx 7 "SNA" 4 "MANDO_VGR63_GEN3" 3 "MANDO_VGR66" 2 "MANDO_FGR64" 1 "BOSCH_L405" 0 "BOSCH_L538" ;
VAL_ 1365 RADC_a052_radarPositionExp 7 "SNA" 3 "MODEL_3" 2 "MODELX" 1 "MODELS_2" 0 "MODELS" ;
VAL_ 1365 RADC_a052_radarPositionRx 7 "SNA" 3 "MODEL_3" 2 "MODELX" 1 "MODELS_2" 0 "MODELS" ;
VAL_ 1329 RADC_infoIndex 20 "Mux20" 19 "Mux19" 13 "Mux13" 11 "Mux11" 10 "Mux10" ;
VAL_ 1329 RADC_infoBuildType 4 "INFO_MFG_BUILD" 3 "INFO_TRACEABLE_CI_BUILD" 2 "INFO_LOCAL_BUILD" 1 "INFO_PLATFORM_BUILD" 0 "INFO_UNKNOWN_BUILD" ;
VAL_ 1252 RCM3_alertID 1 "RCM3_a001_LVPowerLossDetected" ;
VAL_ 1252 RCM3_alertState 1 "SET" 0 "CLEARED" ;
VAL_ 1010 RCM3_matrixIndex 0 "RCM3_AlertMatrix0" ;
VAL_ 257 RCM_yawRate -32768 "SNA" ;
VAL_ 257 RCM_pitchRate -16384 "SNA" ;
VAL_ 257 RCM_rollRate -16384 "SNA" ;
VAL_ 257 RCM_rollRateQF 3 "FAULTED" 2 "TEMP_INVALID" 1 "VALID" 0 "INIT" ;
VAL_ 257 RCM_yawRateQF 1 "NOT_FAULTED" 0 "FAULTED" ;
VAL_ 257 RCM_pitchRateQF 3 "FAULTED" 2 "TEMP_INVALID" 1 "VALID" 0 "INIT" ;
VAL_ 273 RCM_longitudinalAccel -32768 "SNA" ;
VAL_ 273 RCM_lateralAccel -32768 "SNA" ;
VAL_ 273 RCM_verticalAccel -32768 "SNA" ;
VAL_ 273 RCM_longitudinalAccelQF 1 "NOT_FAULTED" 0 "FAULTED" ;
VAL_ 273 RCM_lateralAccelQF 1 "NOT_FAULTED" 0 "FAULTED" ;
VAL_ 273 RCM_verticalAccelQF 1 "NOT_FAULTED" 0 "FAULTED" ;
VAL_ 273 RCM_CGTranslationFault 1 "RCM_COG_TRANSLATION_FAULTED" 0 "RCM_COG_TRANSLATION_NOT_FAULTED" ;
VAL_ 849 RCM_infoIndex 255 "END" 31 "SUBCOMPONENT_GITHASH" 30 "PACKAGE_SN_8_14" 29 "PACKAGE_SN_1_7" 27 "PACKAGE_PN_15_20" 26 "PACKAGE_PN_8_14" 25 "PACKAGE_PN_1_7" 23 "SUBCOMPONENT2" 22 "VARIANTCRC" 20 "UDS_PROTOCOL_BOOTCRC" 19 "VERSION_DEPRECATED" 18 "BOOTLOADER_GITHASH" 17 "APP_GITHASH" 16 "SUBCOMPONENT" 15 "BOOTLOADER_CRC" 14 "BOOTLOADER_SVN" 13 "APP_CRC" 11 "PCBAID_ASSYID_USAGEID" 10 "BUILD_HWID_COMPONENTID" 9 "DEPRECATED_9" 8 "DEPRECATED_8" 7 "DEPRECATED_7" 6 "DEPRECATED_6" 5 "DEPRECATED_5" 4 "DEPRECATED_4" 3 "DEPRECATED_3" 2 "DEPRECATED_2" 1 "DEPRECATED_1" 0 "DEPRECATED_0" ;
VAL_ 849 RCM_infoBuildType 4 "INFO_MFG_BUILD" 3 "INFO_TRACEABLE_CI_BUILD" 2 "INFO_LOCAL_BUILD" 1 "INFO_PLATFORM_BUILD" 0 "INFO_UNKNOWN_BUILD" ;
VAL_ 529 RCM_armStatus 3 "SNA" 2 "ARMED_WITH_NOFIRE_CAL" 1 "RCM_ARMED" 0 "RCM_UNARMED" ;
VAL_ 529 RCM_warningIndicatorState 3 "SNA" 1 "RCM_WARNING_INDICATOR_ON" 0 "RCM_WARNING_INDICATOR_OFF" ;
VAL_ 529 RCM_passAirbagIndicatorRequest 3 "SNA" 1 "RCM_PASSENGER_AIRBAG_INDICATOR_OFF" 0 "RCM_PASSENGER_AIRBAG_INDICATOR_ON" ;
VAL_ 529 RCM_airbagCutoffStatus 3 "SNA" 1 "RCM_PASSENGER_AIRBAG_DISABLED" 0 "RCM_PASSENGER_AIRBAG_ENABLED" ;
VAL_ 529 RCM_alrSwitchStatus 3 "SNA" 2 "RCM_ALR_FAULTED" 1 "RCM_ALR_ENGAGED" 0 "RCM_ALR_NOT_ENGAGED" ;
VAL_ 529 RCM_vinLearnFlag 3 "SNA" 2 "RCM_VIN_STORED_MISMATCH" 1 "RCM_VIN_STORED" 0 "RCM_VIN_NOT_STORED" ;
VAL_ 529 RCM_seatTrackPositionDrvr 3 "SNA" 2 "RCM_SEAT_POSITION_FAULTED" 1 "RCM_SEAT_POSITION_FAR" 0 "RCM_SEAT_POSITION_NEAR" ;
VAL_ 529 RCM_seatTrackPositionPass 3 "SNA" 2 "RCM_SEAT_POSITION_FAULTED" 1 "RCM_SEAT_POSITION_FAR" 0 "RCM_SEAT_POSITION_NEAR" ;
VAL_ 529 RCM_edr1State 3 "RCM_EDR_UNAVAILABLE" 2 "RCM_EDR_LOCKED" 1 "RCM_EDR_STORED" 0 "RCM_EDR_EMPTY" ;
VAL_ 529 RCM_edr2State 3 "RCM_EDR_UNAVAILABLE" 2 "RCM_EDR_LOCKED" 1 "RCM_EDR_STORED" 0 "RCM_EDR_EMPTY" ;
VAL_ 529 RCM_keepPowerReason 8 "RCM_KEEP_POWER_REASON_SNA" 7 "RCM_INVALID_POWER_OFF_REQUEST" 6 "RCM_INITIALIZATION_PHASE" 5 "RCM_CANNOT_POWER_DOWN" 4 "RCM_EDR_UPLOADING" 3 "RCM_EDR_STORING_TO_EEPROM" 2 "RCM_CRASH_ALGO_ACTIVE" 1 "RCM_IN_IDLE_MODE" 0 "RCM_NO_KEEP_POWER_REQUEST" ;
VAL_ 529 RCM_imuOffsetLearnState 3 "IMU_OFFSETS_UNABLE_TO_LEARN" 2 "IMU_FAST_LEARNING_TIME" 1 "IMU_SLOW_LEARNING_DISTANCE" 0 "IMU_OFFSET_LEARNING_OFF" ;
VAL_ 529 RCM_edr3State 3 "RCM_EDR_UNAVAILABLE" 2 "RCM_EDR_LOCKED" 1 "RCM_EDR_STORED" 0 "RCM_EDR_EMPTY" ;
VAL_ 529 RCM_driverOrientationInitStatus 7 "SNA" 4 "RCM_DRIVER_ORIENTATION_MISMATCH_DEFAULT_RHD" 3 "RCM_DRIVER_ORIENTATION_MISMATCH_DEFAULT_LHD" 2 "RCM_DRIVER_ORIENTATION_MATCHED_RHD" 1 "RCM_DRIVER_ORIENTATION_MATCHED_LHD" 0 "RCM_DRIVER_ORIENTATION_INIT_NOT_COMPLETE" ;
VAL_ 529 RCM_occupantClassificationSource 1 "VCRIGHT_CLASSIFICATION_SOURCE" 0 "OCS1P_CLASSIFICATION_SOURCE" ;
VAL_ 529 RCM_pedProEDR1State 3 "RCM_EDR_UNAVAILABLE" 2 "RCM_EDR_LOCKED" 1 "RCM_EDR_STORED" 0 "RCM_EDR_EMPTY" ;
VAL_ 529 RCM_pedProEDR2State 3 "RCM_EDR_UNAVAILABLE" 2 "RCM_EDR_LOCKED" 1 "RCM_EDR_STORED" 0 "RCM_EDR_EMPTY" ;
VAL_ 831 RCU_infoIndex 255 "END" 31 "SUBCOMPONENT_GITHASH" 30 "PACKAGE_SN_8_14" 29 "PACKAGE_SN_1_7" 27 "PACKAGE_PN_15_20" 26 "PACKAGE_PN_8_14" 25 "PACKAGE_PN_1_7" 23 "SUBCOMPONENT2" 22 "VARIANTCRC" 20 "UDS_PROTOCOL_BOOTCRC" 19 "VERSION_DEPRECATED" 18 "BOOTLOADER_GITHASH" 17 "APP_GITHASH" 16 "SUBCOMPONENT" 15 "BOOTLOADER_CRC" 14 "BOOTLOADER_SVN" 13 "APP_CRC" 11 "PCBAID_ASSYID_USAGEID" 10 "BUILD_HWID_COMPONENTID" 9 "DEPRECATED_9" 8 "DEPRECATED_8" 7 "DEPRECATED_7" 6 "DEPRECATED_6" 5 "DEPRECATED_5" 4 "DEPRECATED_4" 3 "DEPRECATED_3" 2 "DEPRECATED_2" 1 "DEPRECATED_1" 0 "DEPRECATED_0" ;
VAL_ 879 TPMS_learningStatus 3 "PASSED" 2 "STOPPED" 1 "ONGOING" 0 "FAILED" ;
VAL_ 879 TPMS_localisationStatus 3 "PASSED" 2 "STOPPED" 1 "ONGOING" 0 "FAILED" ;
VAL_ 799 TPMS_pressureFL 255 "SNA" 254 "OVER_RANGE" ;
VAL_ 799 TPMS_temperatureFL 255 "TPMS_TEMPERATURE_SNA" ;
VAL_ 799 TPMS_pressureFR 255 "SNA" 254 "OVER_RANGE" ;
VAL_ 799 TPMS_temperatureFR 255 "TPMS_TEMPERATURE_SNA" ;
VAL_ 799 TPMS_pressureRL 255 "SNA" 254 "OVER_RANGE" ;
VAL_ 799 TPMS_temperatureRL 255 "TPMS_TEMPERATURE_SNA" ;
VAL_ 799 TPMS_pressureRR 255 "SNA" 254 "OVER_RANGE" ;
VAL_ 799 TPMS_temperatureRR 255 "TPMS_TEMPERATURE_SNA" ;
VAL_ 1519 TPMS_infoIndex 255 "END" 31 "SUBCOMPONENT_GITHASH" 30 "PACKAGE_SN_8_14" 29 "PACKAGE_SN_1_7" 27 "PACKAGE_PN_15_20" 26 "PACKAGE_PN_8_14" 25 "PACKAGE_PN_1_7" 23 "SUBCOMPONENT2" 22 "VARIANTCRC" 20 "UDS_PROTOCOL_BOOTCRC" 19 "VERSION_DEPRECATED" 18 "BOOTLOADER_GITHASH" 17 "APP_GITHASH" 16 "SUBCOMPONENT" 15 "BOOTLOADER_CRC" 14 "BOOTLOADER_SVN" 13 "APP_CRC" 11 "PCBAID_ASSYID_USAGEID" 10 "BUILD_HWID_COMPONENTID" 9 "DEPRECATED_9" 8 "DEPRECATED_8" 7 "DEPRECATED_7" 6 "DEPRECATED_6" 5 "DEPRECATED_5" 4 "DEPRECATED_4" 3 "DEPRECATED_3" 2 "DEPRECATED_2" 1 "DEPRECATED_1" 0 "DEPRECATED_0" ;
VAL_ 659 UI_steeringTuneRequest 2 "STEERING_TUNE_SPORT" 1 "STEERING_TUNE_STANDARD" 0 "STEERING_TUNE_COMFORT" ;
VAL_ 659 UI_tractionControlMode 7 "TC_SLIPPERY_SURFACE_SELECTED" 6 "TC_OFFROAD_ASSIST_SELECTED" 5 "TC_DYNO_MODE_SELECTED" 4 "TC_ROLLS_MODE_SELECTED" 3 "TC_DEV_MODE_2_SELECTED" 2 "TC_DEV_MODE_1_SELECTED" 1 "TC_SLIP_START_SELECTED" 0 "TC_NORMAL_SELECTED" ;
VAL_ 659 UI_parkBrakeRequest 3 "PARK_BRAKE_REQUEST_SNA" 1 "PARK_BRAKE_REQUEST_PRESSED" 0 "PARK_BRAKE_REQUEST_IDLE" ;
VAL_ 659 UI_winchModeRequest 3 "WINCH_MODE_DIALOGUE_OPEN" 2 "WINCH_MODE_EXIT" 1 "WINCH_MODE_ENTER" 0 "WINCH_MODE_IDLE" ;
VAL_ 659 UI_zeroSpeedConfirmed 3 "SNA" 2 "UNUSED" 1 "CONFIRMED" 0 "CANCELED" ;
VAL_ 659 UI_trailerMode 1 "TRAILER_MODE_ON" 0 "TRAILER_MODE_OFF" ;
VAL_ 659 UI_distanceUnits 1 "MILES" 0 "KM" ;
VAL_ 659 UI_accOvertakeEnable 3 "SNA" 1 "ACC_OVERTAKE_ON" 0 "ACC_OVERTAKE_OFF" ;
VAL_ 659 UI_aebEnable 3 "SNA" 1 "AEB_ON" 0 "AEB_OFF" ;
VAL_ 659 UI_aesEnable 3 "SNA" 1 "AES_ON" 0 "AES_OFF" ;
VAL_ 659 UI_ahlbEnable 3 "SNA" 1 "AHLB_ON" 0 "AHLB_OFF" ;
VAL_ 659 UI_autoLaneChangeEnable 3 "SNA" 1 "ON" 0 "OFF" ;
VAL_ 659 UI_autoParkRequest 15 "SNA" 12 "BEGIN_PARKING" 11 "RESUME" 10 "PAUSE" 9 "SEARCH" 8 "COMPLETE" 7 "ABORT" 6 "PARALLEL_PULL_OUT_TO_RIGHT" 5 "PARALLEL_PULL_OUT_TO_LEFT" 4 "PARK_RIGHT_CROSS" 3 "PARK_RIGHT_PARALLEL" 2 "PARK_LEFT_CROSS" 1 "PARK_LEFT_PARALLEL" 0 "NONE" ;
VAL_ 659 UI_bsdEnable 3 "SNA" 1 "BSD_ON" 0 "BSD_OFF" ;
VAL_ 659 UI_fcwEnable 3 "SNA" 1 "FCW_ON" 0 "FCW_OFF" ;
VAL_ 659 UI_fcwSensitivity 3 "SNA" 2 "AEB_SENSITIVITY_LATE" 1 "AEB_SENSITIVITY_AVERAGE" 0 "AEB_SENSITIVITY_EARLY" ;
VAL_ 659 UI_latControlEnable 3 "LATERAL_CONTROL_SNA" 2 "LATERAL_CONTROL_UNAVAILABLE" 1 "LATERAL_CONTROL_ON" 0 "LATERAL_CONTROL_OFF" ;
VAL_ 659 UI_ldwEnable 3 "SNA" 1 "LDW_TRIGGERS_HAPTIC" 0 "NO_HAPTIC" ;
VAL_ 659 UI_pedalSafetyEnable 3 "SNA" 1 "PEDAL_SAFETY_ON" 0 "PEDAL_SAFETY_OFF" ;
VAL_ 659 UI_pedalMap_epas 2 "PERFORMANCE" 1 "SPORT" 0 "CHILL" ;
VAL_ 659 UI_redLightStopSignEnable 3 "SNA" 1 "RLSSW_ON" 0 "RLSSW_OFF" ;
VAL_ 659 UI_selfParkTune 15 "SNA" ;
VAL_ 1096 UI_anonDebugFlag1 1 "ON" 0 "OFF" ;
VAL_ 1096 UI_anonDebugFlag2 1 "ON" 0 "OFF" ;
VAL_ 1096 UI_anonDebugFlag3 1 "ON" 0 "OFF" ;
VAL_ 1096 UI_anonDebugFlag4 1 "ON" 0 "OFF" ;
VAL_ 1016 UI_autopilotControlRequest 1 "NEXT_GEN_CTRL" 0 "LEGACY_LAT_CTRL" ;
VAL_ 1016 UI_curvSpeedAdaptDisable 1 "OFF" 0 "ON" ;
VAL_ 1016 UI_lssLkaEnabled 1 "LKA_ON" 0 "LKA_OFF" ;
VAL_ 1016 UI_lssLdwEnabled 1 "LDW_ON" 0 "LDW_OFF" ;
VAL_ 1016 UI_exceptionListEnable 1 "ON" 0 "OFF" ;
VAL_ 1016 UI_roadCheckDisable 1 "OFF" 0 "ON" ;
VAL_ 1016 UI_driveOnMapsEnable 1 "DOM_ON" 0 "DOM_OFF" ;
VAL_ 1016 UI_handsOnRequirementDisable 1 "OFF" 0 "ON" ;
VAL_ 1016 UI_fuseLanesDisable 1 "OFF" 0 "ON" ;
VAL_ 1016 UI_fuseHPPDisable 1 "OFF" 0 "ON" ;
VAL_ 1016 UI_fuseVehiclesDisable 1 "OFF" 0 "ON" ;
VAL_ 1016 UI_visionSpeedType 3 "OPTIMIZED" 2 "TWO_SECOND" 1 "ONE_SECOND" 0 "DISABLED" ;
VAL_ 1016 UI_curvatureDatabaseOnly 1 "ON" 0 "OFF" ;
VAL_ 1016 UI_lssElkEnabled 1 "ELK_ON" 0 "ELK_OFF" ;
VAL_ 1016 UI_summonExitType 3 "SNA" 2 "TURN_LEFT" 1 "TURN_RIGHT" 0 "STRAIGHT" ;
VAL_ 1016 UI_summonEntryType 3 "SNA" 2 "TURN_LEFT" 1 "TURN_RIGHT" 0 "STRAIGHT" ;
VAL_ 1016 UI_selfParkRequest 15 "SNA" 12 "SMART_SUMMON_NO_OP" 11 "SMART_SUMMON" 10 "AUTO_SUMMON_PRIMED" 9 "AUTO_SUMMON_CANCEL" 8 "AUTO_SUMMON_REVERSE" 7 "AUTO_SUMMON_FORWARD" 6 "RESUME" 5 "PAUSE" 4 "PRIME" 3 "ABORT" 2 "SELF_PARK_REVERSE" 1 "SELF_PARK_FORWARD" 0 "NONE" ;
VAL_ 1016 UI_summonReverseDist 63 "SNA" ;
VAL_ 1016 UI_drivingSide 2 "UNKNOWN" 1 "RIGHT" 0 "LEFT" ;
VAL_ 1016 UI_accFollowDistanceSetting 7 "SNA" 6 "7" 5 "6" 4 "5" 3 "4" 2 "3" 1 "2" 0 "1" ;
VAL_ 1016 UI_followNavRouteEnable 1 "NAV_ROUTE_ON" 0 "NAV_ROUTE_OFF" ;
VAL_ 1016 UI_ulcSpeedConfig 3 "SPEED_BASED_ULC_MAD_MAX" 2 "SPEED_BASED_ULC_AVERAGE" 1 "SPEED_BASED_ULC_MILD" 0 "SPEED_BASED_ULC_DISABLED" ;
VAL_ 1016 UI_ulcBlindSpotConfig 2 "MAD_MAX" 1 "AGGRESSIVE" 0 "STANDARD" ;
VAL_ 1016 UI_smartSummonType 2 "SMART_AUTOPARK" 1 "FIND_ME" 0 "PIN_DROP" ;
VAL_ 1016 UI_source3D 2 "XYZ_PREDICTION" 1 "Z_FROM_PATH_PREDICTION" 0 "Z_FROM_MAP" ;
VAL_ 568 UI_mapSpeedLimitDependency 7 "SNA" 6 "LANE" 5 "SEASON" 4 "TIME" 3 "SNOW" 2 "RAIN" 1 "SCHOOL" 0 "NONE" ;
VAL_ 568 UI_roadClass 6 "CLASS_6_MINOR" 5 "CLASS_5" 4 "CLASS_4" 3 "CLASS_3" 2 "CLASS_2" 1 "CLASS_1_MAJOR" 0 "UNKNOWN_INVALID_SNA" ;
VAL_ 568 UI_mapSpeedUnits 1 "KPH" 0 "MPH" ;
VAL_ 568 UI_mapSpeedLimit 31 "SNA" 30 "UNLIMITED" 29 "LESS_OR_EQ_160" 28 "LESS_OR_EQ_150" 27 "LESS_OR_EQ_140" 26 "LESS_OR_EQ_130" 25 "LESS_OR_EQ_120" 24 "LESS_OR_EQ_115" 23 "LESS_OR_EQ_110" 22 "LESS_OR_EQ_105" 21 "LESS_OR_EQ_100" 20 "LESS_OR_EQ_95" 19 "LESS_OR_EQ_90" 18 "LESS_OR_EQ_85" 17 "LESS_OR_EQ_80" 16 "LESS_OR_EQ_75" 15 "LESS_OR_EQ_70" 14 "LESS_OR_EQ_65" 13 "LESS_OR_EQ_60" 12 "LESS_OR_EQ_55" 11 "LESS_OR_EQ_50" 10 "LESS_OR_EQ_45" 9 "LESS_OR_EQ_40" 8 "LESS_OR_EQ_35" 7 "LESS_OR_EQ_30" 6 "LESS_OR_EQ_25" 5 "LESS_OR_EQ_20" 4 "LESS_OR_EQ_15" 3 "LESS_OR_EQ_10" 2 "LESS_OR_EQ_7" 1 "LESS_OR_EQ_5" 0 "UNKNOWN" ;
VAL_ 568 UI_mapSpeedLimitType 7 "UNKNOWN_SNA" 4 "BUMPS" 3 "DEPENDENT" 2 "ADVISORY" 1 "REGULAR" ;
VAL_ 568 UI_countryCode 1023 "SNA" 0 "UNKNOWN" ;
VAL_ 568 UI_nextBranchDist 31 "SNA" ;
VAL_ 536 UI_roadSign 255 "SNA" 5 "SPLINE_ID_FULL" 4 "SPEED_SPLINE" 3 "SPEED_LIMIT" 2 "TRAFFIC_LIGHT" 1 "STOP_SIGN" 0 "NONE" ;
VAL_ 536 UI_splineLocConfidence 0 "SNA" ;
VAL_ 536 UI_stopSignStopLineDist 1023 "SNA" ;
VAL_ 536 UI_stopSignStopLineConf 0 "SNA" ;
VAL_ 536 UI_trafficLightStopLineDist 1023 "SNA" ;
VAL_ 536 UI_trafficLightStopLineConf 0 "SNA" ;
VAL_ 536 UI_baseMapSpeedLimitMPS 255 "SNA" ;
VAL_ 536 UI_bottomQrtlFleetSpeedMPS 255 "SNA" ;
VAL_ 536 UI_topQrtlFleetSpeedMPS 255 "SNA" ;
VAL_ 536 UI_meanFleetSplineSpeedMPS 255 "SNA" ;
VAL_ 536 UI_medianFleetSpeedMPS 255 "SNA" ;
VAL_ 536 UI_meanFleetSplineAccelMPS2 255 "SNA" ;
VAL_ 536 UI_rampType 4 "INTERCHANGE_EXIT" 3 "INTERCHANGE_ENTRANCE" 2 "EXIT" 1 "ENTRANCE" 0 "NONE_SNA" ;
VAL_ 536 UI_valhallaRamp 2 "ON_RAMP" 1 "NOT_ON_RAMP" 0 "SNA" ;
VAL_ 536 UI_currSplineIdFull 0 "SNA" ;
VAL_ 760 UI_mapSpeedLimitUnits 1 "KPH" 0 "MPH" ;
VAL_ 760 UI_userSpeedOffsetUnits 1 "KPH" 0 "MPH" ;
VAL_ 760 UI_conditionalSpeedLimit 31 "SNA" ;
VAL_ 777 UI_gpsAccuracy 127 "SNA" ;
VAL_ 1011 UI_odometer 16777215 "SNA" ;
VAL_ 987 UI_phoneGpsAccuracy 127 "SNA" ;
VAL_ 698 UI_radarTargetDx 255 "NO_OBJECT" ;
VAL_ 698 UI_radarTargetDxEnd 255 "NO_OBJECT" ;
VAL_ 632 UI_roadCurvHealth 3 "DATABASE" 2 "AVAILABLE" 1 "DEGRADED" 0 "UNAVAILABLE" ;
VAL_ 723 UI_solarAzimuthAngle -32768 "SNA" ;
VAL_ 723 UI_solarAzimuthAngleCarRef 255 "SNA" ;
VAL_ 723 UI_isSunUp 3 "SUN_SNA" 1 "SUN_UP" 0 "SUN_DOWN" ;
VAL_ 723 UI_solarElevationAngle 127 "SNA" ;
VAL_ 851 UI_autopilotTrial 3 "ACTIVE" 2 "STOP" 1 "START" 0 "NONE" ;
VAL_ 851 UI_factoryReset 3 "CUSTOMER" 2 "DIAGNOSTIC" 1 "DEVELOPER" 0 "NONE_SNA" ;
VAL_ 851 UI_cellNetworkTechnology 15 "CELL_NETWORK_SNA" 14 "CELL_NETWORK_NGRAN" 13 "CELL_NETWORK_5GSA" 12 "CELL_NETWORK_5GNSA" 11 "CELL_NETWORK_LTE5GCN" 10 "CELL_NETWORK_WCDMA" 9 "CELL_NETWORK_CDMA" 8 "CELL_NETWORK_GSM" 7 "CELL_NETWORK_LTE" 6 "CELL_NETWORK_HSPA" 5 "CELL_NETWORK_HSUPA" 4 "CELL_NETWORK_HSDPA" 3 "CELL_NETWORK_UMTS" 2 "CELL_NETWORK_EDGE" 1 "CELL_NETWORK_GPRS" 0 "CELL_NETWORK_NONE" ;
VAL_ 851 UI_cellSignalBars 7 "SNA" 5 "FIVE" 4 "FOUR" 3 "THREE" 2 "TWO" 1 "ONE" 0 "ZERO" ;
VAL_ 851 UI_trailerModeTelltale 3 "TRAILER_MODE_TELLTALE_RED" 2 "TRAILER_MODE_TELLTALE_YELLOW" 1 "TRAILER_MODE_TELLTALE_BLUE" 0 "TRAILER_MODE_TELLTALE_OFF" ;
VAL_ 856 UI_TPMSMode 2 "PERFORMANCE_MODE" 1 "NORMAL_MODE" 0 "UNUSED_MODE" ;
VAL_ 856 UI_TPMSLearnIDMode 4 "AUTO_LOCATION_ACTIVE_AFTER_PWR" 3 "AUTO_LEARN_ACTIVE_AFTER_PWR" 2 "AUTO_LOCATION_ACTIVE_BY_MANUAL" 1 "AUTO_LEARN_ACTIVE_BY_MANUAL" 0 "NO_ID_LEARN_FUNCTION" ;
VAL_ 856 UI_sizeOfWheelSelect 2 "19_INCH_WHEEL" 1 "18_INCH_WHEEL" 0 "UNUSED" ;
VAL_ 1827 UI_ussSensorIdX 5 "FRONT_SIDE" 4 "FRONT_CORNER" 3 "FRONT_INNER" 2 "REAR_SIDE" 1 "REAR_CORNER" 0 "REAR_INNER" ;
VAL_ 1829 UI_ussSensorIdY 5 "FRONT_SIDE" 4 "FRONT_CORNER" 3 "FRONT_INNER" 2 "REAR_SIDE" 1 "REAR_CORNER" 0 "REAR_INNER" ;
VAL_ 954 USM_matrixIndex 4 "AlertMatrix4" 3 "AlertMatrix3" 2 "AlertMatrix2" 1 "AlertMatrix1" 0 "AlertMatrix0" ;
VAL_ 807 USM_infoIndex 255 "END" 41 "SUBCOMPONENT14" 40 "SUBCOMPONENT13" 39 "SUBCOMPONENT12" 38 "SUBCOMPONENT11" 37 "SUBCOMPONENT10" 36 "SUBCOMPONENT9" 35 "SUBCOMPONENT8" 34 "SUBCOMPONENT7" 33 "SUBCOMPONENT6" 32 "SUBCOMPONENT5" 31 "SUBCOMPONENT4" 24 "SUBCOMPONENT3" 23 "SUBCOMPONENT2" 20 "UDS_PROTOCOL_BOOTCRC" 19 "VERSION_DEPRECATED" 18 "BOOTLOADER_GITHASH" 17 "APP_GITHASH" 16 "SUBCOMPONENT1" 15 "BOOTLOADER_CRC" 14 "BOOTLOADER_SVN" 13 "APP_CRC" 11 "PCBAID_ASSYID_USAGEID" 10 "BUILD_HWID_COMPONENTID" 9 "DEPRECATED_9" 8 "DEPRECATED_8" 7 "DEPRECATED_7" 6 "DEPRECATED_6" 5 "DEPRECATED_5" 4 "DEPRECATED_4" 3 "DEPRECATED_3" 2 "DEPRECATED_2" 1 "DEPRECATED_1" 0 "DEPRECATED_0" ;
VAL_ 807 USM_infoBuildType 4 "INFO_MFG_BUILD" 3 "INFO_TRACEABLE_CI_BUILD" 2 "INFO_LOCAL_BUILD" 1 "INFO_PLATFORM_BUILD" 0 "INFO_UNKNOWN_BUILD" ;
VAL_ 807 USM_infoAssemblyId 255 "ASSEMBLY_SNA" 1 "ASSEMBLY1" ;
